VERSION ""

NS_ :

BS_:

BU_: BCM BSM2 CADM2 CVADAS EPS ORC PAM SGW TRSKM

BO_ 1051 BCM_FD_4: 32 BCM
 SG_ ExternalTemperatureAD_Voltage : 159|8@0+ (0.019607843,0) [0|4.98] "Volt" Vector__XXX
 SG_ FUEL_VOLT : 143|8@0+ (0.019607843,0) [0|4.98] "Volt" Vector__XXX

BO_ 1375 BCM_FD_6: 32 BCM
 SG_ ChkFuelLevelSts : 99|3@0+ (1,0) [0|7] "-" Vector__XXX
 SG_ FrontWiperReq : 75|4@0+ (1,0) [0|5] "" Vector__XXX

BO_ 1827 BCM_FD_7: 32 BCM
 SG_ CRC_BCM7 : 191|8@0+ (1,0) [0|255] "-"  BSM2
 SG_ IgnitionOnCounter : 95|16@0+ (1,0) [0|65535] "-"  BSM2,CADM2,CVADAS,EPS,ORC,PAM,TRSKM
 SG_ MessageCounter_BCM7 : 179|4@0+ (1,0) [0|15] "-"  BSM2

BO_ 1066 BCM_FD_9: 32 BCM
 SG_ BonnetSts : 182|1@0+ (1,0) [0|1] "-"  ORC
 SG_ BrakeFluidLevelSts : 181|1@0+ (1,0) [0|1] "-"  BSM2
 SG_ CRC_BCM9 : 191|8@0+ (1,0) [0|255] "-"  CADM2,CVADAS
 SG_ DoorLockLastElSts : 51|2@0+ (1,0) [0|3] ""  ORC
 SG_ DriverDoorSts : 35|1@0+ (1,0) [0|1] "-"  CVADAS,ORC
 SG_ ExternalTemperature : 0|9@0+ (0.5,-85) [-85|170] "°C"  CVADAS,ORC,PAM
 SG_ FrontWiperMoveSts : 60|1@0+ (1,0) [0|1] "" Vector__XXX
 SG_ FuelLevel : 135|8@0+ (1,0) [0|255] "%"  ORC
 SG_ HDCFnRqstSts : 4|2@0+ (1,0) [0|2] ""  ORC
 SG_ HighBeamSts : 97|1@0+ (1,0) [0|1] "-"  ORC
 SG_ LHRDoorSts : 32|1@0+ (1,0) [0|1] "-"  CVADAS,ORC
 SG_ LowBeamSts : 72|1@0+ (1,0) [0|1] ""  ORC
 SG_ LowFuelWarningSts : 47|1@0+ (1,0) [0|1] "-" Vector__XXX
 SG_ MessageCounter_BCM9 : 179|4@0+ (1,0) [0|15] "-"  CADM2,CVADAS
 SG_ ParkBrakeSts : 180|1@0+ (1,0) [0|1] "-"  ORC
 SG_ PowerModeSts : 161|2@0+ (1,0) [0|3] ""  CADM2
 SG_ PsngrDoorSts : 46|1@0+ (1,0) [0|1] "-"  CVADAS,ORC
 SG_ RHatchSts : 43|1@0+ (1,0) [0|1] "-"  CVADAS,ORC,SGW
 SG_ RHRDoorSts : 42|1@0+ (1,0) [0|1] "-"  CVADAS,ORC
 SG_ StopLightFault : 108|1@0+ (1,0) [0|1] "-"  ORC
 SG_ StopLightSts : 88|1@0+ (1,0) [0|1] "-" Vector__XXX

BO_ 513 BRAKE_FD_1: 32 BCM
 SG_ ACCFSafe : 7|8@0+ (1,0) [0|255] "-"  CADM2
 SG_ BrkTrq : 94|15@0+ (3,0) [0|98301] "Nm"  ORC
 SG_ BrkTrq_Driver : 150|15@0+ (3,0) [0|98301] "Nm"  CADM2,ORC
 SG_ CRC_BRAKE1 : 191|8@0+ (1,0) [0|255] "-"  CVADAS,BSM2,CADM2,ORC
 SG_ MessageCounter_BRAKE1 : 179|4@0+ (1,0) [0|15] "-"  CVADAS,BSM2,CADM2,ORC
 SG_ REF_VEH_SPEED : 57|10@0+ (0.5,0) [0|511] "kph"  CVADAS,ORC
 SG_ SelSpdLmp : 59|2@0+ (1,0) [0|0] "-"  ORC
 SG_ VehicleStandStillSts : 111|2@0+ (1,0) [0|2] "-"  BSM2,CADM2,CVADAS

BO_ 258 BRAKE_FD_2: 64 BCM
 SG_ ABSActive : 83|1@0+ (1,0) [0|1] "-"  ORC
 SG_ BrakeBoostPressure : 370|11@0+ (0.1,0) [0|200] "bar"  ORC
 SG_ BrakeInterventionSts : 103|1@0+ (1,0) [0|1] "-"  ORC
 SG_ BrakePedalPressure : 386|11@0+ (0.1,0) [0|200] "bar"  ORC
 SG_ Brk_Stat : 343|2@0+ (1,0) [0|2] "-"  CVADAS,ORC,PAM
 SG_ BSM_ESASystemSts : 239|3@0+ (1,0) [0|6] ""  EPS
 SG_ CRC_BRAKE2 : 447|8@0+ (1,0) [0|255] "-"  BSM2,CADM2,CVADAS,EPS,ORC,PAM
 SG_ ESCActive : 84|1@0+ (1,0) [0|1] "-"  ORC
 SG_ HBAActive : 101|1@0+ (1,0) [0|1] "-"  ORC
 SG_ HillHolderActive : 174|1@0+ (1,0) [0|1] "-"  ORC
 SG_ InternalError_BSM : 191|1@0+ (1,0) [0|1] "-"  CADM2
 SG_ LatAcceleration_BSM : 19|12@0+ (0.02,-40.96) [-40.96|40.92] "m/s^2"  CADM2,CVADAS,EPS,PAM
 SG_ LatAccelerationFailSts_BSM : 68|1@0+ (1,0) [0|1] "-"  PAM
 SG_ LongAcceleration_BSM : 35|12@0+ (0.02,-40.96) [-40.96|40.92] "m/s^2"  CADM2,CVADAS,EPS,PAM
 SG_ LongAccelerationFailSts_BSM : 69|1@0+ (1,0) [0|1] "-"  PAM
 SG_ MessageCounter_BRAKE2 : 435|4@0+ (1,0) [0|15] "-"  BSM2,CADM2,CVADAS,EPS,ORC,PAM
 SG_ VehicleSpeedVSOSig : 4|13@0+ (0.0625,0) [0|511.875] "Km/h"  BSM2,CADM2,CVADAS,EPS,ORC,PAM,TRSKM
 SG_ WheelRPM_FL : 279|16@0+ (0.001953125,0) [0|127.9961] "Rev/s"  EPS
 SG_ WheelRPM_FR : 295|16@0+ (0.001953125,0) [0|127.9961] "Rev/s"  EPS
 SG_ YawRate_BSM : 67|12@0+ (0.08,-163.84) [-163.84|163.68] "deg/s"  CVADAS,EPS,ORC,PAM
 SG_ YawRateFailSts_BSM : 87|1@0+ (1,0) [0|1] "-"  EPS,PAM

BO_ 259 BRAKE_FD_3: 32 BCM
 SG_ CRC__BRAKE3 : 191|8@0+ (1,0) [0|255] "-"  BSM2,CADM2,CVADAS,EPS,ORC,PAM
 SG_ LatAccelerationOffset_BSM : 127|8@0+ (0.02,-2.56) [-2.56|2.52] "m/s^2"  CVADAS
 SG_ LHF_FastPulseCounter : 167|8@0+ (1,0) [0|255] "pulse"  CADM2,CVADAS,EPS,PAM
 SG_ LHF_Spin : 23|2@0+ (1,0) [0|3] "-"  BSM2,CADM2,CVADAS,EPS,PAM
 SG_ LHF_WheelSensorFailSts : 181|1@0+ (1,0) [0|1] "-"  BSM2,CADM2,EPS,ORC,PAM
 SG_ LHFWheelSpeed : 20|13@0+ (0.0625,0) [0|511.875] "Km/h"  BSM2,CADM2,CVADAS,EPS,ORC,PAM
 SG_ LHR_FastPulseCounter : 151|8@0+ (1,0) [0|255] "pulse"  CADM2,CVADAS,EPS,PAM
 SG_ LHR_Spin : 86|2@0+ (1,0) [0|3] "-"  BSM2,CADM2,CVADAS
 SG_ LHR_WheelSensorFailSts : 87|1@0+ (1,0) [0|1] "-"  BSM2,CADM2,EPS,ORC,PAM
 SG_ LHRWheelSpeed : 4|13@0+ (0.0625,0) [0|511.875] "Km/h"  BSM2,CADM2,CVADAS,EPS,ORC,PAM
 SG_ LongAccelerationOffset_BSM : 119|8@0+ (0.02,-2.56) [-2.56|2.52] "m/s^2"  CVADAS
 SG_ MessageCounter_BRAKE3 : 179|4@0+ (1,0) [0|15] "-"  BSM2,CADM2,CVADAS,EPS,ORC,PAM
 SG_ RHF_FastPulseCounter : 175|8@0+ (1,0) [0|255] "pulse"  CADM2,CVADAS,EPS,PAM
 SG_ RHF_Spin : 7|2@0+ (1,0) [0|3] "-"  BSM2,CADM2,CVADAS,EPS,PAM
 SG_ RHF_WheelSensorFailSts : 182|1@0+ (1,0) [0|1] "-"  BSM2,CADM2,EPS,ORC,PAM
 SG_ RHFWheelSpeed : 52|13@0+ (0.0625,0) [0|511.875] "Km/h"  BSM2,CADM2,CVADAS,EPS,ORC,PAM
 SG_ RHR_FastPulseCounter : 159|8@0+ (1,0) [0|255] "pulse"  CADM2,CVADAS,EPS,PAM
 SG_ RHR_Spin : 102|2@0+ (1,0) [0|3] "-"  BSM2,CADM2,CVADAS
 SG_ RHR_WheelSensorFailSts : 103|1@0+ (1,0) [0|1] "-"  BSM2,CADM2,EPS,ORC,PAM
 SG_ RHRWheelSpeed : 68|13@0+ (0.0625,0) [0|511.875] "Km/h"  BSM2,CADM2,CVADAS,EPS,ORC,PAM

BO_ 609 BRAKE_FD_4: 32 BCM
 SG_ ClampForce : 88|9@0+ (0.1,-0.1) [0|51] "KN"  ORC
 SG_ CRC_BRAKE4 : 191|8@0+ (1,0) [0|255] "-"  CVADAS,BSM2,CADM2
 SG_ EPBSts : 115|4@0+ (1,0) [0|14] "-"  BSM2,CADM2,CVADAS,EPS,ORC,PAM
 SG_ EPBSwitchPosition : 119|2@0+ (1,0) [0|3] "-"  ORC
 SG_ EPBWarningLampReq : 174|2@0+ (1,0) [0|0] "-"  ORC
 SG_ ESC_OFF_Hrd_Sft_Button_sts : 151|3@0+ (1,0) [0|6] "-"  ORC
 SG_ MessageCounter_BRAKE4 : 179|4@0+ (1,0) [0|15] "-"  CVADAS,BSM2,CADM2
 SG_ MSRActive : 92|1@0+ (1,0) [0|1] "-"  ORC

BO_ 1155 BRAKE_FD_5: 32 BCM
 SG_ ABSFailSts : 87|1@0+ (1,0) [0|1] "-"  ORC
 SG_ BSM_THA_Brk_Resp : 15|2@0+ (1,0) [0|3] "-"  CVADAS
 SG_ CRC_BRAKE5 : 191|8@0+ (1,0) [0|255] "-"  CVADAS
 SG_ EBDFailSts : 84|1@0+ (1,0) [0|1] "-"  ORC
 SG_ ERMActive : 111|1@0+ (1,0) [0|1] "-"  ORC
 SG_ ESCFailSts : 83|1@0+ (1,0) [0|1] "-"  ORC
 SG_ ESCIntervention : 82|1@0+ (1,0) [0|1] "-"  ORC
 SG_ Function2Sts : 94|1@0+ (1,0) [0|1] "-"  ORC
 SG_ MessageCounter_BRAKE5 : 179|4@0+ (1,0) [0|15] "-"  CVADAS
 SG_ TSCActive : 110|1@0+ (1,0) [0|1] "-"  ORC

BO_ 514 BRAKE_FD_7: 32 BCM
 SG_ BrakePdlPosn : 63|8@0+ (0.4,0) [0|100] "%"  ORC
 SG_ BrkPdl_Flt : 86|1@0+ (1,0) [0|1] "-"  ORC
 SG_ BrkPdl_Stat : 85|2@0+ (1,0) [0|2] "-"  BSM2,CADM2,ORC
 SG_ BSM_OpStat : 74|3@0+ (1,0) [0|5] ""  BSM2
 SG_ BSM_ReadyForESS : 181|2@0+ (1,0) [0|2] "-"  ORC
 SG_ CRC_BRAKE7 : 191|8@0+ (1,0) [0|255] "-"  BSM2,CADM2
 SG_ MessageCounter_BRAKE7 : 179|4@0+ (1,0) [0|15] "-"  BSM2,CADM2
 SG_ PAM_Brk_Rq_RspSts : 28|2@0+ (1,0) [0|3] "-"  PAM
 SG_ Rear_Diff_BSM_RQ : 77|2@0+ (1,0) [0|2] "-"  ORC

BO_ 257 BRAKE2_FD_1: 64 BSM2
 SG_ ABSActive_B2 : 37|1@0+ (1,0) [0|1] ""  CADM2
 SG_ Brk_Stat_B2 : 71|2@0+ (1,0) [0|2] ""  BCM,CADM2
 SG_ CRC_BRAKE2_1 : 447|8@0+ (1,0) [0|255] "-"  BCM,CADM2,CVADAS,EPS,ORC
 SG_ Ft_RrAxleCoupling_TrqRq_B2 : 143|8@0+ (12,0) [0|3060] "Nm"  BCM
 SG_ Ft_RrTrqCoupling_ModeRq_B2 : 158|2@0+ (1,0) [0|3] "-"  BCM
 SG_ Inlet_Pressure_Pos : 98|2@0+ (1,0) [0|2] ""  CADM2
 SG_ LHF_FastPulseCounter_B2 : 87|8@0+ (1,0) [0|255] "pulse"  CADM2
 SG_ LHF_Spin_B2 : 39|2@0+ (1,0) [0|3] ""  CADM2
 SG_ LHF_WheelSensorFailSts_B2 : 53|1@0+ (1,0) [0|1] ""  CADM2
 SG_ LHFWheelSpeed_B2 : 52|13@0+ (0.0625,0) [0|511.875] "Km/h"  CADM2
 SG_ MessageCounter_BRAKE2_1 : 435|4@0+ (1,0) [0|15] "-"  BCM,CADM2,CVADAS,EPS,ORC
 SG_ R_DIFF_TRQ_RQ_B2 : 151|9@0+ (10,0) [0|5100] "Nm" Vector__XXX
 SG_ Rear_Diff_BSM_RQ_B2 : 156|2@0+ (1,0) [0|2] "-" Vector__XXX
 SG_ RHF_FastPulseCounter_B2 : 95|8@0+ (1,0) [0|255] "pulse"  CADM2
 SG_ RHF_Spin_B2 : 55|2@0+ (1,0) [0|3] ""  CADM2
 SG_ RHF_WheelSensorFailSts_B2 : 69|1@0+ (1,0) [0|1] ""  CADM2
 SG_ RHFWheelSpeed_B2 : 68|13@0+ (0.0625,0) [0|511.875] "Km/h"  CADM2
 SG_ VehicleSpeedVSOSig_B2 : 36|13@0+ (0.0625,0) [0|511.875] "Km/h"  CADM2,EPS

BO_ 524 BRAKE2_FD_2: 32 BSM2
 SG_ AEB_Type_Brk_B2 : 43|4@0+ (1,0) [0|15] ""  CADM2
 SG_ Brake_OpStat_Sec : 53|3@0+ (1,0) [0|5] ""  BCM,CADM2,ORC
 SG_ BrkTrq_B2 : 6|15@0+ (3,0) [0|98301] "Nm"  CADM2
 SG_ BSM2_Long_DTO : 23|1@0+ (1,0) [0|1] ""  CADM2
 SG_ BSM2_OpStat : 50|3@0+ (1,0) [0|5] ""  BCM,CADM2
 SG_ CRC_BRAKE2_2 : 191|8@0+ (1,0) [0|255] "-"  BCM,CADM2,ORC
 SG_ MessageCounter_BRAKE2_2 : 179|4@0+ (1,0) [0|15] "-"  BCM,CADM2,ORC
 SG_ VehicleStandStillSts_B2 : 47|2@0+ (1,0) [0|2] ""  BCM,CADM2

BO_ 1156 BRAKE2_FD_3: 32 BSM2
 SG_ ABSFailSts_B2 : 7|1@0+ (1,0) [0|1] ""  CADM2
 SG_ CRC_BRAKE2_3 : 191|8@0+ (1,0) [0|255] "-"  CADM2,ORC
 SG_ MessageCounter_BRAKE2_3 : 179|4@0+ (1,0) [0|15] "-"  CADM2,ORC
 SG_ RollsModeAct_B2 : 6|1@0+ (1,0) [0|1] ""  CADM2

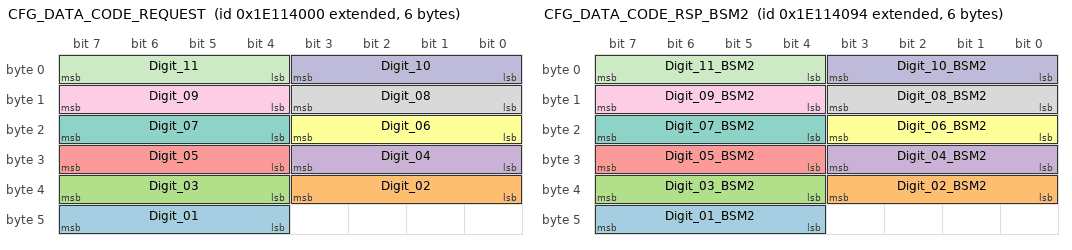
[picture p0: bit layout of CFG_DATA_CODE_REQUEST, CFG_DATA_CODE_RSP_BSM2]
BO_ 2651930624 CFG_DATA_CODE_REQUEST: 6 BCM
 SG_ Digit_01 : 47|4@0+ (1,0) [0|15] ""  BSM2,CADM2,CVADAS,EPS,ORC,PAM,TRSKM
 SG_ Digit_02 : 35|4@0+ (1,0) [0|15] ""  BSM2,CADM2,CVADAS,EPS,ORC,PAM,TRSKM
 SG_ Digit_03 : 39|4@0+ (1,0) [0|15] ""  BSM2,CADM2,CVADAS,EPS,ORC,PAM,TRSKM
 SG_ Digit_04 : 27|4@0+ (1,0) [0|15] ""  BSM2,CADM2,CVADAS,EPS,ORC,PAM,TRSKM
 SG_ Digit_05 : 31|4@0+ (1,0) [0|15] ""  BSM2,CADM2,CVADAS,EPS,ORC,PAM,TRSKM
 SG_ Digit_06 : 19|4@0+ (1,0) [0|15] ""  BSM2,CADM2,CVADAS,EPS,ORC,PAM,TRSKM
 SG_ Digit_07 : 23|4@0+ (1,0) [0|15] ""  BSM2,CADM2,CVADAS,EPS,ORC,PAM,TRSKM
 SG_ Digit_08 : 11|4@0+ (1,0) [0|15] ""  BSM2,CADM2,CVADAS,EPS,ORC,PAM,TRSKM
 SG_ Digit_09 : 15|4@0+ (1,0) [0|15] ""  BSM2,CADM2,CVADAS,EPS,ORC,PAM,TRSKM
 SG_ Digit_10 : 3|4@0+ (1,0) [0|15] ""  BSM2,CADM2,CVADAS,EPS,ORC,PAM,TRSKM
 SG_ Digit_11 : 7|4@0+ (1,0) [0|15] ""  BSM2,CADM2,CVADAS,EPS,ORC,PAM,TRSKM

BO_ 2651930772 CFG_DATA_CODE_RSP_BSM2: 6 BSM2
 SG_ Digit_01_BSM2 : 47|4@0+ (1,0) [0|15] "-"  BCM
 SG_ Digit_02_BSM2 : 35|4@0+ (1,0) [0|15] "-"  BCM
 SG_ Digit_03_BSM2 : 39|4@0+ (1,0) [0|15] "-"  BCM
 SG_ Digit_04_BSM2 : 27|4@0+ (1,0) [0|15] "-"  BCM
 SG_ Digit_05_BSM2 : 31|4@0+ (1,0) [0|15] "-"  BCM
 SG_ Digit_06_BSM2 : 19|4@0+ (1,0) [0|15] "-"  BCM
 SG_ Digit_07_BSM2 : 23|4@0+ (1,0) [0|15] "-"  BCM
 SG_ Digit_08_BSM2 : 11|4@0+ (1,0) [0|15] "-"  BCM
 SG_ Digit_09_BSM2 : 15|4@0+ (1,0) [0|15] "-"  BCM
 SG_ Digit_10_BSM2 : 3|4@0+ (1,0) [0|15] "-"  BCM
 SG_ Digit_11_BSM2 : 7|4@0+ (1,0) [0|15] "-"  BCM

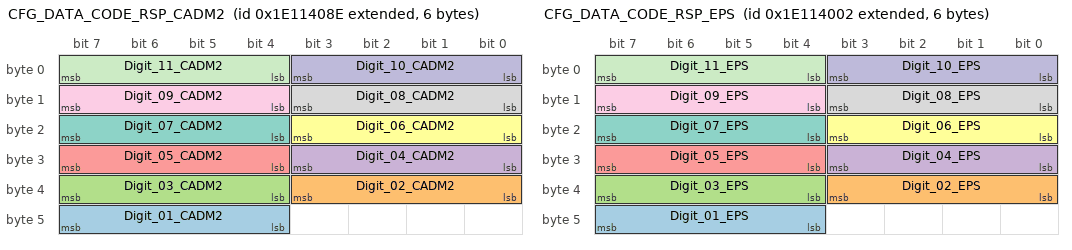
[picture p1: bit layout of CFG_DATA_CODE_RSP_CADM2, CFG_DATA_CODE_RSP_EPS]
BO_ 2651930766 CFG_DATA_CODE_RSP_CADM2: 6 CADM2
 SG_ Digit_01_CADM2 : 47|4@0+ (1,0) [0|15] "-"  BCM
 SG_ Digit_02_CADM2 : 35|4@0+ (1,0) [0|15] "-"  BCM
 SG_ Digit_03_CADM2 : 39|4@0+ (1,0) [0|15] "-"  BCM
 SG_ Digit_04_CADM2 : 27|4@0+ (1,0) [0|15] "-"  BCM
 SG_ Digit_05_CADM2 : 31|4@0+ (1,0) [0|15] "-"  BCM
 SG_ Digit_06_CADM2 : 19|4@0+ (1,0) [0|15] "-"  BCM
 SG_ Digit_07_CADM2 : 23|4@0+ (1,0) [0|15] "-"  BCM
 SG_ Digit_08_CADM2 : 11|4@0+ (1,0) [0|15] "-"  BCM
 SG_ Digit_09_CADM2 : 15|4@0+ (1,0) [0|15] "-"  BCM
 SG_ Digit_10_CADM2 : 3|4@0+ (1,0) [0|15] "-"  BCM
 SG_ Digit_11_CADM2 : 7|4@0+ (1,0) [0|15] "-"  BCM

BO_ 2651930626 CFG_DATA_CODE_RSP_EPS: 6 EPS
 SG_ Digit_01_EPS : 47|4@0+ (1,0) [0|15] "-"  BCM
 SG_ Digit_02_EPS : 35|4@0+ (1,0) [0|15] "-"  BCM
 SG_ Digit_03_EPS : 39|4@0+ (1,0) [0|15] "-"  BCM
 SG_ Digit_04_EPS : 27|4@0+ (1,0) [0|15] "-"  BCM
 SG_ Digit_05_EPS : 31|4@0+ (1,0) [0|15] "-"  BCM
 SG_ Digit_06_EPS : 19|4@0+ (1,0) [0|15] "-"  BCM
 SG_ Digit_07_EPS : 23|4@0+ (1,0) [0|15] "-"  BCM
 SG_ Digit_08_EPS : 11|4@0+ (1,0) [0|15] "-"  BCM
 SG_ Digit_09_EPS : 15|4@0+ (1,0) [0|15] "-"  BCM
 SG_ Digit_10_EPS : 3|4@0+ (1,0) [0|15] "-"  BCM
 SG_ Digit_11_EPS : 7|4@0+ (1,0) [0|15] "-"  BCM

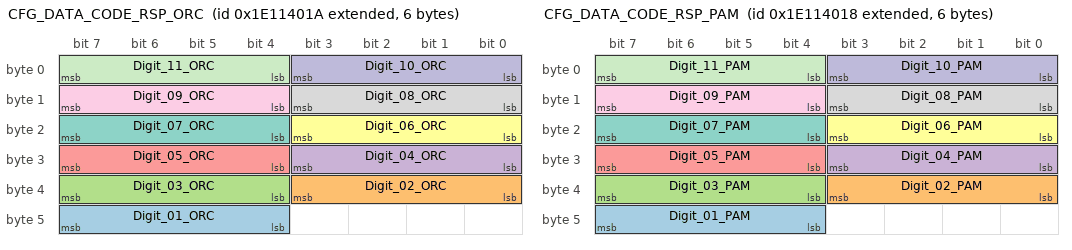
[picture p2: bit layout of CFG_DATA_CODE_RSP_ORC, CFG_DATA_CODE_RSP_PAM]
BO_ 2651930650 CFG_DATA_CODE_RSP_ORC: 6 ORC
 SG_ Digit_01_ORC : 47|4@0+ (1,0) [0|15] "-"  BCM
 SG_ Digit_02_ORC : 35|4@0+ (1,0) [0|15] "-"  BCM
 SG_ Digit_03_ORC : 39|4@0+ (1,0) [0|15] "-"  BCM
 SG_ Digit_04_ORC : 27|4@0+ (1,0) [0|15] "-"  BCM
 SG_ Digit_05_ORC : 31|4@0+ (1,0) [0|15] "-"  BCM
 SG_ Digit_06_ORC : 19|4@0+ (1,0) [0|15] "-"  BCM
 SG_ Digit_07_ORC : 23|4@0+ (1,0) [0|15] "-"  BCM
 SG_ Digit_08_ORC : 11|4@0+ (1,0) [0|15] "-"  BCM
 SG_ Digit_09_ORC : 15|4@0+ (1,0) [0|15] "-"  BCM
 SG_ Digit_10_ORC : 3|4@0+ (1,0) [0|15] "-"  BCM
 SG_ Digit_11_ORC : 7|4@0+ (1,0) [0|15] "-"  BCM

BO_ 2651930648 CFG_DATA_CODE_RSP_PAM: 6 CVADAS
 SG_ Digit_01_PAM : 47|4@0+ (1,0) [0|15] "-"  BCM
 SG_ Digit_02_PAM : 35|4@0+ (1,0) [0|15] "-"  BCM
 SG_ Digit_03_PAM : 39|4@0+ (1,0) [0|15] "-"  BCM
 SG_ Digit_04_PAM : 27|4@0+ (1,0) [0|15] "-"  BCM
 SG_ Digit_05_PAM : 31|4@0+ (1,0) [0|15] "-"  BCM
 SG_ Digit_06_PAM : 19|4@0+ (1,0) [0|15] "-"  BCM
 SG_ Digit_07_PAM : 23|4@0+ (1,0) [0|15] "-"  BCM
 SG_ Digit_08_PAM : 11|4@0+ (1,0) [0|15] "-"  BCM
 SG_ Digit_09_PAM : 15|4@0+ (1,0) [0|15] "-"  BCM
 SG_ Digit_10_PAM : 3|4@0+ (1,0) [0|15] "-"  BCM
 SG_ Digit_11_PAM : 7|4@0+ (1,0) [0|15] "-"  BCM

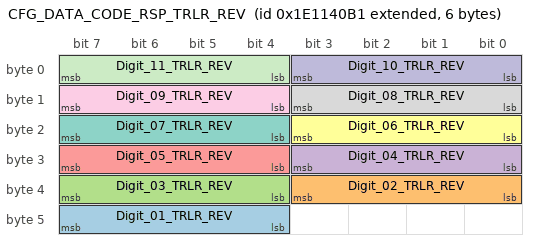
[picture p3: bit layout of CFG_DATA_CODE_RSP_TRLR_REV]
BO_ 2651930801 CFG_DATA_CODE_RSP_TRLR_REV: 6 TRSKM
 SG_ Digit_01_TRLR_REV : 47|4@0+ (1,0) [0|15] "-"  BCM
 SG_ Digit_02_TRLR_REV : 35|4@0+ (1,0) [0|15] "-"  BCM
 SG_ Digit_03_TRLR_REV : 39|4@0+ (1,0) [0|15] "-"  BCM
 SG_ Digit_04_TRLR_REV : 27|4@0+ (1,0) [0|15] "-"  BCM
 SG_ Digit_05_TRLR_REV : 31|4@0+ (1,0) [0|15] "-"  BCM
 SG_ Digit_06_TRLR_REV : 19|4@0+ (1,0) [0|15] "-"  BCM
 SG_ Digit_07_TRLR_REV : 23|4@0+ (1,0) [0|15] "-"  BCM
 SG_ Digit_08_TRLR_REV : 11|4@0+ (1,0) [0|15] "-"  BCM
 SG_ Digit_09_TRLR_REV : 15|4@0+ (1,0) [0|15] "-"  BCM
 SG_ Digit_10_TRLR_REV : 3|4@0+ (1,0) [0|15] "-"  BCM
 SG_ Digit_11_TRLR_REV : 7|4@0+ (1,0) [0|15] "-"  BCM

BO_ 275 CVPAM_FD_Control: 32 CVADAS
 SG_ CRC_CVPAM_FD_Control : 191|8@0+ (1,0) [0|255] "-"  BCM
 SG_ MessageCounter_CVPAM_FD_Control : 179|4@0+ (1,0) [0|15] "-"  BCM
 SG_ PPPA_TurnIndicatorRqst : 166|2@0+ (1,0) [0|2] "-"  BCM
 SG_ RR_PAM_Brk_RqSts : 150|1@0+ (1,0) [0|1] "-"  BCM
 SG_ RR_PAM_Dist : 161|10@0+ (1,0) [0|1022] "cm"  BCM
 SG_ RR_PAM_StopControlSts : 151|1@0+ (1,0) [0|1] "-"  BCM

BO_ 950 CVPAM_FD_Info: 32 CVADAS
 SG_ Alert_CHF : 103|3@0+ (1,0) [0|7] "-"  BCM
 SG_ Alert_CHR : 114|3@0+ (1,0) [0|7] "-"  BCM
 SG_ Alert_LHF : 100|3@0+ (1,0) [0|7] "-"  BCM
 SG_ Alert_LHR : 111|3@0+ (1,0) [0|7] "-"  BCM
 SG_ Alert_RHF : 95|3@0+ (1,0) [0|7] "-"  BCM
 SG_ Alert_RHR : 108|3@0+ (1,0) [0|7] "-"  BCM
 SG_ AUXCamsRQSts : 5|1@0+ (1,0) [0|1] ""  SGW
 SG_ ChimeActivation_LHF : 96|1@0+ (1,0) [0|1] "-"  BCM,SGW
 SG_ ChimeActivation_LHR : 104|1@0+ (1,0) [0|1] "-"  BCM
 SG_ ChimeActivation_RHF : 97|1@0+ (1,0) [0|1] "-"  BCM,SGW
 SG_ ChimeActivation_RHR : 105|1@0+ (1,0) [0|1] "-"  BCM
 SG_ CRC_CVPAM_FD_Info : 191|8@0+ (1,0) [0|255] "-"  BCM,TRSKM
 SG_ DisplayView2 : 159|4@0+ (1,0) [0|15] "-"  SGW
 SG_ FrontSensorSts : 145|2@0+ (1,0) [0|3] "-"  BCM,SGW
 SG_ FT_PAM_LedControlSts : 3|2@0+ (1,0) [0|2] "-"  BCM
 SG_ Graphic_CHF : 133|2@0+ (1,0) [0|3] "-"  BCM
 SG_ Graphic_CHR : 139|2@0+ (1,0) [0|3] "-"  BCM
 SG_ Graphic_LHF : 131|2@0+ (1,0) [0|3] "-"  BCM
 SG_ Graphic_LHR : 137|2@0+ (1,0) [0|3] "-"  BCM
 SG_ Graphic_RHF : 129|2@0+ (1,0) [0|3] "-"  BCM
 SG_ Graphic_RHR : 135|2@0+ (1,0) [0|3] "-"  BCM
 SG_ HMICode : 175|8@0+ (1,0) [0|255] "-"  BCM
 SG_ ImageDefeatRQSts : 89|1@0+ (1,0) [0|1] "-"  SGW
 SG_ MessageCounter_CVPAM_FD_Info : 179|4@0+ (1,0) [0|15] "-"  BCM,TRSKM
 SG_ MoreCamsRQSts : 4|1@0+ (1,0) [0|1] ""  SGW
 SG_ PAM_CHIME_REP_RATESts : 151|4@0+ (1,0) [0|15] "-"  BCM
 SG_ PAM_CHIME_TYPE : 155|4@0+ (1,0) [0|15] "-"  BCM
 SG_ PAM_LedControlSts : 143|2@0+ (1,0) [0|3] "-"  BCM
 SG_ PAM_Off_Status : 92|1@0+ (1,0) [0|1] "-"  SGW
 SG_ PAM_Off_Status_2BT : 1|2@0+ (1,0) [0|3] "-"  BCM,SGW
 SG_ PAM_PopUpRqst : 167|8@0+ (1,0) [0|255] "-"  BCM
 SG_ PAM_Volume : 119|2@0+ (1,0) [0|3] "-"  BCM
 SG_ PAMSystemFault : 181|2@0+ (1,0) [0|3] "-"  BCM
 SG_ ParkingManeuverActive : 66|3@0+ (1,0) [0|6] "-"  BCM
 SG_ RearSensorSts : 147|2@0+ (1,0) [0|3] "-"  BCM,SGW
 SG_ SPM_LedControlSts : 141|2@0+ (1,0) [0|3] "-"  BCM,ORC
 SG_ SPM_Screen_Rqst : 90|1@0+ (1,0) [0|1] "-"  SGW
 SG_ SPMControlSts : 183|2@0+ (1,0) [0|1] "-"  BCM,ORC,SGW
 SG_ SPMFailSts : 117|1@0+ (1,0) [0|1] "-"  ORC
 SG_ SPMSystemFault : 91|1@0+ (1,0) [0|1] "-" Vector__XXX
 SG_ TRSC_LED_Stat : 79|2@0+ (1,0) [0|2] "-"  TRSKM

BO_ 161 DBSM2_A1: 32 BCM
 SG_ BATTERY_voltage : 15|8@0+ (0.05,6) [6|18.7] "" Vector__XXX
 SG_ BATTERY2_voltage : 23|8@0+ (0.05,6) [6|18.7] "" Vector__XXX
 SG_ CRC_DBSM2_1 : 63|8@0+ (1,0) [0|0] ""  CADM2
 SG_ DBSM2_internal_error : 3|1@0+ (1,0) [0|1] ""  CADM2
 SG_ ESS_input_active : 1|1@0+ (1,0) [0|1] "" Vector__XXX
 SG_ L2plus_ack : 6|1@0+ (1,0) [0|1] "" Vector__XXX
 SG_ MC_DBSM2_1 : 55|4@0+ (1,0) [0|15] ""  CADM2
 SG_ overcurrent_detected : 4|1@0+ (1,0) [0|1] ""  CADM2
 SG_ overtemp_detected : 2|1@0+ (1,0) [0|1] ""  CADM2
 SG_ RsErr_DBSM2 : 7|1@0+ (1,0) [0|1] ""  CADM2
 SG_ switch_status_OpenClose : 0|1@0+ (1,0) [0|1] ""  CADM2
 SG_ undervoltage_detected : 5|1@0+ (1,0) [0|1] ""  CADM2

BO_ 2564432881 DIAGNOSTIC_REQUEST_BSM2: 8 SGW
 SG_ N_PDU : 7|64@0+ (1,0) [0|0] ""  BSM2

BO_ 2564435953 DIAGNOSTIC_REQUEST_CADM2: 8 SGW
 SG_ N_PDU : 7|64@0+ (1,0) [0|0] ""  CADM2

BO_ 2564436209 DIAGNOSTIC_REQUEST_EPS: 8 SGW
 SG_ N_PDU : 7|64@0+ (1,0) [0|0] ""  EPS

BO_ 2564432882 DIAGNOSTIC_REQUEST_FD_BSM2: 64 SGW
 SG_ N_PDU : 7|64@0+ (1,0) [0|0] ""  BSM2

BO_ 2564435954 DIAGNOSTIC_REQUEST_FD_CADM2: 64 SGW
 SG_ N_PDU : 7|64@0+ (1,0) [0|0] ""  CADM2

BO_ 2564436210 DIAGNOSTIC_REQUEST_FD_EPS: 64 SGW
 SG_ N_PDU : 7|64@0+ (1,0) [0|0] ""  EPS

BO_ 2564554482 DIAGNOSTIC_REQUEST_FD_FUNCTIONAL: 64 SGW
 SG_ N_PDU : 7|64@0+ (1,0) [0|0] ""  BSM2,CVADAS,EPS,ORC,PAM,TRSKM

BO_ 2564473074 DIAGNOSTIC_REQUEST_FD_ORC: 64 SGW
 SG_ N_PDU : 7|64@0+ (1,0) [0|0] ""  ORC

BO_ 2564464882 DIAGNOSTIC_REQUEST_FD_PAM: 64 SGW
 SG_ N_PDU : 7|64@0+ (1,0) [0|0] ""  CVADAS,PAM

BO_ 2564484338 DIAGNOSTIC_REQUEST_FD_TRLR_REV: 64 SGW
 SG_ N_PDU : 7|64@0+ (1,0) [0|0] ""  TRSKM

BO_ 2564435957 DIAGNOSTIC_REQUEST_FOTA_CADM2: 64 SGW
 SG_ N_PDU : 7|64@0+ (1,0) [0|0] ""  CADM2

BO_ 2564436213 DIAGNOSTIC_REQUEST_FOTA_EPS: 64 SGW
 SG_ N_PDU : 7|64@0+ (1,0) [0|0] ""  EPS

BO_ 2564473077 DIAGNOSTIC_REQUEST_FOTA_ORC: 64 SGW
 SG_ N_PDU : 7|64@0+ (1,0) [0|0] ""  ORC

BO_ 2564554485 DIAGNOSTIC_REQUEST_FUNC_FOTA: 64 SGW
 SG_ N_PDU : 7|64@0+ (1,0) [0|0] ""  BSM2,CADM2,CVADAS,EPS,ORC,PAM,TRSKM

BO_ 2564502513 DIAGNOSTIC_REQUEST_FUNC_OBD: 8 SGW
 SG_ N_PDU : 7|64@0+ (1,0) [0|0] "" Vector__XXX

BO_ 2564554481 DIAGNOSTIC_REQUEST_FUNCTIONAL: 8 SGW
 SG_ N_PDU : 7|64@0+ (1,0) [0|0] ""  BSM2,CVADAS,EPS,ORC,PAM,TRSKM

BO_ 2564473073 DIAGNOSTIC_REQUEST_ORC: 8 SGW
 SG_ N_PDU : 7|64@0+ (1,0) [0|0] ""  ORC

BO_ 2564464881 DIAGNOSTIC_REQUEST_PAM: 8 SGW
 SG_ N_PDU : 7|64@0+ (1,0) [0|0] ""  CVADAS,PAM

BO_ 2564484337 DIAGNOSTIC_REQUEST_TRLR_REV: 8 SGW
 SG_ N_PDU : 7|64@0+ (1,0) [0|0] ""  TRSKM

BO_ 2564485411 DIAGNOSTIC_RESPONSE_BSM2: 8 BSM2
 SG_ N_PDU : 7|64@0+ (1,0) [0|0] ""  SGW

BO_ 2564485423 DIAGNOSTIC_RESPONSE_CADM2: 8 CADM2
 SG_ N_PDU : 7|64@0+ (1,0) [0|0] ""  SGW

BO_ 2564485424 DIAGNOSTIC_RESPONSE_EPS: 8 EPS
 SG_ N_PDU : 7|64@0+ (1,0) [0|0] ""  SGW

BO_ 2564485667 DIAGNOSTIC_RESPONSE_FD_BSM2: 64 BSM2
 SG_ N_PDU : 7|64@0+ (1,0) [0|0] ""  SGW

BO_ 2564485679 DIAGNOSTIC_RESPONSE_FD_CADM2: 64 CADM2
 SG_ N_PDU : 7|64@0+ (1,0) [0|0] ""  SGW

BO_ 2564485680 DIAGNOSTIC_RESPONSE_FD_EPS: 64 EPS
 SG_ N_PDU : 7|64@0+ (1,0) [0|0] ""  SGW

BO_ 2564485824 DIAGNOSTIC_RESPONSE_FD_ORC: 64 ORC
 SG_ N_PDU : 7|64@0+ (1,0) [0|0] ""  SGW

BO_ 2564485792 DIAGNOSTIC_RESPONSE_FD_PAM: 64 CVADAS
 SG_ N_PDU : 7|64@0+ (1,0) [0|0] ""  SGW

BO_ 2564485868 DIAGNOSTIC_RESPONSE_FD_TRLR_REV: 64 TRSKM
 SG_ N_PDU : 7|64@0+ (1,0) [0|0] ""  SGW

BO_ 2564486447 DIAGNOSTIC_RESPONSE_FOTA_CADM2: 64 CADM2
 SG_ N_PDU : 7|64@0+ (1,0) [0|0] ""  SGW

BO_ 2564486448 DIAGNOSTIC_RESPONSE_FOTA_EPS: 64 EPS
 SG_ N_PDU : 7|64@0+ (1,0) [0|0] ""  SGW

BO_ 2564486592 DIAGNOSTIC_RESPONSE_FOTA_ORC: 64 ORC
 SG_ N_PDU : 7|64@0+ (1,0) [0|0] ""  SGW

BO_ 2564485568 DIAGNOSTIC_RESPONSE_ORC: 8 ORC
 SG_ N_PDU : 7|64@0+ (1,0) [0|0] ""  SGW

BO_ 2564485536 DIAGNOSTIC_RESPONSE_PAM: 8 CVADAS
 SG_ N_PDU : 7|64@0+ (1,0) [0|0] ""  SGW

BO_ 2564485612 DIAGNOSTIC_RESPONSE_TRLR_REV: 8 TRSKM
 SG_ N_PDU : 7|64@0+ (1,0) [0|0] ""  SGW

BO_TX_BU_ 2651930648 : CVADAS,PAM;
BO_TX_BU_ 275 : CVADAS,PAM;
BO_TX_BU_ 950 : CVADAS,PAM;
BO_TX_BU_ 2564485792 : CVADAS,PAM;
BO_TX_BU_ 2564485536 : CVADAS,PAM;
CM_ SG_ 1051 ExternalTemperatureAD_Voltage "Indicates the raw voltage of the ambient temp sensor";
CM_ SG_ 1051 FUEL_VOLT "Used to give information about the not filtered fuell level value in volt.";
CM_ SG_ 1375 ChkFuelLevelSts "Used to give information about the diagnostic of CILC.";
CM_ SG_ 1827 CRC_BCM7 "CRC according to SAE J1850 standard at each frame transmission.";
CM_ SG_ 1827 MessageCounter_BCM7 "This signal is a counter used for safety checks strategies. This counter is incremented of 1 (one) unit at each frame transmission.";
CM_ SG_ 1066 BonnetSts "Used to indicate the status of the bonnet";
CM_ SG_ 1066 CRC_BCM9 "CRC according to SAE J1850 standard at each frame transmission.";
CM_ SG_ 1066 DoorLockLastElSts "Reports the last knonw eletrical request for the doors to lock or unlock.";
CM_ SG_ 1066 DriverDoorSts "Used to indicate the status of driver door";
CM_ SG_ 1066 FrontWiperMoveSts "This signal indicates the position of the front wiper (contact cam open or close).";
CM_ SG_ 1066 FuelLevel "Used to give information about the percentage of the fuel level present in the tank.";
CM_ SG_ 1066 HDCFnRqstSts "This signal is used by BCM to inicate the status of HDC switch";
CM_ SG_ 1066 LHRDoorSts "Used to indicate the status of left rear door";
CM_ SG_ 1066 LowFuelWarningSts "Used to give information about the status of the low fuel warning.";
CM_ SG_ 1066 MessageCounter_BCM9 "This signal is a counter used for safety checks strategies. This counter is incremented of 1 (one) unit at each frame transmission.";
CM_ SG_ 1066 ParkBrakeSts "Status of Park Brake";
CM_ SG_ 1066 PsngrDoorSts "Used to indicate the status of passenger door";
CM_ SG_ 1066 RHatchSts "Used to indicate the status of the trunk liftgate";
CM_ SG_ 1066 RHRDoorSts "Used to indicate the status of right rear door";
CM_ SG_ 1066 StopLightSts "Request of Stop Lights activation";
CM_ SG_ 513 ACCFSafe "0";
CM_ SG_ 513 BrkTrq "0";
CM_ SG_ 513 BrkTrq_Driver "0";
CM_ SG_ 513 CRC_BRAKE1 "CRC according to SAE J1850 standard at each frame transmission.";
CM_ SG_ 513 MessageCounter_BRAKE1 "This signal is a counter used for safety checks strategies. This counter is incremented of 1 (one) unit at each frame transmission.";
CM_ SG_ 513 REF_VEH_SPEED "0";
CM_ SG_ 513 SelSpdLmp "Select speed lamp status";
CM_ SG_ 513 VehicleStandStillSts "This signal indicates if the car is in stand still condition";
CM_ SG_ 258 ABSActive "This signal is set to Active when the ABS functionality is active.";
CM_ SG_ 258 BrakeBoostPressure "Pressure Information from Brake Booster Pressure Sensor";
CM_ SG_ 258 BrakeInterventionSts "This signal is ?active? when the brake intervention is due to BSM events and ?not active? when the brake intervention is due to the driver";
CM_ SG_ 258 BrakePedalPressure "Pressure Information from Brake Pedal Simulator Pressure Sensor";
CM_ SG_ 258 Brk_Stat "Brake state";
CM_ SG_ 258 BSM_ESASystemSts "Brake System ESA Status";
CM_ SG_ 258 CRC_BRAKE2 "CRC according to SAE J1850 standard at each frame transmission.";
CM_ SG_ 258 ESCActive "This signal is set to Active when the brake intervention by ESC is active.";
CM_ SG_ 258 HBAActive "0";
CM_ SG_ 258 HillHolderActive "0";
CM_ SG_ 258 InternalError_BSM "This signal indicates if an internal error has been processed";
CM_ SG_ 258 LatAcceleration_BSM "This signal indicates the Lateral Acceleration Value";
CM_ SG_ 258 LatAccelerationFailSts_BSM "This signal indicates the status of Lateral Acceleration Signal";
CM_ SG_ 258 LongAcceleration_BSM "This signal indicates the Longitudinal Acceleration Value";
CM_ SG_ 258 LongAccelerationFailSts_BSM "This signal indicates the status of Longitudinal acceleration signal";
CM_ SG_ 258 MessageCounter_BRAKE2 "This signal is a counter used for safety checks strategies. This counter is incremented of 1 (one) unit at each frame transmission.";
CM_ SG_ 258 VehicleSpeedVSOSig "It is the average vehicle speed calculated.";
CM_ SG_ 258 WheelRPM_FL "Wheel RPM front left";
CM_ SG_ 258 WheelRPM_FR "Wheel RPM front right";
CM_ SG_ 258 YawRate_BSM "This signal indicates the Yaw Rate Value";
CM_ SG_ 258 YawRateFailSts_BSM "This signal indicates the Status of Yaw Rate Signal";
CM_ SG_ 259 CRC__BRAKE3 "CRC according to SAE J1850 standard at each frame transmission.";
CM_ SG_ 259 LatAccelerationOffset_BSM "LatAccelerationOffset_BSM";
CM_ SG_ 259 LHF_FastPulseCounter "This signal is the left front wheel pulse counter.";
CM_ SG_ 259 LHF_Spin "This signal indicates the left hand front wheel status";
CM_ SG_ 259 LHF_WheelSensorFailSts "This signal indicates the fail status of LHF sensor";
CM_ SG_ 259 LHFWheelSpeed "This is the value of the left front wheel speed";
CM_ SG_ 259 LHR_FastPulseCounter "This signal is the left rear wheel pulse counter.";
CM_ SG_ 259 LHR_Spin "This signal indicates the left hand rear wheel status";
CM_ SG_ 259 LHR_WheelSensorFailSts "This signal indicates the fail status of LHR sensor";
CM_ SG_ 259 LHRWheelSpeed "This is the value of the left rear wheel speed";
CM_ SG_ 259 LongAccelerationOffset_BSM "LongAccelerationOffset_BSM";
CM_ SG_ 259 MessageCounter_BRAKE3 "This signal is a counter used for safety checks strategies. This counter is incremented of 1 (one) unit at each frame transmission.";
CM_ SG_ 259 RHF_FastPulseCounter "This signal is the right front wheel pulse counter.";
CM_ SG_ 259 RHF_Spin "This signal indicates the right hand front wheel status";
CM_ SG_ 259 RHF_WheelSensorFailSts "This signal indicates the fail status of RHF sensor";
CM_ SG_ 259 RHFWheelSpeed "This is the value of the right front wheel speed";
CM_ SG_ 259 RHR_FastPulseCounter "This signal is the right rear wheel pulse counter.";
CM_ SG_ 259 RHR_Spin "This signal indicates the right hand rear wheel status";
CM_ SG_ 259 RHR_WheelSensorFailSts "This signal indicates the fail status of RHR sensor";
CM_ SG_ 259 RHRWheelSpeed "This is the value of the right rear wheel speed";
CM_ SG_ 609 ClampForce "This signal is used to give information about the EPB Clamp Force";
CM_ SG_ 609 CRC_BRAKE4 "CRC according to SAE J1850 standard at each frame transmission.";
CM_ SG_ 609 EPBSts "0";
CM_ SG_ 609 EPBSwitchPosition "This signal is used to give information about the postition of the EPB switch";
CM_ SG_ 609 EPBWarningLampReq "EPB warning (fault) lamp active request";
CM_ SG_ 609 ESC_OFF_Hrd_Sft_Button_sts "ESC hard button status";
CM_ SG_ 609 MessageCounter_BRAKE4 "This signal is a counter used for safety checks strategies. This counter is incremented of 1 (one) unit at each frame transmission.";
CM_ SG_ 609 MSRActive "0";
CM_ SG_ 1155 ABSFailSts "0";
CM_ SG_ 1155 BSM_THA_Brk_Resp "BSM braking status for trailer hitch assist";
CM_ SG_ 1155 CRC_BRAKE5 "CRC according to SAE J1850 standard at each frame transmission.";
CM_ SG_ 1155 EBDFailSts "0";
CM_ SG_ 1155 ERMActive "This signal is set to \"active\" when Electronic Roll Mitigation functionality is acting.";
CM_ SG_ 1155 ESCFailSts "0";
CM_ SG_ 1155 ESCIntervention "0";
CM_ SG_ 1155 Function2Sts "Indicates the partial off status of the ESC/TCS system. [0]: Not_Active - Indicates that the ESC/TCS system is enabled, [1]: Active - Indicates that the ESC/TCS engine management is disabled";
CM_ SG_ 1155 MessageCounter_BRAKE5 "This signal is a counter used for safety checks strategies. This counter is incremented of 1 (one) unit at each frame transmission.";
CM_ SG_ 1155 TSCActive "This signal is set to \"active\" when Trailer Sway Control functionality is acting";
CM_ SG_ 514 BrakePdlPosn "Brake pedal travel sensor 0-100% (0 = upstop)";
CM_ SG_ 514 BrkPdl_Flt "Brake Pedal Fault is active, 1=Faulted";
CM_ SG_ 514 BrkPdl_Stat "Brake pedal state";
CM_ SG_ 514 BSM_OpStat "Capability of the primary brake control module to provide deceleration and/or stability control";
CM_ SG_ 514 BSM_ReadyForESS "BSM Stop Start Ready status";
CM_ SG_ 514 CRC_BRAKE7 "CRC according to SAE J1850 standard at each frame transmission.";
CM_ SG_ 514 MessageCounter_BRAKE7 "This signal is a counter used for safety checks strategies. This counter is incremented of 1 (one) unit at each frame transmission.";
CM_ SG_ 514 PAM_Brk_Rq_RspSts "PAM Brake Request Response Status made by the BSM for Park Assist with Stop.";
CM_ SG_ 514 Rear_Diff_BSM_RQ "ESP Requested Rear Differential State";
CM_ SG_ 257 ABSActive_B2 "ABSActive_B2";
CM_ SG_ 257 Brk_Stat_B2 "Signifies a general braking event (both autonomous and driver requested) with the secondary brake control module";
CM_ SG_ 257 CRC_BRAKE2_1 "CRC according to SAE J1850 standard at each frame transmission.";
CM_ SG_ 257 Ft_RrAxleCoupling_TrqRq_B2 "Desired Torque for Center Diff";
CM_ SG_ 257 Ft_RrTrqCoupling_ModeRq_B2 "ESP Requested Center Differential State";
CM_ SG_ 257 Inlet_Pressure_Pos "Inlet Pressure Pos Indicates if the secondary brake control module detects upstream brake pressure";
CM_ SG_ 257 LHF_FastPulseCounter_B2 "LHF_FastPulseCounter_B2";
CM_ SG_ 257 LHF_Spin_B2 "LHF_Spin_B2";
CM_ SG_ 257 LHF_WheelSensorFailSts_B2 "LHF_WheelSensorFailSts_B2";
CM_ SG_ 257 LHFWheelSpeed_B2 "LHFWheelSpeed_B2";
CM_ SG_ 257 MessageCounter_BRAKE2_1 "This signal is a counter used for safety checks strategies. This counter is incremented of 1 (one) unit at each frame transmission.";
CM_ SG_ 257 R_DIFF_TRQ_RQ_B2 "Desired Torque for Rear Diff.";
CM_ SG_ 257 Rear_Diff_BSM_RQ_B2 "ESP Requested Rear Differential State";
CM_ SG_ 257 RHF_FastPulseCounter_B2 "RHF_FastPulseCounter_B2";
CM_ SG_ 257 RHF_Spin_B2 "RHF_Spin_B2";
CM_ SG_ 257 RHF_WheelSensorFailSts_B2 "RHF_WheelSensorFailSts_B2";
CM_ SG_ 257 RHFWheelSpeed_B2 "RHFWheelSpeed_B2";
CM_ SG_ 257 VehicleSpeedVSOSig_B2 "VehicleSpeedVSOSig_B2";
CM_ SG_ 524 AEB_Type_Brk_B2 "AEB_Type_Brk_B2";
CM_ SG_ 524 Brake_OpStat_Sec "Capability of the Braking system to perform deceleration and/or stability control as reported by the secondary actuator.";
CM_ SG_ 524 BrkTrq_B2 "BrkTrq_B2";
CM_ SG_ 524 BSM2_Long_DTO "BSM2_Long_DTO";
CM_ SG_ 524 BSM2_OpStat "Capability of the secondary brake control module to provide deceleration and/or stability control";
CM_ SG_ 524 CRC_BRAKE2_2 "CRC according to SAE J1850 standard at each frame transmission.";
CM_ SG_ 524 MessageCounter_BRAKE2_2 "This signal is a counter used for safety checks strategies. This counter is incremented of 1 (one) unit at each frame transmission.";
CM_ SG_ 524 VehicleStandStillSts_B2 "VehicleStandStillSts_B2";
CM_ SG_ 1156 ABSFailSts_B2 "ABSFailSts_B2";
CM_ SG_ 1156 CRC_BRAKE2_3 "CRC according to SAE J1850 standard at each frame transmission.";
CM_ SG_ 1156 MessageCounter_BRAKE2_3 "This signal is a counter used for safety checks strategies. This counter is incremented of 1 (one) unit at each frame transmission.";
CM_ SG_ 1156 RollsModeAct_B2 "RollsModeAct_B2";
CM_ SG_ 275 CRC_CVPAM_FD_Control "CRC according to SAE J1850 standard at each frame transmission.";
CM_ SG_ 275 MessageCounter_CVPAM_FD_Control "This signal is a counter used for safety checks strategies. This counter is incremented of 1 (one) unit at each frame transmission.";
CM_ SG_ 275 PPPA_TurnIndicatorRqst "Request to turn on blinker";
CM_ SG_ 275 RR_PAM_Brk_RqSts "PAM rear brake request";
CM_ SG_ 275 RR_PAM_Dist "Rear Distance to Nearest Obstacle";
CM_ SG_ 275 RR_PAM_StopControlSts "PAM rear stop control status";
CM_ SG_ 950 Alert_CHF "This signal indicates which arc shall be displayed in the central hand, front position of the car graphics.";
CM_ SG_ 950 Alert_CHR "This signal indicates which arc shall be displayed in the central hand, rear position of the car graphics.";
CM_ SG_ 950 Alert_LHF "This signal indicates which arc shall be displayed in the left hand, front position of the car graphics.";
CM_ SG_ 950 Alert_LHR "This signal indicates which arc shall be displayed in the left hand, rear position of the car graphics.";
CM_ SG_ 950 Alert_RHF "This signal indicates which arc shall be displayed in the right hand, front position of the car graphics.";
CM_ SG_ 950 Alert_RHR "This signal indicates which arc shall be displayed in the right hand, rear position of the car graphics.";
CM_ SG_ 950 AUXCamsRQSts "AUX Cam request; Not Pressed = [0] Pressed = [1]";
CM_ SG_ 950 ChimeActivation_LHF "This signal indicates the chime activation request for the left hand, front audio speaker, or rear hardwired buzzer.";
CM_ SG_ 950 ChimeActivation_LHR "This signal indicates the chime activation request for the left hand, rear audio speaker, or rear hardwired buzzer.";
CM_ SG_ 950 ChimeActivation_RHF "This signal indicates the chime activation request for the right hand, front audio speaker, or rear hardwired buzzer.";
CM_ SG_ 950 ChimeActivation_RHR "This signal indicates the chime activation request for the right hand, rear audio speaker, or rear hardwired buzzer.";
CM_ SG_ 950 CRC_CVPAM_FD_Info "CRC according to SAE J1850 standard at each frame transmission.";
CM_ SG_ 950 DisplayView2 "CVPM Display view2 status";
CM_ SG_ 950 FrontSensorSts "This signal indicates the activation state of the front sensors.";
CM_ SG_ 950 FT_PAM_LedControlSts "Front Park Sense Button LED Status";
CM_ SG_ 950 Graphic_CHF "This signal indicates the flash rate of the arc displayed in the central hand, front position of the car graphics.";
CM_ SG_ 950 Graphic_CHR "This signal indicates the flash rate of the arc displayed in the central hand, rear position of the car graphics.";
CM_ SG_ 950 Graphic_LHF "This signal indicates the flash rate of the arc displayed in the left hand, front position of the car graphics.";
CM_ SG_ 950 Graphic_LHR "This signal indicates the flash rate of the arc displayed in the left hand, rear position of the car graphics.";
CM_ SG_ 950 Graphic_RHF "This signal indicates the flash rate of the arc displayed in the right hand, front position of the car graphics.";
CM_ SG_ 950 Graphic_RHR "This signal indicates the flash rate of the arc displayed in the right hand, rear position of the car graphics.";
CM_ SG_ 950 HMICode "This signal indicates the request to display HMI content on the screen";
CM_ SG_ 950 ImageDefeatRQSts "Image defeat request; Pressed = [1]";
CM_ SG_ 950 MessageCounter_CVPAM_FD_Info "This signal is a counter used for safety checks strategies. This counter is incremented of 1 (one) unit at each frame transmission.";
CM_ SG_ 950 MoreCamsRQSts "More Cams request; 
Not Pressed = [0] Pressed = [1]";
CM_ SG_ 950 PAM_CHIME_REP_RATESts "PAM chime repetition rate";
CM_ SG_ 950 PAM_CHIME_TYPE "Pam chime type";
CM_ SG_ 950 PAM_LedControlSts "This signal indicates the request to illuminate the PAM LED status indicator";
CM_ SG_ 950 PAM_Off_Status "Gives the status of the module";
CM_ SG_ 950 PAM_Off_Status_2BT "Front/Rear Park Sense ON/OFF Status";
CM_ SG_ 950 PAM_PopUpRqst "ParkSense HMI pop-up message request";
CM_ SG_ 950 PAM_Volume "Pam Volume signal";
CM_ SG_ 950 PAMSystemFault "This signal indicates if the PAM is in a faulted condition";
CM_ SG_ 950 ParkingManeuverActive "Parking information active";
CM_ SG_ 950 RearSensorSts "This signal indicates the activation state of the rear sensors";
CM_ SG_ 950 SPM_LedControlSts "This signal indicates the request to illuminate the SPM LED status indicator";
CM_ SG_ 950 SPM_Screen_Rqst "SPM screen request";
CM_ SG_ 950 SPMControlSts "This signal indicates the activation state of the SPM module.";
CM_ SG_ 950 SPMFailSts "This signal indicates if the SPM is in a faulted condition.";
CM_ SG_ 950 SPMSystemFault "This signal indicates the fail status of the SPM";
CM_ SG_ 950 TRSC_LED_Stat "TRSKM LED request";
CM_ SG_ 161 BATTERY_voltage "input voltage 1 measured by DBSM2";
CM_ SG_ 161 BATTERY2_voltage "input voltage 2 measured by DBSM2";
CM_ SG_ 161 CRC_DBSM2_1 "CRC-checksum byte 1 to 7 according to SAE J1850";
CM_ SG_ 161 DBSM2_internal_error "memory/CPU/sensors (fault flag)";
CM_ SG_ 161 ESS_input_active "ESS input was active (low) during the last 10 seconds";
CM_ SG_ 161 L2plus_ack "DBSM2 confirms L2plus mode";
CM_ SG_ 161 MC_DBSM2_1 "Message counter";
CM_ SG_ 161 overcurrent_detected "over current detected (fault flag)";
CM_ SG_ 161 overtemp_detected "over temperature detected (fault flag)";
CM_ SG_ 161 RsErr_DBSM2 "Response error DBSM2; Error=[1]";
CM_ SG_ 161 switch_status_OpenClose "The switch was activated (open) at least one time during the last 10 seconds";
CM_ SG_ 161 undervoltage_detected "under voltage detected (fault flag)";
CM_ SG_ 2564432881 N_PDU "This signal is used for diagnostic purposes";
CM_ SG_ 2564435953 N_PDU "This signal is used for diagnostic purposes";
CM_ SG_ 2564436209 N_PDU "This signal is used for diagnostic purposes";
CM_ SG_ 2564432882 N_PDU "This signal is used for diagnostic purposes";
CM_ SG_ 2564435954 N_PDU "This signal is used for diagnostic purposes";
CM_ SG_ 2564436210 N_PDU "This signal is used for diagnostic purposes";
CM_ SG_ 2564554482 N_PDU "This signal is used for diagnostic purposes";
CM_ SG_ 2564473074 N_PDU "This signal is used for diagnostic purposes";
CM_ SG_ 2564464882 N_PDU "This signal is used for diagnostic purposes";
CM_ SG_ 2564484338 N_PDU "This signal is used for diagnostic purposes";
CM_ SG_ 2564435957 N_PDU "This signal is used for diagnostic purposes";
CM_ SG_ 2564436213 N_PDU "This signal is used for diagnostic purposes";
CM_ SG_ 2564473077 N_PDU "This signal is used for diagnostic purposes";
CM_ SG_ 2564554485 N_PDU "This signal is used for diagnostic purposes";
CM_ SG_ 2564502513 N_PDU "This signal is used for diagnostic purposes";
CM_ SG_ 2564554481 N_PDU "This signal is used for diagnostic purposes";
CM_ SG_ 2564473073 N_PDU "This signal is used for diagnostic purposes";
CM_ SG_ 2564464881 N_PDU "This signal is used for diagnostic purposes";
CM_ SG_ 2564484337 N_PDU "This signal is used for diagnostic purposes";
CM_ SG_ 2564485411 N_PDU "This signal is used for diagnostic purposes";
CM_ SG_ 2564485423 N_PDU "This signal is used for diagnostic purposes";
CM_ SG_ 2564485424 N_PDU "This signal is used for diagnostic purposes";
CM_ SG_ 2564485667 N_PDU "This signal is used for diagnostic purposes";
CM_ SG_ 2564485679 N_PDU "This signal is used for diagnostic purposes";
CM_ SG_ 2564485680 N_PDU "This signal is used for diagnostic purposes";
CM_ SG_ 2564485824 N_PDU "This signal is used for diagnostic purposes";
CM_ SG_ 2564485792 N_PDU "This signal is used for diagnostic purposes";
CM_ SG_ 2564485868 N_PDU "This signal is used for diagnostic purposes";
CM_ SG_ 2564486447 N_PDU "This signal is used for diagnostic purposes";
CM_ SG_ 2564486448 N_PDU "This signal is used for diagnostic purposes";
CM_ SG_ 2564486592 N_PDU "This signal is used for diagnostic purposes";
CM_ SG_ 2564485568 N_PDU "This signal is used for diagnostic purposes";
CM_ SG_ 2564485536 N_PDU "This signal is used for diagnostic purposes";
CM_ SG_ 2564485612 N_PDU "This signal is used for diagnostic purposes";
BA_DEF_ SG_  "GenSigStartValue" INT 0 2147483647;
BA_DEF_ SG_  "GenSigInactiveValue" INT 0 2147483647;
BA_DEF_ SG_  "GenSigSendType" ENUM  "NotUsed","OnWrite","OnWriteWithRepetition","OnChange","OnChangeWithRepetition","IfActive","IfActiveWithRepetition","NoSigSendType";
BA_DEF_ SG_  "GenSigTimeoutTime_BCM" INT 0 65535;
BA_DEF_ SG_  "GenSigTimeoutTime_BSM2" INT 0 65535;
BA_DEF_ SG_  "GenSigTimeoutTime_CADM2" INT 0 65535;
BA_DEF_ SG_  "GenSigTimeoutTime_CVADAS" INT 0 65535;
BA_DEF_ SG_  "GenSigTimeoutTime_EPS" INT 0 65535;
BA_DEF_ SG_  "GenSigTimeoutTime_ORC" INT 0 65535;
BA_DEF_ SG_  "GenSigTimeoutTime_PAM" INT 0 65535;
BA_DEF_ SG_  "GenSigTimeoutTime_SGW" INT 0 65535;
BA_DEF_ SG_  "GenSigTimeoutTime_TRSKM" INT 0 65535;
BA_DEF_ BO_  "DiagRequest" ENUM  "No","Yes";
BA_DEF_ BO_  "Type" ENUM  "P","C","PE","COC","PE_Cntrl","E","E_Cntrl","OC","S","BAF","DC","EM","MM","ISO-TP","-";
BA_DEF_ BO_  "DiagResponse" ENUM  "No","Yes";
BA_DEF_ BO_  "NmMessage" ENUM  "No","Yes";
BA_DEF_ BO_  "GenMsgSendType" ENUM  "Cyclic","NotUsed","NotUsed","NotUsed","NotUsed","NotUsed","NotUsed","NotUsed","NoMsgSendType";
BA_DEF_ BO_  "GenMsgNrOfRepetition" INT 0 255;
BA_DEF_ BO_  "GenMsgILSupport" ENUM  "No","Yes";
BA_DEF_ BO_  "GenMsgStartDelayTime" INT 0 65535;
BA_DEF_ BO_  "GenMsgCycleTimeFast" INT 0 65535;
BA_DEF_ BO_  "GenMsgCycleTime" INT 0 65535;
BA_DEF_ BO_  "GenMsgDelayTime" INT 0 65535;
BA_DEF_ BO_  "NmAsrMessage" ENUM  "No","Yes";
BA_DEF_ BO_  "DiagState" ENUM  "No","Yes";
BA_DEF_ BO_  "DiagConnection" HEX 0 65535;
BA_DEF_ BO_  "VFrameFormat" ENUM  "StandardCAN","ExtendedCAN","reserved","reserved","reserved","reserved","reserved","reserved","reserved","reserved","reserved","reserved","reserved","reserved","StandardCAN_FD","ExtendedCAN_FD";
BA_DEF_ BO_  "CANFD_BRS" INT 0 1;
BA_DEF_DEF_  "GenSigStartValue" 0;
BA_DEF_DEF_  "GenSigInactiveValue" 0;
BA_DEF_DEF_  "GenSigSendType" "NoSigSendType";
BA_DEF_DEF_  "GenSigTimeoutTime_BCM" 2500;
BA_DEF_DEF_  "GenSigTimeoutTime_BSM2" 2500;
BA_DEF_DEF_  "GenSigTimeoutTime_CADM2" 2500;
BA_DEF_DEF_  "GenSigTimeoutTime_CVADAS" 2500;
BA_DEF_DEF_  "GenSigTimeoutTime_EPS" 2500;
BA_DEF_DEF_  "GenSigTimeoutTime_ORC" 2500;
BA_DEF_DEF_  "GenSigTimeoutTime_PAM" 2500;
BA_DEF_DEF_  "GenSigTimeoutTime_SGW" 2500;
BA_DEF_DEF_  "GenSigTimeoutTime_TRSKM" 2500;
BA_DEF_DEF_  "DiagRequest" "No";
BA_DEF_DEF_  "Type" "-";
BA_DEF_DEF_  "DiagResponse" "No";
BA_DEF_DEF_  "NmMessage" "No";
BA_DEF_DEF_  "GenMsgSendType" "NoMsgSendType";
BA_DEF_DEF_  "GenMsgNrOfRepetition" 0;
BA_DEF_DEF_  "GenMsgILSupport" "No";
BA_DEF_DEF_  "GenMsgStartDelayTime" 0;
BA_DEF_DEF_  "GenMsgCycleTimeFast" 0;
BA_DEF_DEF_  "GenMsgCycleTime" 0;
BA_DEF_DEF_  "GenMsgDelayTime" 0;
BA_DEF_DEF_  "NmAsrMessage" "No";
BA_DEF_DEF_  "DiagState" "No";
BA_DEF_DEF_  "DiagConnection" 0;
BA_DEF_DEF_  "VFrameFormat" "StandardCAN_FD";
BA_DEF_DEF_  "CANFD_BRS" 0;
BA_ "Type" BO_ 1051 1;
BA_ "GenMsgSendType" BO_ 1051 0;
BA_ "GenMsgILSupport" BO_ 1051 1;
BA_ "GenMsgStartDelayTime" BO_ 1051 95;
BA_ "GenMsgCycleTime" BO_ 1051 100;
BA_ "CANFD_BRS" BO_ 1051 1;
BA_ "Type" BO_ 1375 1;
BA_ "GenMsgSendType" BO_ 1375 0;
BA_ "GenMsgILSupport" BO_ 1375 1;
BA_ "GenMsgStartDelayTime" BO_ 1375 65;
BA_ "GenMsgCycleTime" BO_ 1375 250;
BA_ "CANFD_BRS" BO_ 1375 1;
BA_ "Type" BO_ 1827 1;
BA_ "GenMsgSendType" BO_ 1827 0;
BA_ "GenMsgILSupport" BO_ 1827 1;
BA_ "GenMsgStartDelayTime" BO_ 1827 195;
BA_ "GenMsgCycleTime" BO_ 1827 1000;
BA_ "CANFD_BRS" BO_ 1827 1;
BA_ "Type" BO_ 1066 3;
BA_ "GenMsgSendType" BO_ 1066 0;
BA_ "GenMsgNrOfRepetition" BO_ 1066 2;
BA_ "GenMsgILSupport" BO_ 1066 1;
BA_ "GenMsgStartDelayTime" BO_ 1066 60;
BA_ "GenMsgCycleTimeFast" BO_ 1066 20;
BA_ "GenMsgCycleTime" BO_ 1066 250;
BA_ "GenMsgDelayTime" BO_ 1066 20;
BA_ "CANFD_BRS" BO_ 1066 1;
BA_ "Type" BO_ 513 1;
BA_ "GenMsgSendType" BO_ 513 0;
BA_ "GenMsgILSupport" BO_ 513 1;
BA_ "GenMsgCycleTime" BO_ 513 20;
BA_ "CANFD_BRS" BO_ 513 1;
BA_ "Type" BO_ 258 1;
BA_ "GenMsgSendType" BO_ 258 0;
BA_ "GenMsgILSupport" BO_ 258 1;
BA_ "GenMsgCycleTime" BO_ 258 10;
BA_ "CANFD_BRS" BO_ 258 1;
BA_ "Type" BO_ 259 1;
BA_ "GenMsgSendType" BO_ 259 0;
BA_ "GenMsgILSupport" BO_ 259 1;
BA_ "GenMsgCycleTime" BO_ 259 10;
BA_ "CANFD_BRS" BO_ 259 1;
BA_ "Type" BO_ 609 3;
BA_ "GenMsgSendType" BO_ 609 0;
BA_ "GenMsgNrOfRepetition" BO_ 609 2;
BA_ "GenMsgILSupport" BO_ 609 1;
BA_ "GenMsgStartDelayTime" BO_ 609 5;
BA_ "GenMsgCycleTimeFast" BO_ 609 20;
BA_ "GenMsgCycleTime" BO_ 609 100;
BA_ "CANFD_BRS" BO_ 609 1;
BA_ "Type" BO_ 1155 3;
BA_ "GenMsgSendType" BO_ 1155 0;
BA_ "GenMsgNrOfRepetition" BO_ 1155 2;
BA_ "GenMsgILSupport" BO_ 1155 1;
BA_ "GenMsgStartDelayTime" BO_ 1155 70;
BA_ "GenMsgCycleTimeFast" BO_ 1155 20;
BA_ "GenMsgCycleTime" BO_ 1155 500;
BA_ "GenMsgDelayTime" BO_ 1155 20;
BA_ "CANFD_BRS" BO_ 1155 1;
BA_ "Type" BO_ 514 1;
BA_ "GenMsgSendType" BO_ 514 0;
BA_ "GenMsgILSupport" BO_ 514 1;
BA_ "GenMsgStartDelayTime" BO_ 514 5;
BA_ "GenMsgCycleTime" BO_ 514 20;
BA_ "CANFD_BRS" BO_ 514 1;
BA_ "Type" BO_ 257 1;
BA_ "GenMsgSendType" BO_ 257 0;
BA_ "GenMsgILSupport" BO_ 257 1;
BA_ "GenMsgCycleTime" BO_ 257 10;
BA_ "CANFD_BRS" BO_ 257 1;
BA_ "Type" BO_ 524 1;
BA_ "GenMsgSendType" BO_ 524 0;
BA_ "GenMsgILSupport" BO_ 524 1;
BA_ "GenMsgCycleTime" BO_ 524 20;
BA_ "CANFD_BRS" BO_ 524 1;
BA_ "Type" BO_ 1156 3;
BA_ "GenMsgSendType" BO_ 1156 0;
BA_ "GenMsgNrOfRepetition" BO_ 1156 2;
BA_ "GenMsgILSupport" BO_ 1156 1;
BA_ "GenMsgCycleTimeFast" BO_ 1156 20;
BA_ "GenMsgCycleTime" BO_ 1156 500;
BA_ "GenMsgDelayTime" BO_ 1156 20;
BA_ "CANFD_BRS" BO_ 1156 1;
BA_ "Type" BO_ 2651930624 8;
BA_ "GenMsgILSupport" BO_ 2651930624 1;
BA_ "GenMsgDelayTime" BO_ 2651930624 10;
BA_ "CANFD_BRS" BO_ 2651930624 1;
BA_ "VFrameFormat" BO_ 2651930624 15;
BA_ "Type" BO_ 2651930772 11;
BA_ "GenMsgILSupport" BO_ 2651930772 1;
BA_ "CANFD_BRS" BO_ 2651930772 1;
BA_ "VFrameFormat" BO_ 2651930772 15;
BA_ "Type" BO_ 2651930766 11;
BA_ "GenMsgILSupport" BO_ 2651930766 1;
BA_ "CANFD_BRS" BO_ 2651930766 1;
BA_ "VFrameFormat" BO_ 2651930766 15;
BA_ "Type" BO_ 2651930626 11;
BA_ "GenMsgILSupport" BO_ 2651930626 1;
BA_ "CANFD_BRS" BO_ 2651930626 1;
BA_ "VFrameFormat" BO_ 2651930626 15;
BA_ "Type" BO_ 2651930650 11;
BA_ "GenMsgILSupport" BO_ 2651930650 1;
BA_ "CANFD_BRS" BO_ 2651930650 1;
BA_ "VFrameFormat" BO_ 2651930650 15;
BA_ "Type" BO_ 2651930648 11;
BA_ "GenMsgILSupport" BO_ 2651930648 1;
BA_ "CANFD_BRS" BO_ 2651930648 1;
BA_ "VFrameFormat" BO_ 2651930648 15;
BA_ "Type" BO_ 2651930801 11;
BA_ "GenMsgILSupport" BO_ 2651930801 1;
BA_ "CANFD_BRS" BO_ 2651930801 1;
BA_ "VFrameFormat" BO_ 2651930801 15;
BA_ "Type" BO_ 275 1;
BA_ "GenMsgSendType" BO_ 275 0;
BA_ "GenMsgILSupport" BO_ 275 1;
BA_ "GenMsgStartDelayTime" BO_ 275 5;
BA_ "GenMsgCycleTime" BO_ 275 10;
BA_ "CANFD_BRS" BO_ 275 1;
BA_ "Type" BO_ 950 3;
BA_ "GenMsgSendType" BO_ 950 0;
BA_ "GenMsgILSupport" BO_ 950 1;
BA_ "GenMsgStartDelayTime" BO_ 950 125;
BA_ "GenMsgCycleTime" BO_ 950 250;
BA_ "CANFD_BRS" BO_ 950 1;
BA_ "Type" BO_ 161 8;
BA_ "GenMsgILSupport" BO_ 161 1;
BA_ "CANFD_BRS" BO_ 161 1;
BA_ "DiagRequest" BO_ 2564432881 1;
BA_ "Type" BO_ 2564432881 8;
BA_ "DiagConnection" BO_ 2564432881 61731;
BA_ "VFrameFormat" BO_ 2564432881 1;
BA_ "DiagRequest" BO_ 2564435953 1;
BA_ "Type" BO_ 2564435953 8;
BA_ "DiagConnection" BO_ 2564435953 61743;
BA_ "VFrameFormat" BO_ 2564435953 1;
BA_ "DiagRequest" BO_ 2564436209 1;
BA_ "Type" BO_ 2564436209 8;
BA_ "DiagConnection" BO_ 2564436209 61744;
BA_ "VFrameFormat" BO_ 2564436209 1;
BA_ "DiagRequest" BO_ 2564432882 1;
BA_ "Type" BO_ 2564432882 8;
BA_ "DiagConnection" BO_ 2564432882 61987;
BA_ "CANFD_BRS" BO_ 2564432882 1;
BA_ "VFrameFormat" BO_ 2564432882 15;
BA_ "DiagRequest" BO_ 2564435954 1;
BA_ "Type" BO_ 2564435954 8;
BA_ "DiagConnection" BO_ 2564435954 61999;
BA_ "CANFD_BRS" BO_ 2564435954 1;
BA_ "VFrameFormat" BO_ 2564435954 15;
BA_ "DiagRequest" BO_ 2564436210 1;
BA_ "Type" BO_ 2564436210 8;
BA_ "DiagConnection" BO_ 2564436210 62000;
BA_ "CANFD_BRS" BO_ 2564436210 1;
BA_ "VFrameFormat" BO_ 2564436210 15;
BA_ "Type" BO_ 2564554482 8;
BA_ "DiagState" BO_ 2564554482 1;
BA_ "DiagConnection" BO_ 2564554482 62206;
BA_ "CANFD_BRS" BO_ 2564554482 1;
BA_ "VFrameFormat" BO_ 2564554482 15;
BA_ "DiagRequest" BO_ 2564473074 1;
BA_ "Type" BO_ 2564473074 8;
BA_ "DiagConnection" BO_ 2564473074 62144;
BA_ "CANFD_BRS" BO_ 2564473074 1;
BA_ "VFrameFormat" BO_ 2564473074 15;
BA_ "DiagRequest" BO_ 2564464882 1;
BA_ "Type" BO_ 2564464882 8;
BA_ "DiagConnection" BO_ 2564464882 62112;
BA_ "CANFD_BRS" BO_ 2564464882 1;
BA_ "VFrameFormat" BO_ 2564464882 15;
BA_ "DiagRequest" BO_ 2564484338 1;
BA_ "Type" BO_ 2564484338 8;
BA_ "DiagConnection" BO_ 2564484338 62188;
BA_ "CANFD_BRS" BO_ 2564484338 1;
BA_ "VFrameFormat" BO_ 2564484338 15;
BA_ "DiagRequest" BO_ 2564435957 1;
BA_ "Type" BO_ 2564435957 8;
BA_ "DiagConnection" BO_ 2564435957 62767;
BA_ "CANFD_BRS" BO_ 2564435957 1;
BA_ "VFrameFormat" BO_ 2564435957 15;
BA_ "DiagRequest" BO_ 2564436213 1;
BA_ "Type" BO_ 2564436213 8;
BA_ "DiagConnection" BO_ 2564436213 62768;
BA_ "CANFD_BRS" BO_ 2564436213 1;
BA_ "VFrameFormat" BO_ 2564436213 15;
BA_ "DiagRequest" BO_ 2564473077 1;
BA_ "Type" BO_ 2564473077 8;
BA_ "DiagConnection" BO_ 2564473077 62912;
BA_ "CANFD_BRS" BO_ 2564473077 1;
BA_ "VFrameFormat" BO_ 2564473077 15;
BA_ "Type" BO_ 2564554485 8;
BA_ "DiagState" BO_ 2564554485 1;
BA_ "DiagConnection" BO_ 2564554485 62974;
BA_ "CANFD_BRS" BO_ 2564554485 1;
BA_ "VFrameFormat" BO_ 2564554485 15;
BA_ "Type" BO_ 2564502513 8;
BA_ "DiagState" BO_ 2564502513 1;
BA_ "DiagConnection" BO_ 2564502513 61747;
BA_ "VFrameFormat" BO_ 2564502513 1;
BA_ "Type" BO_ 2564554481 8;
BA_ "DiagState" BO_ 2564554481 1;
BA_ "DiagConnection" BO_ 2564554481 61950;
BA_ "VFrameFormat" BO_ 2564554481 1;
BA_ "DiagRequest" BO_ 2564473073 1;
BA_ "Type" BO_ 2564473073 8;
BA_ "DiagConnection" BO_ 2564473073 61888;
BA_ "VFrameFormat" BO_ 2564473073 1;
BA_ "DiagRequest" BO_ 2564464881 1;
BA_ "Type" BO_ 2564464881 8;
BA_ "DiagConnection" BO_ 2564464881 61856;
BA_ "VFrameFormat" BO_ 2564464881 1;
BA_ "DiagRequest" BO_ 2564484337 1;
BA_ "Type" BO_ 2564484337 8;
BA_ "DiagConnection" BO_ 2564484337 61932;
BA_ "VFrameFormat" BO_ 2564484337 1;
BA_ "Type" BO_ 2564485411 8;
BA_ "DiagResponse" BO_ 2564485411 1;
BA_ "DiagConnection" BO_ 2564485411 61731;
BA_ "VFrameFormat" BO_ 2564485411 1;
BA_ "Type" BO_ 2564485423 8;
BA_ "DiagResponse" BO_ 2564485423 1;
BA_ "DiagConnection" BO_ 2564485423 61743;
BA_ "VFrameFormat" BO_ 2564485423 1;
BA_ "Type" BO_ 2564485424 8;
BA_ "DiagResponse" BO_ 2564485424 1;
BA_ "DiagConnection" BO_ 2564485424 61744;
BA_ "VFrameFormat" BO_ 2564485424 1;
BA_ "Type" BO_ 2564485667 8;
BA_ "DiagResponse" BO_ 2564485667 1;
BA_ "DiagConnection" BO_ 2564485667 61987;
BA_ "CANFD_BRS" BO_ 2564485667 1;
BA_ "VFrameFormat" BO_ 2564485667 15;
BA_ "Type" BO_ 2564485679 8;
BA_ "DiagResponse" BO_ 2564485679 1;
BA_ "DiagConnection" BO_ 2564485679 61999;
BA_ "CANFD_BRS" BO_ 2564485679 1;
BA_ "VFrameFormat" BO_ 2564485679 15;
BA_ "Type" BO_ 2564485680 8;
BA_ "DiagResponse" BO_ 2564485680 1;
BA_ "DiagConnection" BO_ 2564485680 62000;
BA_ "CANFD_BRS" BO_ 2564485680 1;
BA_ "VFrameFormat" BO_ 2564485680 15;
BA_ "Type" BO_ 2564485824 8;
BA_ "DiagResponse" BO_ 2564485824 1;
BA_ "DiagConnection" BO_ 2564485824 62144;
BA_ "CANFD_BRS" BO_ 2564485824 1;
BA_ "VFrameFormat" BO_ 2564485824 15;
BA_ "Type" BO_ 2564485792 8;
BA_ "DiagResponse" BO_ 2564485792 1;
BA_ "DiagConnection" BO_ 2564485792 62112;
BA_ "CANFD_BRS" BO_ 2564485792 1;
BA_ "VFrameFormat" BO_ 2564485792 15;
BA_ "Type" BO_ 2564485868 8;
BA_ "DiagResponse" BO_ 2564485868 1;
BA_ "DiagConnection" BO_ 2564485868 62188;
BA_ "CANFD_BRS" BO_ 2564485868 1;
BA_ "VFrameFormat" BO_ 2564485868 15;
BA_ "Type" BO_ 2564486447 8;
BA_ "DiagResponse" BO_ 2564486447 1;
BA_ "DiagConnection" BO_ 2564486447 62767;
BA_ "CANFD_BRS" BO_ 2564486447 1;
BA_ "VFrameFormat" BO_ 2564486447 15;
BA_ "Type" BO_ 2564486448 8;
BA_ "DiagResponse" BO_ 2564486448 1;
BA_ "DiagConnection" BO_ 2564486448 62768;
BA_ "CANFD_BRS" BO_ 2564486448 1;
BA_ "VFrameFormat" BO_ 2564486448 15;
BA_ "Type" BO_ 2564486592 8;
BA_ "DiagResponse" BO_ 2564486592 1;
BA_ "DiagConnection" BO_ 2564486592 62912;
BA_ "CANFD_BRS" BO_ 2564486592 1;
BA_ "VFrameFormat" BO_ 2564486592 15;
BA_ "Type" BO_ 2564485568 8;
BA_ "DiagResponse" BO_ 2564485568 1;
BA_ "DiagConnection" BO_ 2564485568 61888;
BA_ "VFrameFormat" BO_ 2564485568 1;
BA_ "Type" BO_ 2564485536 8;
BA_ "DiagResponse" BO_ 2564485536 1;
BA_ "DiagConnection" BO_ 2564485536 61856;
BA_ "VFrameFormat" BO_ 2564485536 1;
BA_ "Type" BO_ 2564485612 8;
BA_ "DiagResponse" BO_ 2564485612 1;
BA_ "DiagConnection" BO_ 2564485612 61932;
BA_ "VFrameFormat" BO_ 2564485612 1;
BA_ "GenSigStartValue" SG_ 1051 ExternalTemperatureAD_Voltage 255;
BA_ "GenSigTimeoutTime_BCM" SG_ 1051 ExternalTemperatureAD_Voltage 0;
BA_ "GenSigTimeoutTime_BSM2" SG_ 1051 ExternalTemperatureAD_Voltage 0;
BA_ "GenSigTimeoutTime_CADM2" SG_ 1051 ExternalTemperatureAD_Voltage 0;
BA_ "GenSigTimeoutTime_CVADAS" SG_ 1051 ExternalTemperatureAD_Voltage 0;
BA_ "GenSigTimeoutTime_EPS" SG_ 1051 ExternalTemperatureAD_Voltage 0;
BA_ "GenSigTimeoutTime_ORC" SG_ 1051 ExternalTemperatureAD_Voltage 0;
BA_ "GenSigTimeoutTime_PAM" SG_ 1051 ExternalTemperatureAD_Voltage 0;
BA_ "GenSigTimeoutTime_SGW" SG_ 1051 ExternalTemperatureAD_Voltage 0;
BA_ "GenSigTimeoutTime_TRSKM" SG_ 1051 ExternalTemperatureAD_Voltage 0;
BA_ "GenSigStartValue" SG_ 1051 FUEL_VOLT 255;
BA_ "GenSigTimeoutTime_BCM" SG_ 1051 FUEL_VOLT 0;
BA_ "GenSigTimeoutTime_BSM2" SG_ 1051 FUEL_VOLT 0;
BA_ "GenSigTimeoutTime_CADM2" SG_ 1051 FUEL_VOLT 0;
BA_ "GenSigTimeoutTime_CVADAS" SG_ 1051 FUEL_VOLT 0;
BA_ "GenSigTimeoutTime_EPS" SG_ 1051 FUEL_VOLT 0;
BA_ "GenSigTimeoutTime_ORC" SG_ 1051 FUEL_VOLT 0;
BA_ "GenSigTimeoutTime_PAM" SG_ 1051 FUEL_VOLT 0;
BA_ "GenSigTimeoutTime_SGW" SG_ 1051 FUEL_VOLT 0;
BA_ "GenSigTimeoutTime_TRSKM" SG_ 1051 FUEL_VOLT 0;
BA_ "GenSigTimeoutTime_BCM" SG_ 1375 ChkFuelLevelSts 0;
BA_ "GenSigTimeoutTime_BSM2" SG_ 1375 ChkFuelLevelSts 0;
BA_ "GenSigTimeoutTime_CADM2" SG_ 1375 ChkFuelLevelSts 0;
BA_ "GenSigTimeoutTime_CVADAS" SG_ 1375 ChkFuelLevelSts 0;
BA_ "GenSigTimeoutTime_EPS" SG_ 1375 ChkFuelLevelSts 0;
BA_ "GenSigTimeoutTime_ORC" SG_ 1375 ChkFuelLevelSts 0;
BA_ "GenSigTimeoutTime_PAM" SG_ 1375 ChkFuelLevelSts 0;
BA_ "GenSigTimeoutTime_SGW" SG_ 1375 ChkFuelLevelSts 0;
BA_ "GenSigTimeoutTime_TRSKM" SG_ 1375 ChkFuelLevelSts 0;
BA_ "GenSigTimeoutTime_BCM" SG_ 1375 FrontWiperReq 0;
BA_ "GenSigTimeoutTime_BSM2" SG_ 1375 FrontWiperReq 0;
BA_ "GenSigTimeoutTime_CADM2" SG_ 1375 FrontWiperReq 0;
BA_ "GenSigTimeoutTime_CVADAS" SG_ 1375 FrontWiperReq 0;
BA_ "GenSigTimeoutTime_EPS" SG_ 1375 FrontWiperReq 0;
BA_ "GenSigTimeoutTime_ORC" SG_ 1375 FrontWiperReq 0;
BA_ "GenSigTimeoutTime_PAM" SG_ 1375 FrontWiperReq 0;
BA_ "GenSigTimeoutTime_SGW" SG_ 1375 FrontWiperReq 0;
BA_ "GenSigTimeoutTime_TRSKM" SG_ 1375 FrontWiperReq 0;
BA_ "GenSigTimeoutTime_BCM" SG_ 1827 CRC_BCM7 0;
BA_ "GenSigTimeoutTime_CADM2" SG_ 1827 CRC_BCM7 0;
BA_ "GenSigTimeoutTime_CVADAS" SG_ 1827 CRC_BCM7 0;
BA_ "GenSigTimeoutTime_EPS" SG_ 1827 CRC_BCM7 0;
BA_ "GenSigTimeoutTime_ORC" SG_ 1827 CRC_BCM7 0;
BA_ "GenSigTimeoutTime_PAM" SG_ 1827 CRC_BCM7 0;
BA_ "GenSigTimeoutTime_SGW" SG_ 1827 CRC_BCM7 0;
BA_ "GenSigTimeoutTime_TRSKM" SG_ 1827 CRC_BCM7 0;
BA_ "GenSigTimeoutTime_BCM" SG_ 1827 IgnitionOnCounter 0;
BA_ "GenSigTimeoutTime_SGW" SG_ 1827 IgnitionOnCounter 0;
BA_ "GenSigTimeoutTime_BCM" SG_ 1827 MessageCounter_BCM7 0;
BA_ "GenSigTimeoutTime_CADM2" SG_ 1827 MessageCounter_BCM7 0;
BA_ "GenSigTimeoutTime_CVADAS" SG_ 1827 MessageCounter_BCM7 0;
BA_ "GenSigTimeoutTime_EPS" SG_ 1827 MessageCounter_BCM7 0;
BA_ "GenSigTimeoutTime_ORC" SG_ 1827 MessageCounter_BCM7 0;
BA_ "GenSigTimeoutTime_PAM" SG_ 1827 MessageCounter_BCM7 0;
BA_ "GenSigTimeoutTime_SGW" SG_ 1827 MessageCounter_BCM7 0;
BA_ "GenSigTimeoutTime_TRSKM" SG_ 1827 MessageCounter_BCM7 0;
BA_ "GenSigSendType" SG_ 1066 BonnetSts 3;
BA_ "GenSigTimeoutTime_BCM" SG_ 1066 BonnetSts 0;
BA_ "GenSigTimeoutTime_BSM2" SG_ 1066 BonnetSts 0;
BA_ "GenSigTimeoutTime_CADM2" SG_ 1066 BonnetSts 0;
BA_ "GenSigTimeoutTime_CVADAS" SG_ 1066 BonnetSts 0;
BA_ "GenSigTimeoutTime_EPS" SG_ 1066 BonnetSts 0;
BA_ "GenSigTimeoutTime_PAM" SG_ 1066 BonnetSts 0;
BA_ "GenSigTimeoutTime_SGW" SG_ 1066 BonnetSts 0;
BA_ "GenSigTimeoutTime_TRSKM" SG_ 1066 BonnetSts 0;
BA_ "GenSigTimeoutTime_BCM" SG_ 1066 BrakeFluidLevelSts 0;
BA_ "GenSigTimeoutTime_CADM2" SG_ 1066 BrakeFluidLevelSts 0;
BA_ "GenSigTimeoutTime_CVADAS" SG_ 1066 BrakeFluidLevelSts 0;
BA_ "GenSigTimeoutTime_EPS" SG_ 1066 BrakeFluidLevelSts 0;
BA_ "GenSigTimeoutTime_ORC" SG_ 1066 BrakeFluidLevelSts 0;
BA_ "GenSigTimeoutTime_PAM" SG_ 1066 BrakeFluidLevelSts 0;
BA_ "GenSigTimeoutTime_SGW" SG_ 1066 BrakeFluidLevelSts 0;
BA_ "GenSigTimeoutTime_TRSKM" SG_ 1066 BrakeFluidLevelSts 0;
BA_ "GenSigTimeoutTime_BCM" SG_ 1066 CRC_BCM9 0;
BA_ "GenSigTimeoutTime_BSM2" SG_ 1066 CRC_BCM9 0;
BA_ "GenSigTimeoutTime_EPS" SG_ 1066 CRC_BCM9 0;
BA_ "GenSigTimeoutTime_ORC" SG_ 1066 CRC_BCM9 0;
BA_ "GenSigTimeoutTime_PAM" SG_ 1066 CRC_BCM9 0;
BA_ "GenSigTimeoutTime_SGW" SG_ 1066 CRC_BCM9 0;
BA_ "GenSigTimeoutTime_TRSKM" SG_ 1066 CRC_BCM9 0;
BA_ "GenSigTimeoutTime_BCM" SG_ 1066 DoorLockLastElSts 0;
BA_ "GenSigTimeoutTime_BSM2" SG_ 1066 DoorLockLastElSts 0;
BA_ "GenSigTimeoutTime_CADM2" SG_ 1066 DoorLockLastElSts 0;
BA_ "GenSigTimeoutTime_CVADAS" SG_ 1066 DoorLockLastElSts 0;
BA_ "GenSigTimeoutTime_EPS" SG_ 1066 DoorLockLastElSts 0;
BA_ "GenSigTimeoutTime_PAM" SG_ 1066 DoorLockLastElSts 0;
BA_ "GenSigTimeoutTime_SGW" SG_ 1066 DoorLockLastElSts 0;
BA_ "GenSigTimeoutTime_TRSKM" SG_ 1066 DoorLockLastElSts 0;
BA_ "GenSigSendType" SG_ 1066 DriverDoorSts 3;
BA_ "GenSigTimeoutTime_BCM" SG_ 1066 DriverDoorSts 0;
BA_ "GenSigTimeoutTime_BSM2" SG_ 1066 DriverDoorSts 0;
BA_ "GenSigTimeoutTime_CADM2" SG_ 1066 DriverDoorSts 0;
BA_ "GenSigTimeoutTime_EPS" SG_ 1066 DriverDoorSts 0;
BA_ "GenSigTimeoutTime_PAM" SG_ 1066 DriverDoorSts 0;
BA_ "GenSigTimeoutTime_SGW" SG_ 1066 DriverDoorSts 0;
BA_ "GenSigTimeoutTime_TRSKM" SG_ 1066 DriverDoorSts 0;
BA_ "GenSigTimeoutTime_BCM" SG_ 1066 ExternalTemperature 0;
BA_ "GenSigTimeoutTime_BSM2" SG_ 1066 ExternalTemperature 0;
BA_ "GenSigTimeoutTime_CADM2" SG_ 1066 ExternalTemperature 0;
BA_ "GenSigTimeoutTime_EPS" SG_ 1066 ExternalTemperature 0;
BA_ "GenSigTimeoutTime_SGW" SG_ 1066 ExternalTemperature 0;
BA_ "GenSigTimeoutTime_TRSKM" SG_ 1066 ExternalTemperature 0;
BA_ "GenSigTimeoutTime_BCM" SG_ 1066 FrontWiperMoveSts 0;
BA_ "GenSigTimeoutTime_BSM2" SG_ 1066 FrontWiperMoveSts 0;
BA_ "GenSigTimeoutTime_CADM2" SG_ 1066 FrontWiperMoveSts 0;
BA_ "GenSigTimeoutTime_CVADAS" SG_ 1066 FrontWiperMoveSts 0;
BA_ "GenSigTimeoutTime_EPS" SG_ 1066 FrontWiperMoveSts 0;
BA_ "GenSigTimeoutTime_ORC" SG_ 1066 FrontWiperMoveSts 0;
BA_ "GenSigTimeoutTime_PAM" SG_ 1066 FrontWiperMoveSts 0;
BA_ "GenSigTimeoutTime_SGW" SG_ 1066 FrontWiperMoveSts 0;
BA_ "GenSigTimeoutTime_TRSKM" SG_ 1066 FrontWiperMoveSts 0;
BA_ "GenSigTimeoutTime_BCM" SG_ 1066 FuelLevel 0;
BA_ "GenSigTimeoutTime_BSM2" SG_ 1066 FuelLevel 0;
BA_ "GenSigTimeoutTime_CADM2" SG_ 1066 FuelLevel 0;
BA_ "GenSigTimeoutTime_CVADAS" SG_ 1066 FuelLevel 0;
BA_ "GenSigTimeoutTime_EPS" SG_ 1066 FuelLevel 0;
BA_ "GenSigTimeoutTime_PAM" SG_ 1066 FuelLevel 0;
BA_ "GenSigTimeoutTime_SGW" SG_ 1066 FuelLevel 0;
BA_ "GenSigTimeoutTime_TRSKM" SG_ 1066 FuelLevel 0;
BA_ "GenSigSendType" SG_ 1066 HDCFnRqstSts 3;
BA_ "GenSigTimeoutTime_BCM" SG_ 1066 HDCFnRqstSts 0;
BA_ "GenSigTimeoutTime_BSM2" SG_ 1066 HDCFnRqstSts 0;
BA_ "GenSigTimeoutTime_CADM2" SG_ 1066 HDCFnRqstSts 0;
BA_ "GenSigTimeoutTime_CVADAS" SG_ 1066 HDCFnRqstSts 0;
BA_ "GenSigTimeoutTime_EPS" SG_ 1066 HDCFnRqstSts 0;
BA_ "GenSigTimeoutTime_PAM" SG_ 1066 HDCFnRqstSts 0;
BA_ "GenSigTimeoutTime_SGW" SG_ 1066 HDCFnRqstSts 0;
BA_ "GenSigTimeoutTime_TRSKM" SG_ 1066 HDCFnRqstSts 0;
BA_ "GenSigSendType" SG_ 1066 HighBeamSts 3;
BA_ "GenSigTimeoutTime_BCM" SG_ 1066 HighBeamSts 0;
BA_ "GenSigTimeoutTime_BSM2" SG_ 1066 HighBeamSts 0;
BA_ "GenSigTimeoutTime_CADM2" SG_ 1066 HighBeamSts 0;
BA_ "GenSigTimeoutTime_CVADAS" SG_ 1066 HighBeamSts 0;
BA_ "GenSigTimeoutTime_EPS" SG_ 1066 HighBeamSts 0;
BA_ "GenSigTimeoutTime_PAM" SG_ 1066 HighBeamSts 0;
BA_ "GenSigTimeoutTime_SGW" SG_ 1066 HighBeamSts 0;
BA_ "GenSigTimeoutTime_TRSKM" SG_ 1066 HighBeamSts 0;
BA_ "GenSigSendType" SG_ 1066 LHRDoorSts 3;
BA_ "GenSigTimeoutTime_BCM" SG_ 1066 LHRDoorSts 0;
BA_ "GenSigTimeoutTime_BSM2" SG_ 1066 LHRDoorSts 0;
BA_ "GenSigTimeoutTime_CADM2" SG_ 1066 LHRDoorSts 0;
BA_ "GenSigTimeoutTime_EPS" SG_ 1066 LHRDoorSts 0;
BA_ "GenSigTimeoutTime_PAM" SG_ 1066 LHRDoorSts 0;
BA_ "GenSigTimeoutTime_SGW" SG_ 1066 LHRDoorSts 0;
BA_ "GenSigTimeoutTime_TRSKM" SG_ 1066 LHRDoorSts 0;
BA_ "GenSigTimeoutTime_BCM" SG_ 1066 LowBeamSts 0;
BA_ "GenSigTimeoutTime_BSM2" SG_ 1066 LowBeamSts 0;
BA_ "GenSigTimeoutTime_CADM2" SG_ 1066 LowBeamSts 0;
BA_ "GenSigTimeoutTime_CVADAS" SG_ 1066 LowBeamSts 0;
BA_ "GenSigTimeoutTime_EPS" SG_ 1066 LowBeamSts 0;
BA_ "GenSigTimeoutTime_PAM" SG_ 1066 LowBeamSts 0;
BA_ "GenSigTimeoutTime_SGW" SG_ 1066 LowBeamSts 0;
BA_ "GenSigTimeoutTime_TRSKM" SG_ 1066 LowBeamSts 0;
BA_ "GenSigSendType" SG_ 1066 LowFuelWarningSts 3;
BA_ "GenSigTimeoutTime_BCM" SG_ 1066 LowFuelWarningSts 0;
BA_ "GenSigTimeoutTime_BSM2" SG_ 1066 LowFuelWarningSts 0;
BA_ "GenSigTimeoutTime_CADM2" SG_ 1066 LowFuelWarningSts 0;
BA_ "GenSigTimeoutTime_CVADAS" SG_ 1066 LowFuelWarningSts 0;
BA_ "GenSigTimeoutTime_EPS" SG_ 1066 LowFuelWarningSts 0;
BA_ "GenSigTimeoutTime_ORC" SG_ 1066 LowFuelWarningSts 0;
BA_ "GenSigTimeoutTime_PAM" SG_ 1066 LowFuelWarningSts 0;
BA_ "GenSigTimeoutTime_SGW" SG_ 1066 LowFuelWarningSts 0;
BA_ "GenSigTimeoutTime_TRSKM" SG_ 1066 LowFuelWarningSts 0;
BA_ "GenSigTimeoutTime_BCM" SG_ 1066 MessageCounter_BCM9 0;
BA_ "GenSigTimeoutTime_BSM2" SG_ 1066 MessageCounter_BCM9 0;
BA_ "GenSigTimeoutTime_EPS" SG_ 1066 MessageCounter_BCM9 0;
BA_ "GenSigTimeoutTime_ORC" SG_ 1066 MessageCounter_BCM9 0;
BA_ "GenSigTimeoutTime_PAM" SG_ 1066 MessageCounter_BCM9 0;
BA_ "GenSigTimeoutTime_SGW" SG_ 1066 MessageCounter_BCM9 0;
BA_ "GenSigTimeoutTime_TRSKM" SG_ 1066 MessageCounter_BCM9 0;
BA_ "GenSigSendType" SG_ 1066 ParkBrakeSts 3;
BA_ "GenSigTimeoutTime_BCM" SG_ 1066 ParkBrakeSts 0;
BA_ "GenSigTimeoutTime_BSM2" SG_ 1066 ParkBrakeSts 0;
BA_ "GenSigTimeoutTime_CADM2" SG_ 1066 ParkBrakeSts 0;
BA_ "GenSigTimeoutTime_CVADAS" SG_ 1066 ParkBrakeSts 0;
BA_ "GenSigTimeoutTime_EPS" SG_ 1066 ParkBrakeSts 0;
BA_ "GenSigTimeoutTime_PAM" SG_ 1066 ParkBrakeSts 0;
BA_ "GenSigTimeoutTime_SGW" SG_ 1066 ParkBrakeSts 0;
BA_ "GenSigTimeoutTime_TRSKM" SG_ 1066 ParkBrakeSts 0;
BA_ "GenSigTimeoutTime_BCM" SG_ 1066 PowerModeSts 0;
BA_ "GenSigTimeoutTime_BSM2" SG_ 1066 PowerModeSts 0;
BA_ "GenSigTimeoutTime_CVADAS" SG_ 1066 PowerModeSts 0;
BA_ "GenSigTimeoutTime_EPS" SG_ 1066 PowerModeSts 0;
BA_ "GenSigTimeoutTime_ORC" SG_ 1066 PowerModeSts 0;
BA_ "GenSigTimeoutTime_PAM" SG_ 1066 PowerModeSts 0;
BA_ "GenSigTimeoutTime_SGW" SG_ 1066 PowerModeSts 0;
BA_ "GenSigTimeoutTime_TRSKM" SG_ 1066 PowerModeSts 0;
BA_ "GenSigSendType" SG_ 1066 PsngrDoorSts 3;
BA_ "GenSigTimeoutTime_BCM" SG_ 1066 PsngrDoorSts 0;
BA_ "GenSigTimeoutTime_BSM2" SG_ 1066 PsngrDoorSts 0;
BA_ "GenSigTimeoutTime_CADM2" SG_ 1066 PsngrDoorSts 0;
BA_ "GenSigTimeoutTime_EPS" SG_ 1066 PsngrDoorSts 0;
BA_ "GenSigTimeoutTime_PAM" SG_ 1066 PsngrDoorSts 0;
BA_ "GenSigTimeoutTime_SGW" SG_ 1066 PsngrDoorSts 0;
BA_ "GenSigTimeoutTime_TRSKM" SG_ 1066 PsngrDoorSts 0;
BA_ "GenSigSendType" SG_ 1066 RHatchSts 3;
BA_ "GenSigTimeoutTime_BCM" SG_ 1066 RHatchSts 0;
BA_ "GenSigTimeoutTime_BSM2" SG_ 1066 RHatchSts 0;
BA_ "GenSigTimeoutTime_CADM2" SG_ 1066 RHatchSts 0;
BA_ "GenSigTimeoutTime_EPS" SG_ 1066 RHatchSts 0;
BA_ "GenSigTimeoutTime_PAM" SG_ 1066 RHatchSts 0;
BA_ "GenSigTimeoutTime_TRSKM" SG_ 1066 RHatchSts 0;
BA_ "GenSigSendType" SG_ 1066 RHRDoorSts 3;
BA_ "GenSigTimeoutTime_BCM" SG_ 1066 RHRDoorSts 0;
BA_ "GenSigTimeoutTime_BSM2" SG_ 1066 RHRDoorSts 0;
BA_ "GenSigTimeoutTime_CADM2" SG_ 1066 RHRDoorSts 0;
BA_ "GenSigTimeoutTime_EPS" SG_ 1066 RHRDoorSts 0;
BA_ "GenSigTimeoutTime_PAM" SG_ 1066 RHRDoorSts 0;
BA_ "GenSigTimeoutTime_SGW" SG_ 1066 RHRDoorSts 0;
BA_ "GenSigTimeoutTime_TRSKM" SG_ 1066 RHRDoorSts 0;
BA_ "GenSigTimeoutTime_BCM" SG_ 1066 StopLightFault 0;
BA_ "GenSigTimeoutTime_BSM2" SG_ 1066 StopLightFault 0;
BA_ "GenSigTimeoutTime_CADM2" SG_ 1066 StopLightFault 0;
BA_ "GenSigTimeoutTime_CVADAS" SG_ 1066 StopLightFault 0;
BA_ "GenSigTimeoutTime_EPS" SG_ 1066 StopLightFault 0;
BA_ "GenSigTimeoutTime_PAM" SG_ 1066 StopLightFault 0;
BA_ "GenSigTimeoutTime_SGW" SG_ 1066 StopLightFault 0;
BA_ "GenSigTimeoutTime_TRSKM" SG_ 1066 StopLightFault 0;
BA_ "GenSigSendType" SG_ 1066 StopLightSts 3;
BA_ "GenSigTimeoutTime_BCM" SG_ 1066 StopLightSts 0;
BA_ "GenSigTimeoutTime_BSM2" SG_ 1066 StopLightSts 0;
BA_ "GenSigTimeoutTime_CADM2" SG_ 1066 StopLightSts 0;
BA_ "GenSigTimeoutTime_CVADAS" SG_ 1066 StopLightSts 0;
BA_ "GenSigTimeoutTime_EPS" SG_ 1066 StopLightSts 0;
BA_ "GenSigTimeoutTime_ORC" SG_ 1066 StopLightSts 0;
BA_ "GenSigTimeoutTime_PAM" SG_ 1066 StopLightSts 0;
BA_ "GenSigTimeoutTime_SGW" SG_ 1066 StopLightSts 0;
BA_ "GenSigTimeoutTime_TRSKM" SG_ 1066 StopLightSts 0;
BA_ "GenSigTimeoutTime_BCM" SG_ 513 ACCFSafe 0;
BA_ "GenSigTimeoutTime_BSM2" SG_ 513 ACCFSafe 0;
BA_ "GenSigTimeoutTime_CVADAS" SG_ 513 ACCFSafe 0;
BA_ "GenSigTimeoutTime_EPS" SG_ 513 ACCFSafe 0;
BA_ "GenSigTimeoutTime_ORC" SG_ 513 ACCFSafe 0;
BA_ "GenSigTimeoutTime_PAM" SG_ 513 ACCFSafe 0;
BA_ "GenSigTimeoutTime_SGW" SG_ 513 ACCFSafe 0;
BA_ "GenSigTimeoutTime_TRSKM" SG_ 513 ACCFSafe 0;
BA_ "GenSigStartValue" SG_ 513 BrkTrq 32767;
BA_ "GenSigTimeoutTime_BCM" SG_ 513 BrkTrq 0;
BA_ "GenSigTimeoutTime_BSM2" SG_ 513 BrkTrq 0;
BA_ "GenSigTimeoutTime_CADM2" SG_ 513 BrkTrq 0;
BA_ "GenSigTimeoutTime_CVADAS" SG_ 513 BrkTrq 0;
BA_ "GenSigTimeoutTime_EPS" SG_ 513 BrkTrq 0;
BA_ "GenSigTimeoutTime_PAM" SG_ 513 BrkTrq 0;
BA_ "GenSigTimeoutTime_SGW" SG_ 513 BrkTrq 0;
BA_ "GenSigTimeoutTime_TRSKM" SG_ 513 BrkTrq 0;
BA_ "GenSigStartValue" SG_ 513 BrkTrq_Driver 32767;
BA_ "GenSigTimeoutTime_BCM" SG_ 513 BrkTrq_Driver 0;
BA_ "GenSigTimeoutTime_BSM2" SG_ 513 BrkTrq_Driver 0;
BA_ "GenSigTimeoutTime_CVADAS" SG_ 513 BrkTrq_Driver 0;
BA_ "GenSigTimeoutTime_EPS" SG_ 513 BrkTrq_Driver 0;
BA_ "GenSigTimeoutTime_PAM" SG_ 513 BrkTrq_Driver 0;
BA_ "GenSigTimeoutTime_SGW" SG_ 513 BrkTrq_Driver 0;
BA_ "GenSigTimeoutTime_TRSKM" SG_ 513 BrkTrq_Driver 0;
BA_ "GenSigTimeoutTime_BCM" SG_ 513 CRC_BRAKE1 0;
BA_ "GenSigTimeoutTime_CVADAS" SG_ 513 CRC_BRAKE1 0;
BA_ "GenSigTimeoutTime_EPS" SG_ 513 CRC_BRAKE1 0;
BA_ "GenSigTimeoutTime_PAM" SG_ 513 CRC_BRAKE1 0;
BA_ "GenSigTimeoutTime_SGW" SG_ 513 CRC_BRAKE1 0;
BA_ "GenSigTimeoutTime_TRSKM" SG_ 513 CRC_BRAKE1 0;
BA_ "GenSigTimeoutTime_BCM" SG_ 513 MessageCounter_BRAKE1 0;
BA_ "GenSigTimeoutTime_CVADAS" SG_ 513 MessageCounter_BRAKE1 0;
BA_ "GenSigTimeoutTime_EPS" SG_ 513 MessageCounter_BRAKE1 0;
BA_ "GenSigTimeoutTime_PAM" SG_ 513 MessageCounter_BRAKE1 0;
BA_ "GenSigTimeoutTime_SGW" SG_ 513 MessageCounter_BRAKE1 0;
BA_ "GenSigTimeoutTime_TRSKM" SG_ 513 MessageCounter_BRAKE1 0;
BA_ "GenSigStartValue" SG_ 513 REF_VEH_SPEED 1023;
BA_ "GenSigTimeoutTime_BCM" SG_ 513 REF_VEH_SPEED 0;
BA_ "GenSigTimeoutTime_BSM2" SG_ 513 REF_VEH_SPEED 0;
BA_ "GenSigTimeoutTime_CADM2" SG_ 513 REF_VEH_SPEED 0;
BA_ "GenSigTimeoutTime_EPS" SG_ 513 REF_VEH_SPEED 0;
BA_ "GenSigTimeoutTime_PAM" SG_ 513 REF_VEH_SPEED 0;
BA_ "GenSigTimeoutTime_SGW" SG_ 513 REF_VEH_SPEED 0;
BA_ "GenSigTimeoutTime_TRSKM" SG_ 513 REF_VEH_SPEED 0;
BA_ "GenSigTimeoutTime_BCM" SG_ 513 SelSpdLmp 0;
BA_ "GenSigTimeoutTime_BSM2" SG_ 513 SelSpdLmp 0;
BA_ "GenSigTimeoutTime_CADM2" SG_ 513 SelSpdLmp 0;
BA_ "GenSigTimeoutTime_CVADAS" SG_ 513 SelSpdLmp 0;
BA_ "GenSigTimeoutTime_EPS" SG_ 513 SelSpdLmp 0;
BA_ "GenSigTimeoutTime_PAM" SG_ 513 SelSpdLmp 0;
BA_ "GenSigTimeoutTime_SGW" SG_ 513 SelSpdLmp 0;
BA_ "GenSigTimeoutTime_TRSKM" SG_ 513 SelSpdLmp 0;
BA_ "GenSigStartValue" SG_ 513 VehicleStandStillSts 1;
BA_ "GenSigTimeoutTime_BCM" SG_ 513 VehicleStandStillSts 0;
BA_ "GenSigTimeoutTime_EPS" SG_ 513 VehicleStandStillSts 0;
BA_ "GenSigTimeoutTime_ORC" SG_ 513 VehicleStandStillSts 0;
BA_ "GenSigTimeoutTime_PAM" SG_ 513 VehicleStandStillSts 0;
BA_ "GenSigTimeoutTime_SGW" SG_ 513 VehicleStandStillSts 0;
BA_ "GenSigTimeoutTime_TRSKM" SG_ 513 VehicleStandStillSts 0;
BA_ "GenSigTimeoutTime_BCM" SG_ 258 ABSActive 0;
BA_ "GenSigTimeoutTime_BSM2" SG_ 258 ABSActive 0;
BA_ "GenSigTimeoutTime_CADM2" SG_ 258 ABSActive 0;
BA_ "GenSigTimeoutTime_CVADAS" SG_ 258 ABSActive 0;
BA_ "GenSigTimeoutTime_EPS" SG_ 258 ABSActive 0;
BA_ "GenSigTimeoutTime_PAM" SG_ 258 ABSActive 0;
BA_ "GenSigTimeoutTime_SGW" SG_ 258 ABSActive 0;
BA_ "GenSigTimeoutTime_TRSKM" SG_ 258 ABSActive 0;
BA_ "GenSigStartValue" SG_ 258 BrakeBoostPressure 2047;
BA_ "GenSigTimeoutTime_BCM" SG_ 258 BrakeBoostPressure 0;
BA_ "GenSigTimeoutTime_BSM2" SG_ 258 BrakeBoostPressure 0;
BA_ "GenSigTimeoutTime_CADM2" SG_ 258 BrakeBoostPressure 0;
BA_ "GenSigTimeoutTime_CVADAS" SG_ 258 BrakeBoostPressure 0;
BA_ "GenSigTimeoutTime_EPS" SG_ 258 BrakeBoostPressure 0;
BA_ "GenSigTimeoutTime_PAM" SG_ 258 BrakeBoostPressure 0;
BA_ "GenSigTimeoutTime_SGW" SG_ 258 BrakeBoostPressure 0;
BA_ "GenSigTimeoutTime_TRSKM" SG_ 258 BrakeBoostPressure 0;
BA_ "GenSigTimeoutTime_BCM" SG_ 258 BrakeInterventionSts 0;
BA_ "GenSigTimeoutTime_BSM2" SG_ 258 BrakeInterventionSts 0;
BA_ "GenSigTimeoutTime_CADM2" SG_ 258 BrakeInterventionSts 0;
BA_ "GenSigTimeoutTime_CVADAS" SG_ 258 BrakeInterventionSts 0;
BA_ "GenSigTimeoutTime_EPS" SG_ 258 BrakeInterventionSts 0;
BA_ "GenSigTimeoutTime_PAM" SG_ 258 BrakeInterventionSts 0;
BA_ "GenSigTimeoutTime_SGW" SG_ 258 BrakeInterventionSts 0;
BA_ "GenSigTimeoutTime_TRSKM" SG_ 258 BrakeInterventionSts 0;
BA_ "GenSigStartValue" SG_ 258 BrakePedalPressure 2047;
BA_ "GenSigTimeoutTime_BCM" SG_ 258 BrakePedalPressure 0;
BA_ "GenSigTimeoutTime_BSM2" SG_ 258 BrakePedalPressure 0;
BA_ "GenSigTimeoutTime_CADM2" SG_ 258 BrakePedalPressure 0;
BA_ "GenSigTimeoutTime_CVADAS" SG_ 258 BrakePedalPressure 0;
BA_ "GenSigTimeoutTime_EPS" SG_ 258 BrakePedalPressure 0;
BA_ "GenSigTimeoutTime_PAM" SG_ 258 BrakePedalPressure 0;
BA_ "GenSigTimeoutTime_SGW" SG_ 258 BrakePedalPressure 0;
BA_ "GenSigTimeoutTime_TRSKM" SG_ 258 BrakePedalPressure 0;
BA_ "GenSigTimeoutTime_BCM" SG_ 258 Brk_Stat 0;
BA_ "GenSigTimeoutTime_BSM2" SG_ 258 Brk_Stat 0;
BA_ "GenSigTimeoutTime_CADM2" SG_ 258 Brk_Stat 0;
BA_ "GenSigTimeoutTime_EPS" SG_ 258 Brk_Stat 0;
BA_ "GenSigTimeoutTime_SGW" SG_ 258 Brk_Stat 0;
BA_ "GenSigTimeoutTime_TRSKM" SG_ 258 Brk_Stat 0;
BA_ "GenSigTimeoutTime_BCM" SG_ 258 BSM_ESASystemSts 0;
BA_ "GenSigTimeoutTime_BSM2" SG_ 258 BSM_ESASystemSts 0;
BA_ "GenSigTimeoutTime_CADM2" SG_ 258 BSM_ESASystemSts 0;
BA_ "GenSigTimeoutTime_CVADAS" SG_ 258 BSM_ESASystemSts 0;
BA_ "GenSigTimeoutTime_ORC" SG_ 258 BSM_ESASystemSts 0;
BA_ "GenSigTimeoutTime_PAM" SG_ 258 BSM_ESASystemSts 0;
BA_ "GenSigTimeoutTime_SGW" SG_ 258 BSM_ESASystemSts 0;
BA_ "GenSigTimeoutTime_TRSKM" SG_ 258 BSM_ESASystemSts 0;
BA_ "GenSigTimeoutTime_BCM" SG_ 258 CRC_BRAKE2 0;
BA_ "GenSigTimeoutTime_SGW" SG_ 258 CRC_BRAKE2 0;
BA_ "GenSigTimeoutTime_TRSKM" SG_ 258 CRC_BRAKE2 0;
BA_ "GenSigTimeoutTime_BCM" SG_ 258 ESCActive 0;
BA_ "GenSigTimeoutTime_BSM2" SG_ 258 ESCActive 0;
BA_ "GenSigTimeoutTime_CADM2" SG_ 258 ESCActive 0;
BA_ "GenSigTimeoutTime_CVADAS" SG_ 258 ESCActive 0;
BA_ "GenSigTimeoutTime_EPS" SG_ 258 ESCActive 0;
BA_ "GenSigTimeoutTime_PAM" SG_ 258 ESCActive 0;
BA_ "GenSigTimeoutTime_SGW" SG_ 258 ESCActive 0;
BA_ "GenSigTimeoutTime_TRSKM" SG_ 258 ESCActive 0;
BA_ "GenSigTimeoutTime_BCM" SG_ 258 HBAActive 0;
BA_ "GenSigTimeoutTime_BSM2" SG_ 258 HBAActive 0;
BA_ "GenSigTimeoutTime_CADM2" SG_ 258 HBAActive 0;
BA_ "GenSigTimeoutTime_CVADAS" SG_ 258 HBAActive 0;
BA_ "GenSigTimeoutTime_EPS" SG_ 258 HBAActive 0;
BA_ "GenSigTimeoutTime_PAM" SG_ 258 HBAActive 0;
BA_ "GenSigTimeoutTime_SGW" SG_ 258 HBAActive 0;
BA_ "GenSigTimeoutTime_TRSKM" SG_ 258 HBAActive 0;
BA_ "GenSigTimeoutTime_BCM" SG_ 258 HillHolderActive 0;
BA_ "GenSigTimeoutTime_BSM2" SG_ 258 HillHolderActive 0;
BA_ "GenSigTimeoutTime_CADM2" SG_ 258 HillHolderActive 0;
BA_ "GenSigTimeoutTime_CVADAS" SG_ 258 HillHolderActive 0;
BA_ "GenSigTimeoutTime_EPS" SG_ 258 HillHolderActive 0;
BA_ "GenSigTimeoutTime_PAM" SG_ 258 HillHolderActive 0;
BA_ "GenSigTimeoutTime_SGW" SG_ 258 HillHolderActive 0;
BA_ "GenSigTimeoutTime_TRSKM" SG_ 258 HillHolderActive 0;
BA_ "GenSigTimeoutTime_BCM" SG_ 258 InternalError_BSM 0;
BA_ "GenSigTimeoutTime_BSM2" SG_ 258 InternalError_BSM 0;
BA_ "GenSigTimeoutTime_CVADAS" SG_ 258 InternalError_BSM 0;
BA_ "GenSigTimeoutTime_EPS" SG_ 258 InternalError_BSM 0;
BA_ "GenSigTimeoutTime_ORC" SG_ 258 InternalError_BSM 0;
BA_ "GenSigTimeoutTime_PAM" SG_ 258 InternalError_BSM 0;
BA_ "GenSigTimeoutTime_SGW" SG_ 258 InternalError_BSM 0;
BA_ "GenSigTimeoutTime_TRSKM" SG_ 258 InternalError_BSM 0;
BA_ "GenSigStartValue" SG_ 258 LatAcceleration_BSM 4095;
BA_ "GenSigTimeoutTime_BCM" SG_ 258 LatAcceleration_BSM 0;
BA_ "GenSigTimeoutTime_BSM2" SG_ 258 LatAcceleration_BSM 0;
BA_ "GenSigTimeoutTime_ORC" SG_ 258 LatAcceleration_BSM 0;
BA_ "GenSigTimeoutTime_SGW" SG_ 258 LatAcceleration_BSM 0;
BA_ "GenSigTimeoutTime_TRSKM" SG_ 258 LatAcceleration_BSM 0;
BA_ "GenSigTimeoutTime_BCM" SG_ 258 LatAccelerationFailSts_BSM 0;
BA_ "GenSigTimeoutTime_BSM2" SG_ 258 LatAccelerationFailSts_BSM 0;
BA_ "GenSigTimeoutTime_CADM2" SG_ 258 LatAccelerationFailSts_BSM 0;
BA_ "GenSigTimeoutTime_CVADAS" SG_ 258 LatAccelerationFailSts_BSM 0;
BA_ "GenSigTimeoutTime_EPS" SG_ 258 LatAccelerationFailSts_BSM 0;
BA_ "GenSigTimeoutTime_ORC" SG_ 258 LatAccelerationFailSts_BSM 0;
BA_ "GenSigTimeoutTime_SGW" SG_ 258 LatAccelerationFailSts_BSM 0;
BA_ "GenSigTimeoutTime_TRSKM" SG_ 258 LatAccelerationFailSts_BSM 0;
BA_ "GenSigStartValue" SG_ 258 LongAcceleration_BSM 4095;
BA_ "GenSigTimeoutTime_BCM" SG_ 258 LongAcceleration_BSM 0;
BA_ "GenSigTimeoutTime_BSM2" SG_ 258 LongAcceleration_BSM 0;
BA_ "GenSigTimeoutTime_ORC" SG_ 258 LongAcceleration_BSM 0;
BA_ "GenSigTimeoutTime_SGW" SG_ 258 LongAcceleration_BSM 0;
BA_ "GenSigTimeoutTime_TRSKM" SG_ 258 LongAcceleration_BSM 0;
BA_ "GenSigTimeoutTime_BCM" SG_ 258 LongAccelerationFailSts_BSM 0;
BA_ "GenSigTimeoutTime_BSM2" SG_ 258 LongAccelerationFailSts_BSM 0;
BA_ "GenSigTimeoutTime_CADM2" SG_ 258 LongAccelerationFailSts_BSM 0;
BA_ "GenSigTimeoutTime_CVADAS" SG_ 258 LongAccelerationFailSts_BSM 0;
BA_ "GenSigTimeoutTime_EPS" SG_ 258 LongAccelerationFailSts_BSM 0;
BA_ "GenSigTimeoutTime_ORC" SG_ 258 LongAccelerationFailSts_BSM 0;
BA_ "GenSigTimeoutTime_SGW" SG_ 258 LongAccelerationFailSts_BSM 0;
BA_ "GenSigTimeoutTime_TRSKM" SG_ 258 LongAccelerationFailSts_BSM 0;
BA_ "GenSigTimeoutTime_BCM" SG_ 258 MessageCounter_BRAKE2 0;
BA_ "GenSigTimeoutTime_SGW" SG_ 258 MessageCounter_BRAKE2 0;
BA_ "GenSigTimeoutTime_TRSKM" SG_ 258 MessageCounter_BRAKE2 0;
BA_ "GenSigTimeoutTime_BCM" SG_ 258 VehicleSpeedVSOSig 0;
BA_ "GenSigTimeoutTime_SGW" SG_ 258 VehicleSpeedVSOSig 0;
BA_ "GenSigStartValue" SG_ 258 WheelRPM_FL 65535;
BA_ "GenSigTimeoutTime_BCM" SG_ 258 WheelRPM_FL 0;
BA_ "GenSigTimeoutTime_BSM2" SG_ 258 WheelRPM_FL 0;
BA_ "GenSigTimeoutTime_CADM2" SG_ 258 WheelRPM_FL 0;
BA_ "GenSigTimeoutTime_CVADAS" SG_ 258 WheelRPM_FL 0;
BA_ "GenSigTimeoutTime_ORC" SG_ 258 WheelRPM_FL 0;
BA_ "GenSigTimeoutTime_PAM" SG_ 258 WheelRPM_FL 0;
BA_ "GenSigTimeoutTime_SGW" SG_ 258 WheelRPM_FL 0;
BA_ "GenSigTimeoutTime_TRSKM" SG_ 258 WheelRPM_FL 0;
BA_ "GenSigStartValue" SG_ 258 WheelRPM_FR 65535;
BA_ "GenSigTimeoutTime_BCM" SG_ 258 WheelRPM_FR 0;
BA_ "GenSigTimeoutTime_BSM2" SG_ 258 WheelRPM_FR 0;
BA_ "GenSigTimeoutTime_CADM2" SG_ 258 WheelRPM_FR 0;
BA_ "GenSigTimeoutTime_CVADAS" SG_ 258 WheelRPM_FR 0;
BA_ "GenSigTimeoutTime_ORC" SG_ 258 WheelRPM_FR 0;
BA_ "GenSigTimeoutTime_PAM" SG_ 258 WheelRPM_FR 0;
BA_ "GenSigTimeoutTime_SGW" SG_ 258 WheelRPM_FR 0;
BA_ "GenSigTimeoutTime_TRSKM" SG_ 258 WheelRPM_FR 0;
BA_ "GenSigStartValue" SG_ 258 YawRate_BSM 4095;
BA_ "GenSigTimeoutTime_BCM" SG_ 258 YawRate_BSM 0;
BA_ "GenSigTimeoutTime_BSM2" SG_ 258 YawRate_BSM 0;
BA_ "GenSigTimeoutTime_CADM2" SG_ 258 YawRate_BSM 0;
BA_ "GenSigTimeoutTime_SGW" SG_ 258 YawRate_BSM 0;
BA_ "GenSigTimeoutTime_TRSKM" SG_ 258 YawRate_BSM 0;
BA_ "GenSigTimeoutTime_BCM" SG_ 258 YawRateFailSts_BSM 0;
BA_ "GenSigTimeoutTime_BSM2" SG_ 258 YawRateFailSts_BSM 0;
BA_ "GenSigTimeoutTime_CADM2" SG_ 258 YawRateFailSts_BSM 0;
BA_ "GenSigTimeoutTime_CVADAS" SG_ 258 YawRateFailSts_BSM 0;
BA_ "GenSigTimeoutTime_ORC" SG_ 258 YawRateFailSts_BSM 0;
BA_ "GenSigTimeoutTime_SGW" SG_ 258 YawRateFailSts_BSM 0;
BA_ "GenSigTimeoutTime_TRSKM" SG_ 258 YawRateFailSts_BSM 0;
BA_ "GenSigTimeoutTime_BCM" SG_ 259 CRC__BRAKE3 0;
BA_ "GenSigTimeoutTime_SGW" SG_ 259 CRC__BRAKE3 0;
BA_ "GenSigTimeoutTime_TRSKM" SG_ 259 CRC__BRAKE3 0;
BA_ "GenSigStartValue" SG_ 259 LatAccelerationOffset_BSM 255;
BA_ "GenSigTimeoutTime_BCM" SG_ 259 LatAccelerationOffset_BSM 0;
BA_ "GenSigTimeoutTime_BSM2" SG_ 259 LatAccelerationOffset_BSM 0;
BA_ "GenSigTimeoutTime_CADM2" SG_ 259 LatAccelerationOffset_BSM 0;
BA_ "GenSigTimeoutTime_EPS" SG_ 259 LatAccelerationOffset_BSM 0;
BA_ "GenSigTimeoutTime_ORC" SG_ 259 LatAccelerationOffset_BSM 0;
BA_ "GenSigTimeoutTime_PAM" SG_ 259 LatAccelerationOffset_BSM 0;
BA_ "GenSigTimeoutTime_SGW" SG_ 259 LatAccelerationOffset_BSM 0;
BA_ "GenSigTimeoutTime_TRSKM" SG_ 259 LatAccelerationOffset_BSM 0;
BA_ "GenSigTimeoutTime_BCM" SG_ 259 LHF_FastPulseCounter 0;
BA_ "GenSigTimeoutTime_BSM2" SG_ 259 LHF_FastPulseCounter 0;
BA_ "GenSigTimeoutTime_ORC" SG_ 259 LHF_FastPulseCounter 0;
BA_ "GenSigTimeoutTime_SGW" SG_ 259 LHF_FastPulseCounter 0;
BA_ "GenSigTimeoutTime_TRSKM" SG_ 259 LHF_FastPulseCounter 0;
BA_ "GenSigTimeoutTime_BCM" SG_ 259 LHF_Spin 0;
BA_ "GenSigTimeoutTime_ORC" SG_ 259 LHF_Spin 0;
BA_ "GenSigTimeoutTime_SGW" SG_ 259 LHF_Spin 0;
BA_ "GenSigTimeoutTime_TRSKM" SG_ 259 LHF_Spin 0;
BA_ "GenSigTimeoutTime_BCM" SG_ 259 LHF_WheelSensorFailSts 0;
BA_ "GenSigTimeoutTime_CVADAS" SG_ 259 LHF_WheelSensorFailSts 0;
BA_ "GenSigTimeoutTime_SGW" SG_ 259 LHF_WheelSensorFailSts 0;
BA_ "GenSigTimeoutTime_TRSKM" SG_ 259 LHF_WheelSensorFailSts 0;
BA_ "GenSigTimeoutTime_BCM" SG_ 259 LHFWheelSpeed 0;
BA_ "GenSigTimeoutTime_SGW" SG_ 259 LHFWheelSpeed 0;
BA_ "GenSigTimeoutTime_TRSKM" SG_ 259 LHFWheelSpeed 0;
BA_ "GenSigTimeoutTime_BCM" SG_ 259 LHR_FastPulseCounter 0;
BA_ "GenSigTimeoutTime_BSM2" SG_ 259 LHR_FastPulseCounter 0;
BA_ "GenSigTimeoutTime_ORC" SG_ 259 LHR_FastPulseCounter 0;
BA_ "GenSigTimeoutTime_SGW" SG_ 259 LHR_FastPulseCounter 0;
BA_ "GenSigTimeoutTime_TRSKM" SG_ 259 LHR_FastPulseCounter 0;
BA_ "GenSigTimeoutTime_BCM" SG_ 259 LHR_Spin 0;
BA_ "GenSigTimeoutTime_EPS" SG_ 259 LHR_Spin 0;
BA_ "GenSigTimeoutTime_ORC" SG_ 259 LHR_Spin 0;
BA_ "GenSigTimeoutTime_PAM" SG_ 259 LHR_Spin 0;
BA_ "GenSigTimeoutTime_SGW" SG_ 259 LHR_Spin 0;
BA_ "GenSigTimeoutTime_TRSKM" SG_ 259 LHR_Spin 0;
BA_ "GenSigTimeoutTime_BCM" SG_ 259 LHR_WheelSensorFailSts 0;
BA_ "GenSigTimeoutTime_CVADAS" SG_ 259 LHR_WheelSensorFailSts 0;
BA_ "GenSigTimeoutTime_SGW" SG_ 259 LHR_WheelSensorFailSts 0;
BA_ "GenSigTimeoutTime_TRSKM" SG_ 259 LHR_WheelSensorFailSts 0;
BA_ "GenSigTimeoutTime_BCM" SG_ 259 LHRWheelSpeed 0;
BA_ "GenSigTimeoutTime_SGW" SG_ 259 LHRWheelSpeed 0;
BA_ "GenSigTimeoutTime_TRSKM" SG_ 259 LHRWheelSpeed 0;
BA_ "GenSigStartValue" SG_ 259 LongAccelerationOffset_BSM 255;
BA_ "GenSigTimeoutTime_BCM" SG_ 259 LongAccelerationOffset_BSM 0;
BA_ "GenSigTimeoutTime_BSM2" SG_ 259 LongAccelerationOffset_BSM 0;
BA_ "GenSigTimeoutTime_CADM2" SG_ 259 LongAccelerationOffset_BSM 0;
BA_ "GenSigTimeoutTime_EPS" SG_ 259 LongAccelerationOffset_BSM 0;
BA_ "GenSigTimeoutTime_ORC" SG_ 259 LongAccelerationOffset_BSM 0;
BA_ "GenSigTimeoutTime_PAM" SG_ 259 LongAccelerationOffset_BSM 0;
BA_ "GenSigTimeoutTime_SGW" SG_ 259 LongAccelerationOffset_BSM 0;
BA_ "GenSigTimeoutTime_TRSKM" SG_ 259 LongAccelerationOffset_BSM 0;
BA_ "GenSigTimeoutTime_BCM" SG_ 259 MessageCounter_BRAKE3 0;
BA_ "GenSigTimeoutTime_SGW" SG_ 259 MessageCounter_BRAKE3 0;
BA_ "GenSigTimeoutTime_TRSKM" SG_ 259 MessageCounter_BRAKE3 0;
BA_ "GenSigTimeoutTime_BCM" SG_ 259 RHF_FastPulseCounter 0;
BA_ "GenSigTimeoutTime_BSM2" SG_ 259 RHF_FastPulseCounter 0;
BA_ "GenSigTimeoutTime_ORC" SG_ 259 RHF_FastPulseCounter 0;
BA_ "GenSigTimeoutTime_SGW" SG_ 259 RHF_FastPulseCounter 0;
BA_ "GenSigTimeoutTime_TRSKM" SG_ 259 RHF_FastPulseCounter 0;
BA_ "GenSigTimeoutTime_BCM" SG_ 259 RHF_Spin 0;
BA_ "GenSigTimeoutTime_ORC" SG_ 259 RHF_Spin 0;
BA_ "GenSigTimeoutTime_SGW" SG_ 259 RHF_Spin 0;
BA_ "GenSigTimeoutTime_TRSKM" SG_ 259 RHF_Spin 0;
BA_ "GenSigTimeoutTime_BCM" SG_ 259 RHF_WheelSensorFailSts 0;
BA_ "GenSigTimeoutTime_CVADAS" SG_ 259 RHF_WheelSensorFailSts 0;
BA_ "GenSigTimeoutTime_SGW" SG_ 259 RHF_WheelSensorFailSts 0;
BA_ "GenSigTimeoutTime_TRSKM" SG_ 259 RHF_WheelSensorFailSts 0;
BA_ "GenSigTimeoutTime_BCM" SG_ 259 RHFWheelSpeed 0;
BA_ "GenSigTimeoutTime_SGW" SG_ 259 RHFWheelSpeed 0;
BA_ "GenSigTimeoutTime_TRSKM" SG_ 259 RHFWheelSpeed 0;
BA_ "GenSigTimeoutTime_BCM" SG_ 259 RHR_FastPulseCounter 0;
BA_ "GenSigTimeoutTime_BSM2" SG_ 259 RHR_FastPulseCounter 0;
BA_ "GenSigTimeoutTime_ORC" SG_ 259 RHR_FastPulseCounter 0;
BA_ "GenSigTimeoutTime_SGW" SG_ 259 RHR_FastPulseCounter 0;
BA_ "GenSigTimeoutTime_TRSKM" SG_ 259 RHR_FastPulseCounter 0;
BA_ "GenSigTimeoutTime_BCM" SG_ 259 RHR_Spin 0;
BA_ "GenSigTimeoutTime_EPS" SG_ 259 RHR_Spin 0;
BA_ "GenSigTimeoutTime_ORC" SG_ 259 RHR_Spin 0;
BA_ "GenSigTimeoutTime_PAM" SG_ 259 RHR_Spin 0;
BA_ "GenSigTimeoutTime_SGW" SG_ 259 RHR_Spin 0;
BA_ "GenSigTimeoutTime_TRSKM" SG_ 259 RHR_Spin 0;
BA_ "GenSigTimeoutTime_BCM" SG_ 259 RHR_WheelSensorFailSts 0;
BA_ "GenSigTimeoutTime_CVADAS" SG_ 259 RHR_WheelSensorFailSts 0;
BA_ "GenSigTimeoutTime_SGW" SG_ 259 RHR_WheelSensorFailSts 0;
BA_ "GenSigTimeoutTime_TRSKM" SG_ 259 RHR_WheelSensorFailSts 0;
BA_ "GenSigTimeoutTime_BCM" SG_ 259 RHRWheelSpeed 0;
BA_ "GenSigTimeoutTime_SGW" SG_ 259 RHRWheelSpeed 0;
BA_ "GenSigTimeoutTime_TRSKM" SG_ 259 RHRWheelSpeed 0;
BA_ "GenSigTimeoutTime_BCM" SG_ 609 ClampForce 0;
BA_ "GenSigTimeoutTime_BSM2" SG_ 609 ClampForce 0;
BA_ "GenSigTimeoutTime_CADM2" SG_ 609 ClampForce 0;
BA_ "GenSigTimeoutTime_CVADAS" SG_ 609 ClampForce 0;
BA_ "GenSigTimeoutTime_EPS" SG_ 609 ClampForce 0;
BA_ "GenSigTimeoutTime_PAM" SG_ 609 ClampForce 0;
BA_ "GenSigTimeoutTime_SGW" SG_ 609 ClampForce 0;
BA_ "GenSigTimeoutTime_TRSKM" SG_ 609 ClampForce 0;
BA_ "GenSigTimeoutTime_BCM" SG_ 609 CRC_BRAKE4 0;
BA_ "GenSigTimeoutTime_CVADAS" SG_ 609 CRC_BRAKE4 0;
BA_ "GenSigTimeoutTime_EPS" SG_ 609 CRC_BRAKE4 0;
BA_ "GenSigTimeoutTime_ORC" SG_ 609 CRC_BRAKE4 0;
BA_ "GenSigTimeoutTime_PAM" SG_ 609 CRC_BRAKE4 0;
BA_ "GenSigTimeoutTime_SGW" SG_ 609 CRC_BRAKE4 0;
BA_ "GenSigTimeoutTime_TRSKM" SG_ 609 CRC_BRAKE4 0;
BA_ "GenSigSendType" SG_ 609 EPBSts 3;
BA_ "GenSigTimeoutTime_BCM" SG_ 609 EPBSts 0;
BA_ "GenSigTimeoutTime_SGW" SG_ 609 EPBSts 0;
BA_ "GenSigTimeoutTime_TRSKM" SG_ 609 EPBSts 0;
BA_ "GenSigTimeoutTime_BCM" SG_ 609 EPBSwitchPosition 0;
BA_ "GenSigTimeoutTime_BSM2" SG_ 609 EPBSwitchPosition 0;
BA_ "GenSigTimeoutTime_CADM2" SG_ 609 EPBSwitchPosition 0;
BA_ "GenSigTimeoutTime_CVADAS" SG_ 609 EPBSwitchPosition 0;
BA_ "GenSigTimeoutTime_EPS" SG_ 609 EPBSwitchPosition 0;
BA_ "GenSigTimeoutTime_PAM" SG_ 609 EPBSwitchPosition 0;
BA_ "GenSigTimeoutTime_SGW" SG_ 609 EPBSwitchPosition 0;
BA_ "GenSigTimeoutTime_TRSKM" SG_ 609 EPBSwitchPosition 0;
BA_ "GenSigTimeoutTime_BCM" SG_ 609 EPBWarningLampReq 0;
BA_ "GenSigTimeoutTime_BSM2" SG_ 609 EPBWarningLampReq 0;
BA_ "GenSigTimeoutTime_CADM2" SG_ 609 EPBWarningLampReq 0;
BA_ "GenSigTimeoutTime_CVADAS" SG_ 609 EPBWarningLampReq 0;
BA_ "GenSigTimeoutTime_EPS" SG_ 609 EPBWarningLampReq 0;
BA_ "GenSigTimeoutTime_PAM" SG_ 609 EPBWarningLampReq 0;
BA_ "GenSigTimeoutTime_SGW" SG_ 609 EPBWarningLampReq 0;
BA_ "GenSigTimeoutTime_TRSKM" SG_ 609 EPBWarningLampReq 0;
BA_ "GenSigTimeoutTime_BCM" SG_ 609 ESC_OFF_Hrd_Sft_Button_sts 0;
BA_ "GenSigTimeoutTime_BSM2" SG_ 609 ESC_OFF_Hrd_Sft_Button_sts 0;
BA_ "GenSigTimeoutTime_CADM2" SG_ 609 ESC_OFF_Hrd_Sft_Button_sts 0;
BA_ "GenSigTimeoutTime_CVADAS" SG_ 609 ESC_OFF_Hrd_Sft_Button_sts 0;
BA_ "GenSigTimeoutTime_EPS" SG_ 609 ESC_OFF_Hrd_Sft_Button_sts 0;
BA_ "GenSigTimeoutTime_PAM" SG_ 609 ESC_OFF_Hrd_Sft_Button_sts 0;
BA_ "GenSigTimeoutTime_SGW" SG_ 609 ESC_OFF_Hrd_Sft_Button_sts 0;
BA_ "GenSigTimeoutTime_TRSKM" SG_ 609 ESC_OFF_Hrd_Sft_Button_sts 0;
BA_ "GenSigTimeoutTime_BCM" SG_ 609 MessageCounter_BRAKE4 0;
BA_ "GenSigTimeoutTime_CVADAS" SG_ 609 MessageCounter_BRAKE4 0;
BA_ "GenSigTimeoutTime_EPS" SG_ 609 MessageCounter_BRAKE4 0;
BA_ "GenSigTimeoutTime_ORC" SG_ 609 MessageCounter_BRAKE4 0;
BA_ "GenSigTimeoutTime_PAM" SG_ 609 MessageCounter_BRAKE4 0;
BA_ "GenSigTimeoutTime_SGW" SG_ 609 MessageCounter_BRAKE4 0;
BA_ "GenSigTimeoutTime_TRSKM" SG_ 609 MessageCounter_BRAKE4 0;
BA_ "GenSigSendType" SG_ 609 MSRActive 3;
BA_ "GenSigTimeoutTime_BCM" SG_ 609 MSRActive 0;
BA_ "GenSigTimeoutTime_BSM2" SG_ 609 MSRActive 0;
BA_ "GenSigTimeoutTime_CADM2" SG_ 609 MSRActive 0;
BA_ "GenSigTimeoutTime_CVADAS" SG_ 609 MSRActive 0;
BA_ "GenSigTimeoutTime_EPS" SG_ 609 MSRActive 0;
BA_ "GenSigTimeoutTime_PAM" SG_ 609 MSRActive 0;
BA_ "GenSigTimeoutTime_SGW" SG_ 609 MSRActive 0;
BA_ "GenSigTimeoutTime_TRSKM" SG_ 609 MSRActive 0;
BA_ "GenSigSendType" SG_ 1155 ABSFailSts 3;
BA_ "GenSigTimeoutTime_BCM" SG_ 1155 ABSFailSts 0;
BA_ "GenSigTimeoutTime_BSM2" SG_ 1155 ABSFailSts 0;
BA_ "GenSigTimeoutTime_CADM2" SG_ 1155 ABSFailSts 0;
BA_ "GenSigTimeoutTime_CVADAS" SG_ 1155 ABSFailSts 0;
BA_ "GenSigTimeoutTime_EPS" SG_ 1155 ABSFailSts 0;
BA_ "GenSigTimeoutTime_PAM" SG_ 1155 ABSFailSts 0;
BA_ "GenSigTimeoutTime_SGW" SG_ 1155 ABSFailSts 0;
BA_ "GenSigTimeoutTime_TRSKM" SG_ 1155 ABSFailSts 0;
BA_ "GenSigSendType" SG_ 1155 BSM_THA_Brk_Resp 4;
BA_ "GenSigTimeoutTime_BCM" SG_ 1155 BSM_THA_Brk_Resp 0;
BA_ "GenSigTimeoutTime_BSM2" SG_ 1155 BSM_THA_Brk_Resp 0;
BA_ "GenSigTimeoutTime_CADM2" SG_ 1155 BSM_THA_Brk_Resp 0;
BA_ "GenSigTimeoutTime_EPS" SG_ 1155 BSM_THA_Brk_Resp 0;
BA_ "GenSigTimeoutTime_ORC" SG_ 1155 BSM_THA_Brk_Resp 0;
BA_ "GenSigTimeoutTime_PAM" SG_ 1155 BSM_THA_Brk_Resp 0;
BA_ "GenSigTimeoutTime_SGW" SG_ 1155 BSM_THA_Brk_Resp 0;
BA_ "GenSigTimeoutTime_TRSKM" SG_ 1155 BSM_THA_Brk_Resp 0;
BA_ "GenSigTimeoutTime_BCM" SG_ 1155 CRC_BRAKE5 0;
BA_ "GenSigTimeoutTime_BSM2" SG_ 1155 CRC_BRAKE5 0;
BA_ "GenSigTimeoutTime_CADM2" SG_ 1155 CRC_BRAKE5 0;
BA_ "GenSigTimeoutTime_EPS" SG_ 1155 CRC_BRAKE5 0;
BA_ "GenSigTimeoutTime_ORC" SG_ 1155 CRC_BRAKE5 0;
BA_ "GenSigTimeoutTime_PAM" SG_ 1155 CRC_BRAKE5 0;
BA_ "GenSigTimeoutTime_SGW" SG_ 1155 CRC_BRAKE5 0;
BA_ "GenSigTimeoutTime_TRSKM" SG_ 1155 CRC_BRAKE5 0;
BA_ "GenSigSendType" SG_ 1155 EBDFailSts 3;
BA_ "GenSigTimeoutTime_BCM" SG_ 1155 EBDFailSts 0;
BA_ "GenSigTimeoutTime_BSM2" SG_ 1155 EBDFailSts 0;
BA_ "GenSigTimeoutTime_CADM2" SG_ 1155 EBDFailSts 0;
BA_ "GenSigTimeoutTime_CVADAS" SG_ 1155 EBDFailSts 0;
BA_ "GenSigTimeoutTime_EPS" SG_ 1155 EBDFailSts 0;
BA_ "GenSigTimeoutTime_PAM" SG_ 1155 EBDFailSts 0;
BA_ "GenSigTimeoutTime_SGW" SG_ 1155 EBDFailSts 0;
BA_ "GenSigTimeoutTime_TRSKM" SG_ 1155 EBDFailSts 0;
BA_ "GenSigSendType" SG_ 1155 ERMActive 3;
BA_ "GenSigTimeoutTime_BCM" SG_ 1155 ERMActive 0;
BA_ "GenSigTimeoutTime_BSM2" SG_ 1155 ERMActive 0;
BA_ "GenSigTimeoutTime_CADM2" SG_ 1155 ERMActive 0;
BA_ "GenSigTimeoutTime_CVADAS" SG_ 1155 ERMActive 0;
BA_ "GenSigTimeoutTime_EPS" SG_ 1155 ERMActive 0;
BA_ "GenSigTimeoutTime_PAM" SG_ 1155 ERMActive 0;
BA_ "GenSigTimeoutTime_SGW" SG_ 1155 ERMActive 0;
BA_ "GenSigTimeoutTime_TRSKM" SG_ 1155 ERMActive 0;
BA_ "GenSigSendType" SG_ 1155 ESCFailSts 3;
BA_ "GenSigTimeoutTime_BCM" SG_ 1155 ESCFailSts 0;
BA_ "GenSigTimeoutTime_BSM2" SG_ 1155 ESCFailSts 0;
BA_ "GenSigTimeoutTime_CADM2" SG_ 1155 ESCFailSts 0;
BA_ "GenSigTimeoutTime_CVADAS" SG_ 1155 ESCFailSts 0;
BA_ "GenSigTimeoutTime_EPS" SG_ 1155 ESCFailSts 0;
BA_ "GenSigTimeoutTime_PAM" SG_ 1155 ESCFailSts 0;
BA_ "GenSigTimeoutTime_SGW" SG_ 1155 ESCFailSts 0;
BA_ "GenSigTimeoutTime_TRSKM" SG_ 1155 ESCFailSts 0;
BA_ "GenSigSendType" SG_ 1155 ESCIntervention 3;
BA_ "GenSigTimeoutTime_BCM" SG_ 1155 ESCIntervention 0;
BA_ "GenSigTimeoutTime_BSM2" SG_ 1155 ESCIntervention 0;
BA_ "GenSigTimeoutTime_CADM2" SG_ 1155 ESCIntervention 0;
BA_ "GenSigTimeoutTime_CVADAS" SG_ 1155 ESCIntervention 0;
BA_ "GenSigTimeoutTime_EPS" SG_ 1155 ESCIntervention 0;
BA_ "GenSigTimeoutTime_PAM" SG_ 1155 ESCIntervention 0;
BA_ "GenSigTimeoutTime_SGW" SG_ 1155 ESCIntervention 0;
BA_ "GenSigTimeoutTime_TRSKM" SG_ 1155 ESCIntervention 0;
BA_ "GenSigSendType" SG_ 1155 Function2Sts 3;
BA_ "GenSigTimeoutTime_BCM" SG_ 1155 Function2Sts 0;
BA_ "GenSigTimeoutTime_BSM2" SG_ 1155 Function2Sts 0;
BA_ "GenSigTimeoutTime_CADM2" SG_ 1155 Function2Sts 0;
BA_ "GenSigTimeoutTime_CVADAS" SG_ 1155 Function2Sts 0;
BA_ "GenSigTimeoutTime_EPS" SG_ 1155 Function2Sts 0;
BA_ "GenSigTimeoutTime_PAM" SG_ 1155 Function2Sts 0;
BA_ "GenSigTimeoutTime_SGW" SG_ 1155 Function2Sts 0;
BA_ "GenSigTimeoutTime_TRSKM" SG_ 1155 Function2Sts 0;
BA_ "GenSigTimeoutTime_BCM" SG_ 1155 MessageCounter_BRAKE5 0;
BA_ "GenSigTimeoutTime_BSM2" SG_ 1155 MessageCounter_BRAKE5 0;
BA_ "GenSigTimeoutTime_CADM2" SG_ 1155 MessageCounter_BRAKE5 0;
BA_ "GenSigTimeoutTime_EPS" SG_ 1155 MessageCounter_BRAKE5 0;
BA_ "GenSigTimeoutTime_ORC" SG_ 1155 MessageCounter_BRAKE5 0;
BA_ "GenSigTimeoutTime_PAM" SG_ 1155 MessageCounter_BRAKE5 0;
BA_ "GenSigTimeoutTime_SGW" SG_ 1155 MessageCounter_BRAKE5 0;
BA_ "GenSigTimeoutTime_TRSKM" SG_ 1155 MessageCounter_BRAKE5 0;
BA_ "GenSigSendType" SG_ 1155 TSCActive 3;
BA_ "GenSigTimeoutTime_BCM" SG_ 1155 TSCActive 0;
BA_ "GenSigTimeoutTime_BSM2" SG_ 1155 TSCActive 0;
BA_ "GenSigTimeoutTime_CADM2" SG_ 1155 TSCActive 0;
BA_ "GenSigTimeoutTime_CVADAS" SG_ 1155 TSCActive 0;
BA_ "GenSigTimeoutTime_EPS" SG_ 1155 TSCActive 0;
BA_ "GenSigTimeoutTime_PAM" SG_ 1155 TSCActive 0;
BA_ "GenSigTimeoutTime_SGW" SG_ 1155 TSCActive 0;
BA_ "GenSigTimeoutTime_TRSKM" SG_ 1155 TSCActive 0;
BA_ "GenSigTimeoutTime_BCM" SG_ 514 BrakePdlPosn 0;
BA_ "GenSigTimeoutTime_BSM2" SG_ 514 BrakePdlPosn 0;
BA_ "GenSigTimeoutTime_CADM2" SG_ 514 BrakePdlPosn 0;
BA_ "GenSigTimeoutTime_CVADAS" SG_ 514 BrakePdlPosn 0;
BA_ "GenSigTimeoutTime_EPS" SG_ 514 BrakePdlPosn 0;
BA_ "GenSigTimeoutTime_PAM" SG_ 514 BrakePdlPosn 0;
BA_ "GenSigTimeoutTime_SGW" SG_ 514 BrakePdlPosn 0;
BA_ "GenSigTimeoutTime_TRSKM" SG_ 514 BrakePdlPosn 0;
BA_ "GenSigTimeoutTime_BCM" SG_ 514 BrkPdl_Flt 0;
BA_ "GenSigTimeoutTime_BSM2" SG_ 514 BrkPdl_Flt 0;
BA_ "GenSigTimeoutTime_CADM2" SG_ 514 BrkPdl_Flt 0;
BA_ "GenSigTimeoutTime_CVADAS" SG_ 514 BrkPdl_Flt 0;
BA_ "GenSigTimeoutTime_EPS" SG_ 514 BrkPdl_Flt 0;
BA_ "GenSigTimeoutTime_PAM" SG_ 514 BrkPdl_Flt 0;
BA_ "GenSigTimeoutTime_SGW" SG_ 514 BrkPdl_Flt 0;
BA_ "GenSigTimeoutTime_TRSKM" SG_ 514 BrkPdl_Flt 0;
BA_ "GenSigStartValue" SG_ 514 BrkPdl_Stat 3;
BA_ "GenSigTimeoutTime_BCM" SG_ 514 BrkPdl_Stat 0;
BA_ "GenSigTimeoutTime_CVADAS" SG_ 514 BrkPdl_Stat 0;
BA_ "GenSigTimeoutTime_EPS" SG_ 514 BrkPdl_Stat 0;
BA_ "GenSigTimeoutTime_PAM" SG_ 514 BrkPdl_Stat 0;
BA_ "GenSigTimeoutTime_SGW" SG_ 514 BrkPdl_Stat 0;
BA_ "GenSigTimeoutTime_TRSKM" SG_ 514 BrkPdl_Stat 0;
BA_ "GenSigTimeoutTime_BCM" SG_ 514 BSM_OpStat 0;
BA_ "GenSigTimeoutTime_CADM2" SG_ 514 BSM_OpStat 0;
BA_ "GenSigTimeoutTime_CVADAS" SG_ 514 BSM_OpStat 0;
BA_ "GenSigTimeoutTime_EPS" SG_ 514 BSM_OpStat 0;
BA_ "GenSigTimeoutTime_ORC" SG_ 514 BSM_OpStat 0;
BA_ "GenSigTimeoutTime_PAM" SG_ 514 BSM_OpStat 0;
BA_ "GenSigTimeoutTime_SGW" SG_ 514 BSM_OpStat 0;
BA_ "GenSigTimeoutTime_TRSKM" SG_ 514 BSM_OpStat 0;
BA_ "GenSigTimeoutTime_BCM" SG_ 514 BSM_ReadyForESS 0;
BA_ "GenSigTimeoutTime_BSM2" SG_ 514 BSM_ReadyForESS 0;
BA_ "GenSigTimeoutTime_CADM2" SG_ 514 BSM_ReadyForESS 0;
BA_ "GenSigTimeoutTime_CVADAS" SG_ 514 BSM_ReadyForESS 0;
BA_ "GenSigTimeoutTime_EPS" SG_ 514 BSM_ReadyForESS 0;
BA_ "GenSigTimeoutTime_PAM" SG_ 514 BSM_ReadyForESS 0;
BA_ "GenSigTimeoutTime_SGW" SG_ 514 BSM_ReadyForESS 0;
BA_ "GenSigTimeoutTime_TRSKM" SG_ 514 BSM_ReadyForESS 0;
BA_ "GenSigTimeoutTime_BCM" SG_ 514 CRC_BRAKE7 0;
BA_ "GenSigTimeoutTime_CVADAS" SG_ 514 CRC_BRAKE7 0;
BA_ "GenSigTimeoutTime_EPS" SG_ 514 CRC_BRAKE7 0;
BA_ "GenSigTimeoutTime_ORC" SG_ 514 CRC_BRAKE7 0;
BA_ "GenSigTimeoutTime_PAM" SG_ 514 CRC_BRAKE7 0;
BA_ "GenSigTimeoutTime_SGW" SG_ 514 CRC_BRAKE7 0;
BA_ "GenSigTimeoutTime_TRSKM" SG_ 514 CRC_BRAKE7 0;
BA_ "GenSigTimeoutTime_BCM" SG_ 514 MessageCounter_BRAKE7 0;
BA_ "GenSigTimeoutTime_CVADAS" SG_ 514 MessageCounter_BRAKE7 0;
BA_ "GenSigTimeoutTime_EPS" SG_ 514 MessageCounter_BRAKE7 0;
BA_ "GenSigTimeoutTime_ORC" SG_ 514 MessageCounter_BRAKE7 0;
BA_ "GenSigTimeoutTime_PAM" SG_ 514 MessageCounter_BRAKE7 0;
BA_ "GenSigTimeoutTime_SGW" SG_ 514 MessageCounter_BRAKE7 0;
BA_ "GenSigTimeoutTime_TRSKM" SG_ 514 MessageCounter_BRAKE7 0;
BA_ "GenSigTimeoutTime_BCM" SG_ 514 PAM_Brk_Rq_RspSts 0;
BA_ "GenSigTimeoutTime_BSM2" SG_ 514 PAM_Brk_Rq_RspSts 0;
BA_ "GenSigTimeoutTime_CADM2" SG_ 514 PAM_Brk_Rq_RspSts 0;
BA_ "GenSigTimeoutTime_CVADAS" SG_ 514 PAM_Brk_Rq_RspSts 0;
BA_ "GenSigTimeoutTime_EPS" SG_ 514 PAM_Brk_Rq_RspSts 0;
BA_ "GenSigTimeoutTime_ORC" SG_ 514 PAM_Brk_Rq_RspSts 0;
BA_ "GenSigTimeoutTime_SGW" SG_ 514 PAM_Brk_Rq_RspSts 0;
BA_ "GenSigTimeoutTime_TRSKM" SG_ 514 PAM_Brk_Rq_RspSts 0;
BA_ "GenSigTimeoutTime_BCM" SG_ 514 Rear_Diff_BSM_RQ 0;
BA_ "GenSigTimeoutTime_BSM2" SG_ 514 Rear_Diff_BSM_RQ 0;
BA_ "GenSigTimeoutTime_CADM2" SG_ 514 Rear_Diff_BSM_RQ 0;
BA_ "GenSigTimeoutTime_CVADAS" SG_ 514 Rear_Diff_BSM_RQ 0;
BA_ "GenSigTimeoutTime_EPS" SG_ 514 Rear_Diff_BSM_RQ 0;
BA_ "GenSigTimeoutTime_PAM" SG_ 514 Rear_Diff_BSM_RQ 0;
BA_ "GenSigTimeoutTime_SGW" SG_ 514 Rear_Diff_BSM_RQ 0;
BA_ "GenSigTimeoutTime_TRSKM" SG_ 514 Rear_Diff_BSM_RQ 0;
BA_ "GenSigTimeoutTime_BCM" SG_ 257 ABSActive_B2 0;
BA_ "GenSigTimeoutTime_BSM2" SG_ 257 ABSActive_B2 0;
BA_ "GenSigTimeoutTime_CVADAS" SG_ 257 ABSActive_B2 0;
BA_ "GenSigTimeoutTime_EPS" SG_ 257 ABSActive_B2 0;
BA_ "GenSigTimeoutTime_ORC" SG_ 257 ABSActive_B2 0;
BA_ "GenSigTimeoutTime_PAM" SG_ 257 ABSActive_B2 0;
BA_ "GenSigTimeoutTime_SGW" SG_ 257 ABSActive_B2 0;
BA_ "GenSigTimeoutTime_TRSKM" SG_ 257 ABSActive_B2 0;
BA_ "GenSigTimeoutTime_BSM2" SG_ 257 Brk_Stat_B2 0;
BA_ "GenSigTimeoutTime_CVADAS" SG_ 257 Brk_Stat_B2 0;
BA_ "GenSigTimeoutTime_EPS" SG_ 257 Brk_Stat_B2 0;
BA_ "GenSigTimeoutTime_ORC" SG_ 257 Brk_Stat_B2 0;
BA_ "GenSigTimeoutTime_PAM" SG_ 257 Brk_Stat_B2 0;
BA_ "GenSigTimeoutTime_SGW" SG_ 257 Brk_Stat_B2 0;
BA_ "GenSigTimeoutTime_TRSKM" SG_ 257 Brk_Stat_B2 0;
BA_ "GenSigTimeoutTime_BSM2" SG_ 257 CRC_BRAKE2_1 0;
BA_ "GenSigTimeoutTime_PAM" SG_ 257 CRC_BRAKE2_1 0;
BA_ "GenSigTimeoutTime_SGW" SG_ 257 CRC_BRAKE2_1 0;
BA_ "GenSigTimeoutTime_TRSKM" SG_ 257 CRC_BRAKE2_1 0;
BA_ "GenSigStartValue" SG_ 257 Ft_RrAxleCoupling_TrqRq_B2 254;
BA_ "GenSigTimeoutTime_BSM2" SG_ 257 Ft_RrAxleCoupling_TrqRq_B2 0;
BA_ "GenSigTimeoutTime_CADM2" SG_ 257 Ft_RrAxleCoupling_TrqRq_B2 0;
BA_ "GenSigTimeoutTime_CVADAS" SG_ 257 Ft_RrAxleCoupling_TrqRq_B2 0;
BA_ "GenSigTimeoutTime_EPS" SG_ 257 Ft_RrAxleCoupling_TrqRq_B2 0;
BA_ "GenSigTimeoutTime_ORC" SG_ 257 Ft_RrAxleCoupling_TrqRq_B2 0;
BA_ "GenSigTimeoutTime_PAM" SG_ 257 Ft_RrAxleCoupling_TrqRq_B2 0;
BA_ "GenSigTimeoutTime_SGW" SG_ 257 Ft_RrAxleCoupling_TrqRq_B2 0;
BA_ "GenSigTimeoutTime_TRSKM" SG_ 257 Ft_RrAxleCoupling_TrqRq_B2 0;
BA_ "GenSigTimeoutTime_BSM2" SG_ 257 Ft_RrTrqCoupling_ModeRq_B2 0;
BA_ "GenSigTimeoutTime_CADM2" SG_ 257 Ft_RrTrqCoupling_ModeRq_B2 0;
BA_ "GenSigTimeoutTime_CVADAS" SG_ 257 Ft_RrTrqCoupling_ModeRq_B2 0;
BA_ "GenSigTimeoutTime_EPS" SG_ 257 Ft_RrTrqCoupling_ModeRq_B2 0;
BA_ "GenSigTimeoutTime_ORC" SG_ 257 Ft_RrTrqCoupling_ModeRq_B2 0;
BA_ "GenSigTimeoutTime_PAM" SG_ 257 Ft_RrTrqCoupling_ModeRq_B2 0;
BA_ "GenSigTimeoutTime_SGW" SG_ 257 Ft_RrTrqCoupling_ModeRq_B2 0;
BA_ "GenSigTimeoutTime_TRSKM" SG_ 257 Ft_RrTrqCoupling_ModeRq_B2 0;
BA_ "GenSigTimeoutTime_BCM" SG_ 257 Inlet_Pressure_Pos 0;
BA_ "GenSigTimeoutTime_BSM2" SG_ 257 Inlet_Pressure_Pos 0;
BA_ "GenSigTimeoutTime_CVADAS" SG_ 257 Inlet_Pressure_Pos 0;
BA_ "GenSigTimeoutTime_EPS" SG_ 257 Inlet_Pressure_Pos 0;
BA_ "GenSigTimeoutTime_ORC" SG_ 257 Inlet_Pressure_Pos 0;
BA_ "GenSigTimeoutTime_PAM" SG_ 257 Inlet_Pressure_Pos 0;
BA_ "GenSigTimeoutTime_SGW" SG_ 257 Inlet_Pressure_Pos 0;
BA_ "GenSigTimeoutTime_TRSKM" SG_ 257 Inlet_Pressure_Pos 0;
BA_ "GenSigTimeoutTime_BCM" SG_ 257 LHF_FastPulseCounter_B2 0;
BA_ "GenSigTimeoutTime_BSM2" SG_ 257 LHF_FastPulseCounter_B2 0;
BA_ "GenSigTimeoutTime_CVADAS" SG_ 257 LHF_FastPulseCounter_B2 0;
BA_ "GenSigTimeoutTime_EPS" SG_ 257 LHF_FastPulseCounter_B2 0;
BA_ "GenSigTimeoutTime_ORC" SG_ 257 LHF_FastPulseCounter_B2 0;
BA_ "GenSigTimeoutTime_PAM" SG_ 257 LHF_FastPulseCounter_B2 0;
BA_ "GenSigTimeoutTime_SGW" SG_ 257 LHF_FastPulseCounter_B2 0;
BA_ "GenSigTimeoutTime_TRSKM" SG_ 257 LHF_FastPulseCounter_B2 0;
BA_ "GenSigTimeoutTime_BCM" SG_ 257 LHF_Spin_B2 0;
BA_ "GenSigTimeoutTime_BSM2" SG_ 257 LHF_Spin_B2 0;
BA_ "GenSigTimeoutTime_CVADAS" SG_ 257 LHF_Spin_B2 0;
BA_ "GenSigTimeoutTime_EPS" SG_ 257 LHF_Spin_B2 0;
BA_ "GenSigTimeoutTime_ORC" SG_ 257 LHF_Spin_B2 0;
BA_ "GenSigTimeoutTime_PAM" SG_ 257 LHF_Spin_B2 0;
BA_ "GenSigTimeoutTime_SGW" SG_ 257 LHF_Spin_B2 0;
BA_ "GenSigTimeoutTime_TRSKM" SG_ 257 LHF_Spin_B2 0;
BA_ "GenSigTimeoutTime_BCM" SG_ 257 LHF_WheelSensorFailSts_B2 0;
BA_ "GenSigTimeoutTime_BSM2" SG_ 257 LHF_WheelSensorFailSts_B2 0;
BA_ "GenSigTimeoutTime_CVADAS" SG_ 257 LHF_WheelSensorFailSts_B2 0;
BA_ "GenSigTimeoutTime_EPS" SG_ 257 LHF_WheelSensorFailSts_B2 0;
BA_ "GenSigTimeoutTime_ORC" SG_ 257 LHF_WheelSensorFailSts_B2 0;
BA_ "GenSigTimeoutTime_PAM" SG_ 257 LHF_WheelSensorFailSts_B2 0;
BA_ "GenSigTimeoutTime_SGW" SG_ 257 LHF_WheelSensorFailSts_B2 0;
BA_ "GenSigTimeoutTime_TRSKM" SG_ 257 LHF_WheelSensorFailSts_B2 0;
BA_ "GenSigTimeoutTime_BCM" SG_ 257 LHFWheelSpeed_B2 0;
BA_ "GenSigTimeoutTime_BSM2" SG_ 257 LHFWheelSpeed_B2 0;
BA_ "GenSigTimeoutTime_CVADAS" SG_ 257 LHFWheelSpeed_B2 0;
BA_ "GenSigTimeoutTime_EPS" SG_ 257 LHFWheelSpeed_B2 0;
BA_ "GenSigTimeoutTime_ORC" SG_ 257 LHFWheelSpeed_B2 0;
BA_ "GenSigTimeoutTime_PAM" SG_ 257 LHFWheelSpeed_B2 0;
BA_ "GenSigTimeoutTime_SGW" SG_ 257 LHFWheelSpeed_B2 0;
BA_ "GenSigTimeoutTime_TRSKM" SG_ 257 LHFWheelSpeed_B2 0;
BA_ "GenSigTimeoutTime_BSM2" SG_ 257 MessageCounter_BRAKE2_1 0;
BA_ "GenSigTimeoutTime_PAM" SG_ 257 MessageCounter_BRAKE2_1 0;
BA_ "GenSigTimeoutTime_SGW" SG_ 257 MessageCounter_BRAKE2_1 0;
BA_ "GenSigTimeoutTime_TRSKM" SG_ 257 MessageCounter_BRAKE2_1 0;
BA_ "GenSigStartValue" SG_ 257 R_DIFF_TRQ_RQ_B2 511;
BA_ "GenSigTimeoutTime_BCM" SG_ 257 R_DIFF_TRQ_RQ_B2 0;
BA_ "GenSigTimeoutTime_BSM2" SG_ 257 R_DIFF_TRQ_RQ_B2 0;
BA_ "GenSigTimeoutTime_CADM2" SG_ 257 R_DIFF_TRQ_RQ_B2 0;
BA_ "GenSigTimeoutTime_CVADAS" SG_ 257 R_DIFF_TRQ_RQ_B2 0;
BA_ "GenSigTimeoutTime_EPS" SG_ 257 R_DIFF_TRQ_RQ_B2 0;
BA_ "GenSigTimeoutTime_ORC" SG_ 257 R_DIFF_TRQ_RQ_B2 0;
BA_ "GenSigTimeoutTime_PAM" SG_ 257 R_DIFF_TRQ_RQ_B2 0;
BA_ "GenSigTimeoutTime_SGW" SG_ 257 R_DIFF_TRQ_RQ_B2 0;
BA_ "GenSigTimeoutTime_TRSKM" SG_ 257 R_DIFF_TRQ_RQ_B2 0;
BA_ "GenSigTimeoutTime_BCM" SG_ 257 Rear_Diff_BSM_RQ_B2 0;
BA_ "GenSigTimeoutTime_BSM2" SG_ 257 Rear_Diff_BSM_RQ_B2 0;
BA_ "GenSigTimeoutTime_CADM2" SG_ 257 Rear_Diff_BSM_RQ_B2 0;
BA_ "GenSigTimeoutTime_CVADAS" SG_ 257 Rear_Diff_BSM_RQ_B2 0;
BA_ "GenSigTimeoutTime_EPS" SG_ 257 Rear_Diff_BSM_RQ_B2 0;
BA_ "GenSigTimeoutTime_ORC" SG_ 257 Rear_Diff_BSM_RQ_B2 0;
BA_ "GenSigTimeoutTime_PAM" SG_ 257 Rear_Diff_BSM_RQ_B2 0;
BA_ "GenSigTimeoutTime_SGW" SG_ 257 Rear_Diff_BSM_RQ_B2 0;
BA_ "GenSigTimeoutTime_TRSKM" SG_ 257 Rear_Diff_BSM_RQ_B2 0;
BA_ "GenSigTimeoutTime_BCM" SG_ 257 RHF_FastPulseCounter_B2 0;
BA_ "GenSigTimeoutTime_BSM2" SG_ 257 RHF_FastPulseCounter_B2 0;
BA_ "GenSigTimeoutTime_CVADAS" SG_ 257 RHF_FastPulseCounter_B2 0;
BA_ "GenSigTimeoutTime_EPS" SG_ 257 RHF_FastPulseCounter_B2 0;
BA_ "GenSigTimeoutTime_ORC" SG_ 257 RHF_FastPulseCounter_B2 0;
BA_ "GenSigTimeoutTime_PAM" SG_ 257 RHF_FastPulseCounter_B2 0;
BA_ "GenSigTimeoutTime_SGW" SG_ 257 RHF_FastPulseCounter_B2 0;
BA_ "GenSigTimeoutTime_TRSKM" SG_ 257 RHF_FastPulseCounter_B2 0;
BA_ "GenSigTimeoutTime_BCM" SG_ 257 RHF_Spin_B2 0;
BA_ "GenSigTimeoutTime_BSM2" SG_ 257 RHF_Spin_B2 0;
BA_ "GenSigTimeoutTime_CVADAS" SG_ 257 RHF_Spin_B2 0;
BA_ "GenSigTimeoutTime_EPS" SG_ 257 RHF_Spin_B2 0;
BA_ "GenSigTimeoutTime_ORC" SG_ 257 RHF_Spin_B2 0;
BA_ "GenSigTimeoutTime_PAM" SG_ 257 RHF_Spin_B2 0;
BA_ "GenSigTimeoutTime_SGW" SG_ 257 RHF_Spin_B2 0;
BA_ "GenSigTimeoutTime_TRSKM" SG_ 257 RHF_Spin_B2 0;
BA_ "GenSigTimeoutTime_BCM" SG_ 257 RHF_WheelSensorFailSts_B2 0;
BA_ "GenSigTimeoutTime_BSM2" SG_ 257 RHF_WheelSensorFailSts_B2 0;
BA_ "GenSigTimeoutTime_CVADAS" SG_ 257 RHF_WheelSensorFailSts_B2 0;
BA_ "GenSigTimeoutTime_EPS" SG_ 257 RHF_WheelSensorFailSts_B2 0;
BA_ "GenSigTimeoutTime_ORC" SG_ 257 RHF_WheelSensorFailSts_B2 0;
BA_ "GenSigTimeoutTime_PAM" SG_ 257 RHF_WheelSensorFailSts_B2 0;
BA_ "GenSigTimeoutTime_SGW" SG_ 257 RHF_WheelSensorFailSts_B2 0;
BA_ "GenSigTimeoutTime_TRSKM" SG_ 257 RHF_WheelSensorFailSts_B2 0;
BA_ "GenSigTimeoutTime_BCM" SG_ 257 RHFWheelSpeed_B2 0;
BA_ "GenSigTimeoutTime_BSM2" SG_ 257 RHFWheelSpeed_B2 0;
BA_ "GenSigTimeoutTime_CVADAS" SG_ 257 RHFWheelSpeed_B2 0;
BA_ "GenSigTimeoutTime_EPS" SG_ 257 RHFWheelSpeed_B2 0;
BA_ "GenSigTimeoutTime_ORC" SG_ 257 RHFWheelSpeed_B2 0;
BA_ "GenSigTimeoutTime_PAM" SG_ 257 RHFWheelSpeed_B2 0;
BA_ "GenSigTimeoutTime_SGW" SG_ 257 RHFWheelSpeed_B2 0;
BA_ "GenSigTimeoutTime_TRSKM" SG_ 257 RHFWheelSpeed_B2 0;
BA_ "GenSigTimeoutTime_BCM" SG_ 257 VehicleSpeedVSOSig_B2 0;
BA_ "GenSigTimeoutTime_BSM2" SG_ 257 VehicleSpeedVSOSig_B2 0;
BA_ "GenSigTimeoutTime_CVADAS" SG_ 257 VehicleSpeedVSOSig_B2 0;
BA_ "GenSigTimeoutTime_ORC" SG_ 257 VehicleSpeedVSOSig_B2 0;
BA_ "GenSigTimeoutTime_PAM" SG_ 257 VehicleSpeedVSOSig_B2 0;
BA_ "GenSigTimeoutTime_SGW" SG_ 257 VehicleSpeedVSOSig_B2 0;
BA_ "GenSigTimeoutTime_TRSKM" SG_ 257 VehicleSpeedVSOSig_B2 0;
BA_ "GenSigTimeoutTime_BCM" SG_ 524 AEB_Type_Brk_B2 0;
BA_ "GenSigTimeoutTime_BSM2" SG_ 524 AEB_Type_Brk_B2 0;
BA_ "GenSigTimeoutTime_CVADAS" SG_ 524 AEB_Type_Brk_B2 0;
BA_ "GenSigTimeoutTime_EPS" SG_ 524 AEB_Type_Brk_B2 0;
BA_ "GenSigTimeoutTime_ORC" SG_ 524 AEB_Type_Brk_B2 0;
BA_ "GenSigTimeoutTime_PAM" SG_ 524 AEB_Type_Brk_B2 0;
BA_ "GenSigTimeoutTime_SGW" SG_ 524 AEB_Type_Brk_B2 0;
BA_ "GenSigTimeoutTime_TRSKM" SG_ 524 AEB_Type_Brk_B2 0;
BA_ "GenSigTimeoutTime_BSM2" SG_ 524 Brake_OpStat_Sec 0;
BA_ "GenSigTimeoutTime_CVADAS" SG_ 524 Brake_OpStat_Sec 0;
BA_ "GenSigTimeoutTime_EPS" SG_ 524 Brake_OpStat_Sec 0;
BA_ "GenSigTimeoutTime_PAM" SG_ 524 Brake_OpStat_Sec 0;
BA_ "GenSigTimeoutTime_SGW" SG_ 524 Brake_OpStat_Sec 0;
BA_ "GenSigTimeoutTime_TRSKM" SG_ 524 Brake_OpStat_Sec 0;
BA_ "GenSigStartValue" SG_ 524 BrkTrq_B2 32767;
BA_ "GenSigTimeoutTime_BCM" SG_ 524 BrkTrq_B2 0;
BA_ "GenSigTimeoutTime_BSM2" SG_ 524 BrkTrq_B2 0;
BA_ "GenSigTimeoutTime_CVADAS" SG_ 524 BrkTrq_B2 0;
BA_ "GenSigTimeoutTime_EPS" SG_ 524 BrkTrq_B2 0;
BA_ "GenSigTimeoutTime_ORC" SG_ 524 BrkTrq_B2 0;
BA_ "GenSigTimeoutTime_PAM" SG_ 524 BrkTrq_B2 0;
BA_ "GenSigTimeoutTime_SGW" SG_ 524 BrkTrq_B2 0;
BA_ "GenSigTimeoutTime_TRSKM" SG_ 524 BrkTrq_B2 0;
BA_ "GenSigTimeoutTime_BCM" SG_ 524 BSM2_Long_DTO 0;
BA_ "GenSigTimeoutTime_BSM2" SG_ 524 BSM2_Long_DTO 0;
BA_ "GenSigTimeoutTime_CVADAS" SG_ 524 BSM2_Long_DTO 0;
BA_ "GenSigTimeoutTime_EPS" SG_ 524 BSM2_Long_DTO 0;
BA_ "GenSigTimeoutTime_ORC" SG_ 524 BSM2_Long_DTO 0;
BA_ "GenSigTimeoutTime_PAM" SG_ 524 BSM2_Long_DTO 0;
BA_ "GenSigTimeoutTime_SGW" SG_ 524 BSM2_Long_DTO 0;
BA_ "GenSigTimeoutTime_TRSKM" SG_ 524 BSM2_Long_DTO 0;
BA_ "GenSigTimeoutTime_BSM2" SG_ 524 BSM2_OpStat 0;
BA_ "GenSigTimeoutTime_CVADAS" SG_ 524 BSM2_OpStat 0;
BA_ "GenSigTimeoutTime_EPS" SG_ 524 BSM2_OpStat 0;
BA_ "GenSigTimeoutTime_ORC" SG_ 524 BSM2_OpStat 0;
BA_ "GenSigTimeoutTime_PAM" SG_ 524 BSM2_OpStat 0;
BA_ "GenSigTimeoutTime_SGW" SG_ 524 BSM2_OpStat 0;
BA_ "GenSigTimeoutTime_TRSKM" SG_ 524 BSM2_OpStat 0;
BA_ "GenSigTimeoutTime_BSM2" SG_ 524 CRC_BRAKE2_2 0;
BA_ "GenSigTimeoutTime_CVADAS" SG_ 524 CRC_BRAKE2_2 0;
BA_ "GenSigTimeoutTime_EPS" SG_ 524 CRC_BRAKE2_2 0;
BA_ "GenSigTimeoutTime_PAM" SG_ 524 CRC_BRAKE2_2 0;
BA_ "GenSigTimeoutTime_SGW" SG_ 524 CRC_BRAKE2_2 0;
BA_ "GenSigTimeoutTime_TRSKM" SG_ 524 CRC_BRAKE2_2 0;
BA_ "GenSigTimeoutTime_BSM2" SG_ 524 MessageCounter_BRAKE2_2 0;
BA_ "GenSigTimeoutTime_CVADAS" SG_ 524 MessageCounter_BRAKE2_2 0;
BA_ "GenSigTimeoutTime_EPS" SG_ 524 MessageCounter_BRAKE2_2 0;
BA_ "GenSigTimeoutTime_PAM" SG_ 524 MessageCounter_BRAKE2_2 0;
BA_ "GenSigTimeoutTime_SGW" SG_ 524 MessageCounter_BRAKE2_2 0;
BA_ "GenSigTimeoutTime_TRSKM" SG_ 524 MessageCounter_BRAKE2_2 0;
BA_ "GenSigStartValue" SG_ 524 VehicleStandStillSts_B2 1;
BA_ "GenSigTimeoutTime_BSM2" SG_ 524 VehicleStandStillSts_B2 0;
BA_ "GenSigTimeoutTime_CVADAS" SG_ 524 VehicleStandStillSts_B2 0;
BA_ "GenSigTimeoutTime_EPS" SG_ 524 VehicleStandStillSts_B2 0;
BA_ "GenSigTimeoutTime_ORC" SG_ 524 VehicleStandStillSts_B2 0;
BA_ "GenSigTimeoutTime_PAM" SG_ 524 VehicleStandStillSts_B2 0;
BA_ "GenSigTimeoutTime_SGW" SG_ 524 VehicleStandStillSts_B2 0;
BA_ "GenSigTimeoutTime_TRSKM" SG_ 524 VehicleStandStillSts_B2 0;
BA_ "GenSigSendType" SG_ 1156 ABSFailSts_B2 4;
BA_ "GenSigTimeoutTime_BCM" SG_ 1156 ABSFailSts_B2 0;
BA_ "GenSigTimeoutTime_BSM2" SG_ 1156 ABSFailSts_B2 0;
BA_ "GenSigTimeoutTime_CVADAS" SG_ 1156 ABSFailSts_B2 0;
BA_ "GenSigTimeoutTime_EPS" SG_ 1156 ABSFailSts_B2 0;
BA_ "GenSigTimeoutTime_ORC" SG_ 1156 ABSFailSts_B2 0;
BA_ "GenSigTimeoutTime_PAM" SG_ 1156 ABSFailSts_B2 0;
BA_ "GenSigTimeoutTime_SGW" SG_ 1156 ABSFailSts_B2 0;
BA_ "GenSigTimeoutTime_TRSKM" SG_ 1156 ABSFailSts_B2 0;
BA_ "GenSigTimeoutTime_BCM" SG_ 1156 CRC_BRAKE2_3 0;
BA_ "GenSigTimeoutTime_BSM2" SG_ 1156 CRC_BRAKE2_3 0;
BA_ "GenSigTimeoutTime_CVADAS" SG_ 1156 CRC_BRAKE2_3 0;
BA_ "GenSigTimeoutTime_EPS" SG_ 1156 CRC_BRAKE2_3 0;
BA_ "GenSigTimeoutTime_PAM" SG_ 1156 CRC_BRAKE2_3 0;
BA_ "GenSigTimeoutTime_SGW" SG_ 1156 CRC_BRAKE2_3 0;
BA_ "GenSigTimeoutTime_TRSKM" SG_ 1156 CRC_BRAKE2_3 0;
BA_ "GenSigTimeoutTime_BCM" SG_ 1156 MessageCounter_BRAKE2_3 0;
BA_ "GenSigTimeoutTime_BSM2" SG_ 1156 MessageCounter_BRAKE2_3 0;
BA_ "GenSigTimeoutTime_CVADAS" SG_ 1156 MessageCounter_BRAKE2_3 0;
BA_ "GenSigTimeoutTime_EPS" SG_ 1156 MessageCounter_BRAKE2_3 0;
BA_ "GenSigTimeoutTime_PAM" SG_ 1156 MessageCounter_BRAKE2_3 0;
BA_ "GenSigTimeoutTime_SGW" SG_ 1156 MessageCounter_BRAKE2_3 0;
BA_ "GenSigTimeoutTime_TRSKM" SG_ 1156 MessageCounter_BRAKE2_3 0;
BA_ "GenSigSendType" SG_ 1156 RollsModeAct_B2 4;
BA_ "GenSigTimeoutTime_BCM" SG_ 1156 RollsModeAct_B2 0;
BA_ "GenSigTimeoutTime_BSM2" SG_ 1156 RollsModeAct_B2 0;
BA_ "GenSigTimeoutTime_CVADAS" SG_ 1156 RollsModeAct_B2 0;
BA_ "GenSigTimeoutTime_EPS" SG_ 1156 RollsModeAct_B2 0;
BA_ "GenSigTimeoutTime_ORC" SG_ 1156 RollsModeAct_B2 0;
BA_ "GenSigTimeoutTime_PAM" SG_ 1156 RollsModeAct_B2 0;
BA_ "GenSigTimeoutTime_SGW" SG_ 1156 RollsModeAct_B2 0;
BA_ "GenSigTimeoutTime_TRSKM" SG_ 1156 RollsModeAct_B2 0;
BA_ "GenSigTimeoutTime_BCM" SG_ 2651930624 Digit_01 0;
BA_ "GenSigTimeoutTime_SGW" SG_ 2651930624 Digit_01 0;
BA_ "GenSigTimeoutTime_BCM" SG_ 2651930624 Digit_02 0;
BA_ "GenSigTimeoutTime_SGW" SG_ 2651930624 Digit_02 0;
BA_ "GenSigTimeoutTime_BCM" SG_ 2651930624 Digit_03 0;
BA_ "GenSigTimeoutTime_SGW" SG_ 2651930624 Digit_03 0;
BA_ "GenSigTimeoutTime_BCM" SG_ 2651930624 Digit_04 0;
BA_ "GenSigTimeoutTime_SGW" SG_ 2651930624 Digit_04 0;
BA_ "GenSigTimeoutTime_BCM" SG_ 2651930624 Digit_05 0;
BA_ "GenSigTimeoutTime_SGW" SG_ 2651930624 Digit_05 0;
BA_ "GenSigTimeoutTime_BCM" SG_ 2651930624 Digit_06 0;
BA_ "GenSigTimeoutTime_SGW" SG_ 2651930624 Digit_06 0;
BA_ "GenSigTimeoutTime_BCM" SG_ 2651930624 Digit_07 0;
BA_ "GenSigTimeoutTime_SGW" SG_ 2651930624 Digit_07 0;
BA_ "GenSigTimeoutTime_BCM" SG_ 2651930624 Digit_08 0;
BA_ "GenSigTimeoutTime_SGW" SG_ 2651930624 Digit_08 0;
BA_ "GenSigTimeoutTime_BCM" SG_ 2651930624 Digit_09 0;
BA_ "GenSigTimeoutTime_SGW" SG_ 2651930624 Digit_09 0;
BA_ "GenSigTimeoutTime_BCM" SG_ 2651930624 Digit_10 0;
BA_ "GenSigTimeoutTime_SGW" SG_ 2651930624 Digit_10 0;
BA_ "GenSigTimeoutTime_BCM" SG_ 2651930624 Digit_11 0;
BA_ "GenSigTimeoutTime_SGW" SG_ 2651930624 Digit_11 0;
BA_ "GenSigSendType" SG_ 2651930772 Digit_01_BSM2 1;
BA_ "GenSigTimeoutTime_BSM2" SG_ 2651930772 Digit_01_BSM2 0;
BA_ "GenSigTimeoutTime_CADM2" SG_ 2651930772 Digit_01_BSM2 0;
BA_ "GenSigTimeoutTime_CVADAS" SG_ 2651930772 Digit_01_BSM2 0;
BA_ "GenSigTimeoutTime_EPS" SG_ 2651930772 Digit_01_BSM2 0;
BA_ "GenSigTimeoutTime_ORC" SG_ 2651930772 Digit_01_BSM2 0;
BA_ "GenSigTimeoutTime_PAM" SG_ 2651930772 Digit_01_BSM2 0;
BA_ "GenSigTimeoutTime_SGW" SG_ 2651930772 Digit_01_BSM2 0;
BA_ "GenSigTimeoutTime_TRSKM" SG_ 2651930772 Digit_01_BSM2 0;
BA_ "GenSigTimeoutTime_BSM2" SG_ 2651930772 Digit_02_BSM2 0;
BA_ "GenSigTimeoutTime_CADM2" SG_ 2651930772 Digit_02_BSM2 0;
BA_ "GenSigTimeoutTime_CVADAS" SG_ 2651930772 Digit_02_BSM2 0;
BA_ "GenSigTimeoutTime_EPS" SG_ 2651930772 Digit_02_BSM2 0;
BA_ "GenSigTimeoutTime_ORC" SG_ 2651930772 Digit_02_BSM2 0;
BA_ "GenSigTimeoutTime_PAM" SG_ 2651930772 Digit_02_BSM2 0;
BA_ "GenSigTimeoutTime_SGW" SG_ 2651930772 Digit_02_BSM2 0;
BA_ "GenSigTimeoutTime_TRSKM" SG_ 2651930772 Digit_02_BSM2 0;
BA_ "GenSigTimeoutTime_BSM2" SG_ 2651930772 Digit_03_BSM2 0;
BA_ "GenSigTimeoutTime_CADM2" SG_ 2651930772 Digit_03_BSM2 0;
BA_ "GenSigTimeoutTime_CVADAS" SG_ 2651930772 Digit_03_BSM2 0;
BA_ "GenSigTimeoutTime_EPS" SG_ 2651930772 Digit_03_BSM2 0;
BA_ "GenSigTimeoutTime_ORC" SG_ 2651930772 Digit_03_BSM2 0;
BA_ "GenSigTimeoutTime_PAM" SG_ 2651930772 Digit_03_BSM2 0;
BA_ "GenSigTimeoutTime_SGW" SG_ 2651930772 Digit_03_BSM2 0;
BA_ "GenSigTimeoutTime_TRSKM" SG_ 2651930772 Digit_03_BSM2 0;
BA_ "GenSigTimeoutTime_BSM2" SG_ 2651930772 Digit_04_BSM2 0;
BA_ "GenSigTimeoutTime_CADM2" SG_ 2651930772 Digit_04_BSM2 0;
BA_ "GenSigTimeoutTime_CVADAS" SG_ 2651930772 Digit_04_BSM2 0;
BA_ "GenSigTimeoutTime_EPS" SG_ 2651930772 Digit_04_BSM2 0;
BA_ "GenSigTimeoutTime_ORC" SG_ 2651930772 Digit_04_BSM2 0;
BA_ "GenSigTimeoutTime_PAM" SG_ 2651930772 Digit_04_BSM2 0;
BA_ "GenSigTimeoutTime_SGW" SG_ 2651930772 Digit_04_BSM2 0;
BA_ "GenSigTimeoutTime_TRSKM" SG_ 2651930772 Digit_04_BSM2 0;
BA_ "GenSigTimeoutTime_BSM2" SG_ 2651930772 Digit_05_BSM2 0;
BA_ "GenSigTimeoutTime_CADM2" SG_ 2651930772 Digit_05_BSM2 0;
BA_ "GenSigTimeoutTime_CVADAS" SG_ 2651930772 Digit_05_BSM2 0;
BA_ "GenSigTimeoutTime_EPS" SG_ 2651930772 Digit_05_BSM2 0;
BA_ "GenSigTimeoutTime_ORC" SG_ 2651930772 Digit_05_BSM2 0;
BA_ "GenSigTimeoutTime_PAM" SG_ 2651930772 Digit_05_BSM2 0;
BA_ "GenSigTimeoutTime_SGW" SG_ 2651930772 Digit_05_BSM2 0;
BA_ "GenSigTimeoutTime_TRSKM" SG_ 2651930772 Digit_05_BSM2 0;
BA_ "GenSigTimeoutTime_BSM2" SG_ 2651930772 Digit_06_BSM2 0;
BA_ "GenSigTimeoutTime_CADM2" SG_ 2651930772 Digit_06_BSM2 0;
BA_ "GenSigTimeoutTime_CVADAS" SG_ 2651930772 Digit_06_BSM2 0;
BA_ "GenSigTimeoutTime_EPS" SG_ 2651930772 Digit_06_BSM2 0;
BA_ "GenSigTimeoutTime_ORC" SG_ 2651930772 Digit_06_BSM2 0;
BA_ "GenSigTimeoutTime_PAM" SG_ 2651930772 Digit_06_BSM2 0;
BA_ "GenSigTimeoutTime_SGW" SG_ 2651930772 Digit_06_BSM2 0;
BA_ "GenSigTimeoutTime_TRSKM" SG_ 2651930772 Digit_06_BSM2 0;
BA_ "GenSigTimeoutTime_BSM2" SG_ 2651930772 Digit_07_BSM2 0;
BA_ "GenSigTimeoutTime_CADM2" SG_ 2651930772 Digit_07_BSM2 0;
BA_ "GenSigTimeoutTime_CVADAS" SG_ 2651930772 Digit_07_BSM2 0;
BA_ "GenSigTimeoutTime_EPS" SG_ 2651930772 Digit_07_BSM2 0;
BA_ "GenSigTimeoutTime_ORC" SG_ 2651930772 Digit_07_BSM2 0;
BA_ "GenSigTimeoutTime_PAM" SG_ 2651930772 Digit_07_BSM2 0;
BA_ "GenSigTimeoutTime_SGW" SG_ 2651930772 Digit_07_BSM2 0;
BA_ "GenSigTimeoutTime_TRSKM" SG_ 2651930772 Digit_07_BSM2 0;
BA_ "GenSigTimeoutTime_BSM2" SG_ 2651930772 Digit_08_BSM2 0;
BA_ "GenSigTimeoutTime_CADM2" SG_ 2651930772 Digit_08_BSM2 0;
BA_ "GenSigTimeoutTime_CVADAS" SG_ 2651930772 Digit_08_BSM2 0;
BA_ "GenSigTimeoutTime_EPS" SG_ 2651930772 Digit_08_BSM2 0;
BA_ "GenSigTimeoutTime_ORC" SG_ 2651930772 Digit_08_BSM2 0;
BA_ "GenSigTimeoutTime_PAM" SG_ 2651930772 Digit_08_BSM2 0;
BA_ "GenSigTimeoutTime_SGW" SG_ 2651930772 Digit_08_BSM2 0;
BA_ "GenSigTimeoutTime_TRSKM" SG_ 2651930772 Digit_08_BSM2 0;
BA_ "GenSigTimeoutTime_BSM2" SG_ 2651930772 Digit_09_BSM2 0;
BA_ "GenSigTimeoutTime_CADM2" SG_ 2651930772 Digit_09_BSM2 0;
BA_ "GenSigTimeoutTime_CVADAS" SG_ 2651930772 Digit_09_BSM2 0;
BA_ "GenSigTimeoutTime_EPS" SG_ 2651930772 Digit_09_BSM2 0;
BA_ "GenSigTimeoutTime_ORC" SG_ 2651930772 Digit_09_BSM2 0;
BA_ "GenSigTimeoutTime_PAM" SG_ 2651930772 Digit_09_BSM2 0;
BA_ "GenSigTimeoutTime_SGW" SG_ 2651930772 Digit_09_BSM2 0;
BA_ "GenSigTimeoutTime_TRSKM" SG_ 2651930772 Digit_09_BSM2 0;
BA_ "GenSigTimeoutTime_BSM2" SG_ 2651930772 Digit_10_BSM2 0;
BA_ "GenSigTimeoutTime_CADM2" SG_ 2651930772 Digit_10_BSM2 0;
BA_ "GenSigTimeoutTime_CVADAS" SG_ 2651930772 Digit_10_BSM2 0;
BA_ "GenSigTimeoutTime_EPS" SG_ 2651930772 Digit_10_BSM2 0;
BA_ "GenSigTimeoutTime_ORC" SG_ 2651930772 Digit_10_BSM2 0;
BA_ "GenSigTimeoutTime_PAM" SG_ 2651930772 Digit_10_BSM2 0;
BA_ "GenSigTimeoutTime_SGW" SG_ 2651930772 Digit_10_BSM2 0;
BA_ "GenSigTimeoutTime_TRSKM" SG_ 2651930772 Digit_10_BSM2 0;
BA_ "GenSigTimeoutTime_BSM2" SG_ 2651930772 Digit_11_BSM2 0;
BA_ "GenSigTimeoutTime_CADM2" SG_ 2651930772 Digit_11_BSM2 0;
BA_ "GenSigTimeoutTime_CVADAS" SG_ 2651930772 Digit_11_BSM2 0;
BA_ "GenSigTimeoutTime_EPS" SG_ 2651930772 Digit_11_BSM2 0;
BA_ "GenSigTimeoutTime_ORC" SG_ 2651930772 Digit_11_BSM2 0;
BA_ "GenSigTimeoutTime_PAM" SG_ 2651930772 Digit_11_BSM2 0;
BA_ "GenSigTimeoutTime_SGW" SG_ 2651930772 Digit_11_BSM2 0;
BA_ "GenSigTimeoutTime_TRSKM" SG_ 2651930772 Digit_11_BSM2 0;
BA_ "GenSigSendType" SG_ 2651930766 Digit_01_CADM2 1;
BA_ "GenSigTimeoutTime_BSM2" SG_ 2651930766 Digit_01_CADM2 0;
BA_ "GenSigTimeoutTime_CADM2" SG_ 2651930766 Digit_01_CADM2 0;
BA_ "GenSigTimeoutTime_CVADAS" SG_ 2651930766 Digit_01_CADM2 0;
BA_ "GenSigTimeoutTime_EPS" SG_ 2651930766 Digit_01_CADM2 0;
BA_ "GenSigTimeoutTime_ORC" SG_ 2651930766 Digit_01_CADM2 0;
BA_ "GenSigTimeoutTime_PAM" SG_ 2651930766 Digit_01_CADM2 0;
BA_ "GenSigTimeoutTime_SGW" SG_ 2651930766 Digit_01_CADM2 0;
BA_ "GenSigTimeoutTime_TRSKM" SG_ 2651930766 Digit_01_CADM2 0;
BA_ "GenSigTimeoutTime_BSM2" SG_ 2651930766 Digit_02_CADM2 0;
BA_ "GenSigTimeoutTime_CADM2" SG_ 2651930766 Digit_02_CADM2 0;
BA_ "GenSigTimeoutTime_CVADAS" SG_ 2651930766 Digit_02_CADM2 0;
BA_ "GenSigTimeoutTime_EPS" SG_ 2651930766 Digit_02_CADM2 0;
BA_ "GenSigTimeoutTime_ORC" SG_ 2651930766 Digit_02_CADM2 0;
BA_ "GenSigTimeoutTime_PAM" SG_ 2651930766 Digit_02_CADM2 0;
BA_ "GenSigTimeoutTime_SGW" SG_ 2651930766 Digit_02_CADM2 0;
BA_ "GenSigTimeoutTime_TRSKM" SG_ 2651930766 Digit_02_CADM2 0;
BA_ "GenSigTimeoutTime_BSM2" SG_ 2651930766 Digit_03_CADM2 0;
BA_ "GenSigTimeoutTime_CADM2" SG_ 2651930766 Digit_03_CADM2 0;
BA_ "GenSigTimeoutTime_CVADAS" SG_ 2651930766 Digit_03_CADM2 0;
BA_ "GenSigTimeoutTime_EPS" SG_ 2651930766 Digit_03_CADM2 0;
BA_ "GenSigTimeoutTime_ORC" SG_ 2651930766 Digit_03_CADM2 0;
BA_ "GenSigTimeoutTime_PAM" SG_ 2651930766 Digit_03_CADM2 0;
BA_ "GenSigTimeoutTime_SGW" SG_ 2651930766 Digit_03_CADM2 0;
BA_ "GenSigTimeoutTime_TRSKM" SG_ 2651930766 Digit_03_CADM2 0;
BA_ "GenSigTimeoutTime_BSM2" SG_ 2651930766 Digit_04_CADM2 0;
BA_ "GenSigTimeoutTime_CADM2" SG_ 2651930766 Digit_04_CADM2 0;
BA_ "GenSigTimeoutTime_CVADAS" SG_ 2651930766 Digit_04_CADM2 0;
BA_ "GenSigTimeoutTime_EPS" SG_ 2651930766 Digit_04_CADM2 0;
BA_ "GenSigTimeoutTime_ORC" SG_ 2651930766 Digit_04_CADM2 0;
BA_ "GenSigTimeoutTime_PAM" SG_ 2651930766 Digit_04_CADM2 0;
BA_ "GenSigTimeoutTime_SGW" SG_ 2651930766 Digit_04_CADM2 0;
BA_ "GenSigTimeoutTime_TRSKM" SG_ 2651930766 Digit_04_CADM2 0;
BA_ "GenSigTimeoutTime_BSM2" SG_ 2651930766 Digit_05_CADM2 0;
BA_ "GenSigTimeoutTime_CADM2" SG_ 2651930766 Digit_05_CADM2 0;
BA_ "GenSigTimeoutTime_CVADAS" SG_ 2651930766 Digit_05_CADM2 0;
BA_ "GenSigTimeoutTime_EPS" SG_ 2651930766 Digit_05_CADM2 0;
BA_ "GenSigTimeoutTime_ORC" SG_ 2651930766 Digit_05_CADM2 0;
BA_ "GenSigTimeoutTime_PAM" SG_ 2651930766 Digit_05_CADM2 0;
BA_ "GenSigTimeoutTime_SGW" SG_ 2651930766 Digit_05_CADM2 0;
BA_ "GenSigTimeoutTime_TRSKM" SG_ 2651930766 Digit_05_CADM2 0;
BA_ "GenSigTimeoutTime_BSM2" SG_ 2651930766 Digit_06_CADM2 0;
BA_ "GenSigTimeoutTime_CADM2" SG_ 2651930766 Digit_06_CADM2 0;
BA_ "GenSigTimeoutTime_CVADAS" SG_ 2651930766 Digit_06_CADM2 0;
BA_ "GenSigTimeoutTime_EPS" SG_ 2651930766 Digit_06_CADM2 0;
BA_ "GenSigTimeoutTime_ORC" SG_ 2651930766 Digit_06_CADM2 0;
BA_ "GenSigTimeoutTime_PAM" SG_ 2651930766 Digit_06_CADM2 0;
BA_ "GenSigTimeoutTime_SGW" SG_ 2651930766 Digit_06_CADM2 0;
BA_ "GenSigTimeoutTime_TRSKM" SG_ 2651930766 Digit_06_CADM2 0;
BA_ "GenSigTimeoutTime_BSM2" SG_ 2651930766 Digit_07_CADM2 0;
BA_ "GenSigTimeoutTime_CADM2" SG_ 2651930766 Digit_07_CADM2 0;
BA_ "GenSigTimeoutTime_CVADAS" SG_ 2651930766 Digit_07_CADM2 0;
BA_ "GenSigTimeoutTime_EPS" SG_ 2651930766 Digit_07_CADM2 0;
BA_ "GenSigTimeoutTime_ORC" SG_ 2651930766 Digit_07_CADM2 0;
BA_ "GenSigTimeoutTime_PAM" SG_ 2651930766 Digit_07_CADM2 0;
BA_ "GenSigTimeoutTime_SGW" SG_ 2651930766 Digit_07_CADM2 0;
BA_ "GenSigTimeoutTime_TRSKM" SG_ 2651930766 Digit_07_CADM2 0;
BA_ "GenSigTimeoutTime_BSM2" SG_ 2651930766 Digit_08_CADM2 0;
BA_ "GenSigTimeoutTime_CADM2" SG_ 2651930766 Digit_08_CADM2 0;
BA_ "GenSigTimeoutTime_CVADAS" SG_ 2651930766 Digit_08_CADM2 0;
BA_ "GenSigTimeoutTime_EPS" SG_ 2651930766 Digit_08_CADM2 0;
BA_ "GenSigTimeoutTime_ORC" SG_ 2651930766 Digit_08_CADM2 0;
BA_ "GenSigTimeoutTime_PAM" SG_ 2651930766 Digit_08_CADM2 0;
BA_ "GenSigTimeoutTime_SGW" SG_ 2651930766 Digit_08_CADM2 0;
BA_ "GenSigTimeoutTime_TRSKM" SG_ 2651930766 Digit_08_CADM2 0;
BA_ "GenSigTimeoutTime_BSM2" SG_ 2651930766 Digit_09_CADM2 0;
BA_ "GenSigTimeoutTime_CADM2" SG_ 2651930766 Digit_09_CADM2 0;
BA_ "GenSigTimeoutTime_CVADAS" SG_ 2651930766 Digit_09_CADM2 0;
BA_ "GenSigTimeoutTime_EPS" SG_ 2651930766 Digit_09_CADM2 0;
BA_ "GenSigTimeoutTime_ORC" SG_ 2651930766 Digit_09_CADM2 0;
BA_ "GenSigTimeoutTime_PAM" SG_ 2651930766 Digit_09_CADM2 0;
BA_ "GenSigTimeoutTime_SGW" SG_ 2651930766 Digit_09_CADM2 0;
BA_ "GenSigTimeoutTime_TRSKM" SG_ 2651930766 Digit_09_CADM2 0;
BA_ "GenSigTimeoutTime_BSM2" SG_ 2651930766 Digit_10_CADM2 0;
BA_ "GenSigTimeoutTime_CADM2" SG_ 2651930766 Digit_10_CADM2 0;
BA_ "GenSigTimeoutTime_CVADAS" SG_ 2651930766 Digit_10_CADM2 0;
BA_ "GenSigTimeoutTime_EPS" SG_ 2651930766 Digit_10_CADM2 0;
BA_ "GenSigTimeoutTime_ORC" SG_ 2651930766 Digit_10_CADM2 0;
BA_ "GenSigTimeoutTime_PAM" SG_ 2651930766 Digit_10_CADM2 0;
BA_ "GenSigTimeoutTime_SGW" SG_ 2651930766 Digit_10_CADM2 0;
BA_ "GenSigTimeoutTime_TRSKM" SG_ 2651930766 Digit_10_CADM2 0;
BA_ "GenSigTimeoutTime_BSM2" SG_ 2651930766 Digit_11_CADM2 0;
BA_ "GenSigTimeoutTime_CADM2" SG_ 2651930766 Digit_11_CADM2 0;
BA_ "GenSigTimeoutTime_CVADAS" SG_ 2651930766 Digit_11_CADM2 0;
BA_ "GenSigTimeoutTime_EPS" SG_ 2651930766 Digit_11_CADM2 0;
BA_ "GenSigTimeoutTime_ORC" SG_ 2651930766 Digit_11_CADM2 0;
BA_ "GenSigTimeoutTime_PAM" SG_ 2651930766 Digit_11_CADM2 0;
BA_ "GenSigTimeoutTime_SGW" SG_ 2651930766 Digit_11_CADM2 0;
BA_ "GenSigTimeoutTime_TRSKM" SG_ 2651930766 Digit_11_CADM2 0;
BA_ "GenSigSendType" SG_ 2651930626 Digit_01_EPS 1;
BA_ "GenSigTimeoutTime_BSM2" SG_ 2651930626 Digit_01_EPS 0;
BA_ "GenSigTimeoutTime_CADM2" SG_ 2651930626 Digit_01_EPS 0;
BA_ "GenSigTimeoutTime_CVADAS" SG_ 2651930626 Digit_01_EPS 0;
BA_ "GenSigTimeoutTime_EPS" SG_ 2651930626 Digit_01_EPS 0;
BA_ "GenSigTimeoutTime_ORC" SG_ 2651930626 Digit_01_EPS 0;
BA_ "GenSigTimeoutTime_PAM" SG_ 2651930626 Digit_01_EPS 0;
BA_ "GenSigTimeoutTime_SGW" SG_ 2651930626 Digit_01_EPS 0;
BA_ "GenSigTimeoutTime_TRSKM" SG_ 2651930626 Digit_01_EPS 0;
BA_ "GenSigTimeoutTime_BSM2" SG_ 2651930626 Digit_02_EPS 0;
BA_ "GenSigTimeoutTime_CADM2" SG_ 2651930626 Digit_02_EPS 0;
BA_ "GenSigTimeoutTime_CVADAS" SG_ 2651930626 Digit_02_EPS 0;
BA_ "GenSigTimeoutTime_EPS" SG_ 2651930626 Digit_02_EPS 0;
BA_ "GenSigTimeoutTime_ORC" SG_ 2651930626 Digit_02_EPS 0;
BA_ "GenSigTimeoutTime_PAM" SG_ 2651930626 Digit_02_EPS 0;
BA_ "GenSigTimeoutTime_SGW" SG_ 2651930626 Digit_02_EPS 0;
BA_ "GenSigTimeoutTime_TRSKM" SG_ 2651930626 Digit_02_EPS 0;
BA_ "GenSigTimeoutTime_BSM2" SG_ 2651930626 Digit_03_EPS 0;
BA_ "GenSigTimeoutTime_CADM2" SG_ 2651930626 Digit_03_EPS 0;
BA_ "GenSigTimeoutTime_CVADAS" SG_ 2651930626 Digit_03_EPS 0;
BA_ "GenSigTimeoutTime_EPS" SG_ 2651930626 Digit_03_EPS 0;
BA_ "GenSigTimeoutTime_ORC" SG_ 2651930626 Digit_03_EPS 0;
BA_ "GenSigTimeoutTime_PAM" SG_ 2651930626 Digit_03_EPS 0;
BA_ "GenSigTimeoutTime_SGW" SG_ 2651930626 Digit_03_EPS 0;
BA_ "GenSigTimeoutTime_TRSKM" SG_ 2651930626 Digit_03_EPS 0;
BA_ "GenSigTimeoutTime_BSM2" SG_ 2651930626 Digit_04_EPS 0;
BA_ "GenSigTimeoutTime_CADM2" SG_ 2651930626 Digit_04_EPS 0;
BA_ "GenSigTimeoutTime_CVADAS" SG_ 2651930626 Digit_04_EPS 0;
BA_ "GenSigTimeoutTime_EPS" SG_ 2651930626 Digit_04_EPS 0;
BA_ "GenSigTimeoutTime_ORC" SG_ 2651930626 Digit_04_EPS 0;
BA_ "GenSigTimeoutTime_PAM" SG_ 2651930626 Digit_04_EPS 0;
BA_ "GenSigTimeoutTime_SGW" SG_ 2651930626 Digit_04_EPS 0;
BA_ "GenSigTimeoutTime_TRSKM" SG_ 2651930626 Digit_04_EPS 0;
BA_ "GenSigTimeoutTime_BSM2" SG_ 2651930626 Digit_05_EPS 0;
BA_ "GenSigTimeoutTime_CADM2" SG_ 2651930626 Digit_05_EPS 0;
BA_ "GenSigTimeoutTime_CVADAS" SG_ 2651930626 Digit_05_EPS 0;
BA_ "GenSigTimeoutTime_EPS" SG_ 2651930626 Digit_05_EPS 0;
BA_ "GenSigTimeoutTime_ORC" SG_ 2651930626 Digit_05_EPS 0;
BA_ "GenSigTimeoutTime_PAM" SG_ 2651930626 Digit_05_EPS 0;
BA_ "GenSigTimeoutTime_SGW" SG_ 2651930626 Digit_05_EPS 0;
BA_ "GenSigTimeoutTime_TRSKM" SG_ 2651930626 Digit_05_EPS 0;
BA_ "GenSigTimeoutTime_BSM2" SG_ 2651930626 Digit_06_EPS 0;
BA_ "GenSigTimeoutTime_CADM2" SG_ 2651930626 Digit_06_EPS 0;
BA_ "GenSigTimeoutTime_CVADAS" SG_ 2651930626 Digit_06_EPS 0;
BA_ "GenSigTimeoutTime_EPS" SG_ 2651930626 Digit_06_EPS 0;
BA_ "GenSigTimeoutTime_ORC" SG_ 2651930626 Digit_06_EPS 0;
BA_ "GenSigTimeoutTime_PAM" SG_ 2651930626 Digit_06_EPS 0;
BA_ "GenSigTimeoutTime_SGW" SG_ 2651930626 Digit_06_EPS 0;
BA_ "GenSigTimeoutTime_TRSKM" SG_ 2651930626 Digit_06_EPS 0;
BA_ "GenSigTimeoutTime_BSM2" SG_ 2651930626 Digit_07_EPS 0;
BA_ "GenSigTimeoutTime_CADM2" SG_ 2651930626 Digit_07_EPS 0;
BA_ "GenSigTimeoutTime_CVADAS" SG_ 2651930626 Digit_07_EPS 0;
BA_ "GenSigTimeoutTime_EPS" SG_ 2651930626 Digit_07_EPS 0;
BA_ "GenSigTimeoutTime_ORC" SG_ 2651930626 Digit_07_EPS 0;
BA_ "GenSigTimeoutTime_PAM" SG_ 2651930626 Digit_07_EPS 0;
BA_ "GenSigTimeoutTime_SGW" SG_ 2651930626 Digit_07_EPS 0;
BA_ "GenSigTimeoutTime_TRSKM" SG_ 2651930626 Digit_07_EPS 0;
BA_ "GenSigTimeoutTime_BSM2" SG_ 2651930626 Digit_08_EPS 0;
BA_ "GenSigTimeoutTime_CADM2" SG_ 2651930626 Digit_08_EPS 0;
BA_ "GenSigTimeoutTime_CVADAS" SG_ 2651930626 Digit_08_EPS 0;
BA_ "GenSigTimeoutTime_EPS" SG_ 2651930626 Digit_08_EPS 0;
BA_ "GenSigTimeoutTime_ORC" SG_ 2651930626 Digit_08_EPS 0;
BA_ "GenSigTimeoutTime_PAM" SG_ 2651930626 Digit_08_EPS 0;
BA_ "GenSigTimeoutTime_SGW" SG_ 2651930626 Digit_08_EPS 0;
BA_ "GenSigTimeoutTime_TRSKM" SG_ 2651930626 Digit_08_EPS 0;
BA_ "GenSigTimeoutTime_BSM2" SG_ 2651930626 Digit_09_EPS 0;
BA_ "GenSigTimeoutTime_CADM2" SG_ 2651930626 Digit_09_EPS 0;
BA_ "GenSigTimeoutTime_CVADAS" SG_ 2651930626 Digit_09_EPS 0;
BA_ "GenSigTimeoutTime_EPS" SG_ 2651930626 Digit_09_EPS 0;
BA_ "GenSigTimeoutTime_ORC" SG_ 2651930626 Digit_09_EPS 0;
BA_ "GenSigTimeoutTime_PAM" SG_ 2651930626 Digit_09_EPS 0;
BA_ "GenSigTimeoutTime_SGW" SG_ 2651930626 Digit_09_EPS 0;
BA_ "GenSigTimeoutTime_TRSKM" SG_ 2651930626 Digit_09_EPS 0;
BA_ "GenSigTimeoutTime_BSM2" SG_ 2651930626 Digit_10_EPS 0;
BA_ "GenSigTimeoutTime_CADM2" SG_ 2651930626 Digit_10_EPS 0;
BA_ "GenSigTimeoutTime_CVADAS" SG_ 2651930626 Digit_10_EPS 0;
BA_ "GenSigTimeoutTime_EPS" SG_ 2651930626 Digit_10_EPS 0;
BA_ "GenSigTimeoutTime_ORC" SG_ 2651930626 Digit_10_EPS 0;
BA_ "GenSigTimeoutTime_PAM" SG_ 2651930626 Digit_10_EPS 0;
BA_ "GenSigTimeoutTime_SGW" SG_ 2651930626 Digit_10_EPS 0;
BA_ "GenSigTimeoutTime_TRSKM" SG_ 2651930626 Digit_10_EPS 0;
BA_ "GenSigTimeoutTime_BSM2" SG_ 2651930626 Digit_11_EPS 0;
BA_ "GenSigTimeoutTime_CADM2" SG_ 2651930626 Digit_11_EPS 0;
BA_ "GenSigTimeoutTime_CVADAS" SG_ 2651930626 Digit_11_EPS 0;
BA_ "GenSigTimeoutTime_EPS" SG_ 2651930626 Digit_11_EPS 0;
BA_ "GenSigTimeoutTime_ORC" SG_ 2651930626 Digit_11_EPS 0;
BA_ "GenSigTimeoutTime_PAM" SG_ 2651930626 Digit_11_EPS 0;
BA_ "GenSigTimeoutTime_SGW" SG_ 2651930626 Digit_11_EPS 0;
BA_ "GenSigTimeoutTime_TRSKM" SG_ 2651930626 Digit_11_EPS 0;
BA_ "GenSigSendType" SG_ 2651930650 Digit_01_ORC 1;
BA_ "GenSigTimeoutTime_BSM2" SG_ 2651930650 Digit_01_ORC 0;
BA_ "GenSigTimeoutTime_CADM2" SG_ 2651930650 Digit_01_ORC 0;
BA_ "GenSigTimeoutTime_CVADAS" SG_ 2651930650 Digit_01_ORC 0;
BA_ "GenSigTimeoutTime_EPS" SG_ 2651930650 Digit_01_ORC 0;
BA_ "GenSigTimeoutTime_ORC" SG_ 2651930650 Digit_01_ORC 0;
BA_ "GenSigTimeoutTime_PAM" SG_ 2651930650 Digit_01_ORC 0;
BA_ "GenSigTimeoutTime_SGW" SG_ 2651930650 Digit_01_ORC 0;
BA_ "GenSigTimeoutTime_TRSKM" SG_ 2651930650 Digit_01_ORC 0;
BA_ "GenSigTimeoutTime_BSM2" SG_ 2651930650 Digit_02_ORC 0;
BA_ "GenSigTimeoutTime_CADM2" SG_ 2651930650 Digit_02_ORC 0;
BA_ "GenSigTimeoutTime_CVADAS" SG_ 2651930650 Digit_02_ORC 0;
BA_ "GenSigTimeoutTime_EPS" SG_ 2651930650 Digit_02_ORC 0;
BA_ "GenSigTimeoutTime_ORC" SG_ 2651930650 Digit_02_ORC 0;
BA_ "GenSigTimeoutTime_PAM" SG_ 2651930650 Digit_02_ORC 0;
BA_ "GenSigTimeoutTime_SGW" SG_ 2651930650 Digit_02_ORC 0;
BA_ "GenSigTimeoutTime_TRSKM" SG_ 2651930650 Digit_02_ORC 0;
BA_ "GenSigTimeoutTime_BSM2" SG_ 2651930650 Digit_03_ORC 0;
BA_ "GenSigTimeoutTime_CADM2" SG_ 2651930650 Digit_03_ORC 0;
BA_ "GenSigTimeoutTime_CVADAS" SG_ 2651930650 Digit_03_ORC 0;
BA_ "GenSigTimeoutTime_EPS" SG_ 2651930650 Digit_03_ORC 0;
BA_ "GenSigTimeoutTime_ORC" SG_ 2651930650 Digit_03_ORC 0;
BA_ "GenSigTimeoutTime_PAM" SG_ 2651930650 Digit_03_ORC 0;
BA_ "GenSigTimeoutTime_SGW" SG_ 2651930650 Digit_03_ORC 0;
BA_ "GenSigTimeoutTime_TRSKM" SG_ 2651930650 Digit_03_ORC 0;
BA_ "GenSigTimeoutTime_BSM2" SG_ 2651930650 Digit_04_ORC 0;
BA_ "GenSigTimeoutTime_CADM2" SG_ 2651930650 Digit_04_ORC 0;
BA_ "GenSigTimeoutTime_CVADAS" SG_ 2651930650 Digit_04_ORC 0;
BA_ "GenSigTimeoutTime_EPS" SG_ 2651930650 Digit_04_ORC 0;
BA_ "GenSigTimeoutTime_ORC" SG_ 2651930650 Digit_04_ORC 0;
BA_ "GenSigTimeoutTime_PAM" SG_ 2651930650 Digit_04_ORC 0;
BA_ "GenSigTimeoutTime_SGW" SG_ 2651930650 Digit_04_ORC 0;
BA_ "GenSigTimeoutTime_TRSKM" SG_ 2651930650 Digit_04_ORC 0;
BA_ "GenSigTimeoutTime_BSM2" SG_ 2651930650 Digit_05_ORC 0;
BA_ "GenSigTimeoutTime_CADM2" SG_ 2651930650 Digit_05_ORC 0;
BA_ "GenSigTimeoutTime_CVADAS" SG_ 2651930650 Digit_05_ORC 0;
BA_ "GenSigTimeoutTime_EPS" SG_ 2651930650 Digit_05_ORC 0;
BA_ "GenSigTimeoutTime_ORC" SG_ 2651930650 Digit_05_ORC 0;
BA_ "GenSigTimeoutTime_PAM" SG_ 2651930650 Digit_05_ORC 0;
BA_ "GenSigTimeoutTime_SGW" SG_ 2651930650 Digit_05_ORC 0;
BA_ "GenSigTimeoutTime_TRSKM" SG_ 2651930650 Digit_05_ORC 0;
BA_ "GenSigTimeoutTime_BSM2" SG_ 2651930650 Digit_06_ORC 0;
BA_ "GenSigTimeoutTime_CADM2" SG_ 2651930650 Digit_06_ORC 0;
BA_ "GenSigTimeoutTime_CVADAS" SG_ 2651930650 Digit_06_ORC 0;
BA_ "GenSigTimeoutTime_EPS" SG_ 2651930650 Digit_06_ORC 0;
BA_ "GenSigTimeoutTime_ORC" SG_ 2651930650 Digit_06_ORC 0;
BA_ "GenSigTimeoutTime_PAM" SG_ 2651930650 Digit_06_ORC 0;
BA_ "GenSigTimeoutTime_SGW" SG_ 2651930650 Digit_06_ORC 0;
BA_ "GenSigTimeoutTime_TRSKM" SG_ 2651930650 Digit_06_ORC 0;
BA_ "GenSigTimeoutTime_BSM2" SG_ 2651930650 Digit_07_ORC 0;
BA_ "GenSigTimeoutTime_CADM2" SG_ 2651930650 Digit_07_ORC 0;
BA_ "GenSigTimeoutTime_CVADAS" SG_ 2651930650 Digit_07_ORC 0;
BA_ "GenSigTimeoutTime_EPS" SG_ 2651930650 Digit_07_ORC 0;
BA_ "GenSigTimeoutTime_ORC" SG_ 2651930650 Digit_07_ORC 0;
BA_ "GenSigTimeoutTime_PAM" SG_ 2651930650 Digit_07_ORC 0;
BA_ "GenSigTimeoutTime_SGW" SG_ 2651930650 Digit_07_ORC 0;
BA_ "GenSigTimeoutTime_TRSKM" SG_ 2651930650 Digit_07_ORC 0;
BA_ "GenSigTimeoutTime_BSM2" SG_ 2651930650 Digit_08_ORC 0;
BA_ "GenSigTimeoutTime_CADM2" SG_ 2651930650 Digit_08_ORC 0;
BA_ "GenSigTimeoutTime_CVADAS" SG_ 2651930650 Digit_08_ORC 0;
BA_ "GenSigTimeoutTime_EPS" SG_ 2651930650 Digit_08_ORC 0;
BA_ "GenSigTimeoutTime_ORC" SG_ 2651930650 Digit_08_ORC 0;
BA_ "GenSigTimeoutTime_PAM" SG_ 2651930650 Digit_08_ORC 0;
BA_ "GenSigTimeoutTime_SGW" SG_ 2651930650 Digit_08_ORC 0;
BA_ "GenSigTimeoutTime_TRSKM" SG_ 2651930650 Digit_08_ORC 0;
BA_ "GenSigTimeoutTime_BSM2" SG_ 2651930650 Digit_09_ORC 0;
BA_ "GenSigTimeoutTime_CADM2" SG_ 2651930650 Digit_09_ORC 0;
BA_ "GenSigTimeoutTime_CVADAS" SG_ 2651930650 Digit_09_ORC 0;
BA_ "GenSigTimeoutTime_EPS" SG_ 2651930650 Digit_09_ORC 0;
BA_ "GenSigTimeoutTime_ORC" SG_ 2651930650 Digit_09_ORC 0;
BA_ "GenSigTimeoutTime_PAM" SG_ 2651930650 Digit_09_ORC 0;
BA_ "GenSigTimeoutTime_SGW" SG_ 2651930650 Digit_09_ORC 0;
BA_ "GenSigTimeoutTime_TRSKM" SG_ 2651930650 Digit_09_ORC 0;
BA_ "GenSigTimeoutTime_BSM2" SG_ 2651930650 Digit_10_ORC 0;
BA_ "GenSigTimeoutTime_CADM2" SG_ 2651930650 Digit_10_ORC 0;
BA_ "GenSigTimeoutTime_CVADAS" SG_ 2651930650 Digit_10_ORC 0;
BA_ "GenSigTimeoutTime_EPS" SG_ 2651930650 Digit_10_ORC 0;
BA_ "GenSigTimeoutTime_ORC" SG_ 2651930650 Digit_10_ORC 0;
BA_ "GenSigTimeoutTime_PAM" SG_ 2651930650 Digit_10_ORC 0;
BA_ "GenSigTimeoutTime_SGW" SG_ 2651930650 Digit_10_ORC 0;
BA_ "GenSigTimeoutTime_TRSKM" SG_ 2651930650 Digit_10_ORC 0;
BA_ "GenSigTimeoutTime_BSM2" SG_ 2651930650 Digit_11_ORC 0;
BA_ "GenSigTimeoutTime_CADM2" SG_ 2651930650 Digit_11_ORC 0;
BA_ "GenSigTimeoutTime_CVADAS" SG_ 2651930650 Digit_11_ORC 0;
BA_ "GenSigTimeoutTime_EPS" SG_ 2651930650 Digit_11_ORC 0;
BA_ "GenSigTimeoutTime_ORC" SG_ 2651930650 Digit_11_ORC 0;
BA_ "GenSigTimeoutTime_PAM" SG_ 2651930650 Digit_11_ORC 0;
BA_ "GenSigTimeoutTime_SGW" SG_ 2651930650 Digit_11_ORC 0;
BA_ "GenSigTimeoutTime_TRSKM" SG_ 2651930650 Digit_11_ORC 0;
BA_ "GenSigSendType" SG_ 2651930648 Digit_01_PAM 1;
BA_ "GenSigTimeoutTime_BSM2" SG_ 2651930648 Digit_01_PAM 0;
BA_ "GenSigTimeoutTime_CADM2" SG_ 2651930648 Digit_01_PAM 0;
BA_ "GenSigTimeoutTime_CVADAS" SG_ 2651930648 Digit_01_PAM 0;
BA_ "GenSigTimeoutTime_EPS" SG_ 2651930648 Digit_01_PAM 0;
BA_ "GenSigTimeoutTime_ORC" SG_ 2651930648 Digit_01_PAM 0;
BA_ "GenSigTimeoutTime_PAM" SG_ 2651930648 Digit_01_PAM 0;
BA_ "GenSigTimeoutTime_SGW" SG_ 2651930648 Digit_01_PAM 0;
BA_ "GenSigTimeoutTime_TRSKM" SG_ 2651930648 Digit_01_PAM 0;
BA_ "GenSigTimeoutTime_BSM2" SG_ 2651930648 Digit_02_PAM 0;
BA_ "GenSigTimeoutTime_CADM2" SG_ 2651930648 Digit_02_PAM 0;
BA_ "GenSigTimeoutTime_CVADAS" SG_ 2651930648 Digit_02_PAM 0;
BA_ "GenSigTimeoutTime_EPS" SG_ 2651930648 Digit_02_PAM 0;
BA_ "GenSigTimeoutTime_ORC" SG_ 2651930648 Digit_02_PAM 0;
BA_ "GenSigTimeoutTime_PAM" SG_ 2651930648 Digit_02_PAM 0;
BA_ "GenSigTimeoutTime_SGW" SG_ 2651930648 Digit_02_PAM 0;
BA_ "GenSigTimeoutTime_TRSKM" SG_ 2651930648 Digit_02_PAM 0;
BA_ "GenSigTimeoutTime_BSM2" SG_ 2651930648 Digit_03_PAM 0;
BA_ "GenSigTimeoutTime_CADM2" SG_ 2651930648 Digit_03_PAM 0;
BA_ "GenSigTimeoutTime_CVADAS" SG_ 2651930648 Digit_03_PAM 0;
BA_ "GenSigTimeoutTime_EPS" SG_ 2651930648 Digit_03_PAM 0;
BA_ "GenSigTimeoutTime_ORC" SG_ 2651930648 Digit_03_PAM 0;
BA_ "GenSigTimeoutTime_PAM" SG_ 2651930648 Digit_03_PAM 0;
BA_ "GenSigTimeoutTime_SGW" SG_ 2651930648 Digit_03_PAM 0;
BA_ "GenSigTimeoutTime_TRSKM" SG_ 2651930648 Digit_03_PAM 0;
BA_ "GenSigTimeoutTime_BSM2" SG_ 2651930648 Digit_04_PAM 0;
BA_ "GenSigTimeoutTime_CADM2" SG_ 2651930648 Digit_04_PAM 0;
BA_ "GenSigTimeoutTime_CVADAS" SG_ 2651930648 Digit_04_PAM 0;
BA_ "GenSigTimeoutTime_EPS" SG_ 2651930648 Digit_04_PAM 0;
BA_ "GenSigTimeoutTime_ORC" SG_ 2651930648 Digit_04_PAM 0;
BA_ "GenSigTimeoutTime_PAM" SG_ 2651930648 Digit_04_PAM 0;
BA_ "GenSigTimeoutTime_SGW" SG_ 2651930648 Digit_04_PAM 0;
BA_ "GenSigTimeoutTime_TRSKM" SG_ 2651930648 Digit_04_PAM 0;
BA_ "GenSigTimeoutTime_BSM2" SG_ 2651930648 Digit_05_PAM 0;
BA_ "GenSigTimeoutTime_CADM2" SG_ 2651930648 Digit_05_PAM 0;
BA_ "GenSigTimeoutTime_CVADAS" SG_ 2651930648 Digit_05_PAM 0;
BA_ "GenSigTimeoutTime_EPS" SG_ 2651930648 Digit_05_PAM 0;
BA_ "GenSigTimeoutTime_ORC" SG_ 2651930648 Digit_05_PAM 0;
BA_ "GenSigTimeoutTime_PAM" SG_ 2651930648 Digit_05_PAM 0;
BA_ "GenSigTimeoutTime_SGW" SG_ 2651930648 Digit_05_PAM 0;
BA_ "GenSigTimeoutTime_TRSKM" SG_ 2651930648 Digit_05_PAM 0;
BA_ "GenSigTimeoutTime_BSM2" SG_ 2651930648 Digit_06_PAM 0;
BA_ "GenSigTimeoutTime_CADM2" SG_ 2651930648 Digit_06_PAM 0;
BA_ "GenSigTimeoutTime_CVADAS" SG_ 2651930648 Digit_06_PAM 0;
BA_ "GenSigTimeoutTime_EPS" SG_ 2651930648 Digit_06_PAM 0;
BA_ "GenSigTimeoutTime_ORC" SG_ 2651930648 Digit_06_PAM 0;
BA_ "GenSigTimeoutTime_PAM" SG_ 2651930648 Digit_06_PAM 0;
BA_ "GenSigTimeoutTime_SGW" SG_ 2651930648 Digit_06_PAM 0;
BA_ "GenSigTimeoutTime_TRSKM" SG_ 2651930648 Digit_06_PAM 0;
BA_ "GenSigTimeoutTime_BSM2" SG_ 2651930648 Digit_07_PAM 0;
BA_ "GenSigTimeoutTime_CADM2" SG_ 2651930648 Digit_07_PAM 0;
BA_ "GenSigTimeoutTime_CVADAS" SG_ 2651930648 Digit_07_PAM 0;
BA_ "GenSigTimeoutTime_EPS" SG_ 2651930648 Digit_07_PAM 0;
BA_ "GenSigTimeoutTime_ORC" SG_ 2651930648 Digit_07_PAM 0;
BA_ "GenSigTimeoutTime_PAM" SG_ 2651930648 Digit_07_PAM 0;
BA_ "GenSigTimeoutTime_SGW" SG_ 2651930648 Digit_07_PAM 0;
BA_ "GenSigTimeoutTime_TRSKM" SG_ 2651930648 Digit_07_PAM 0;
BA_ "GenSigTimeoutTime_BSM2" SG_ 2651930648 Digit_08_PAM 0;
BA_ "GenSigTimeoutTime_CADM2" SG_ 2651930648 Digit_08_PAM 0;
BA_ "GenSigTimeoutTime_CVADAS" SG_ 2651930648 Digit_08_PAM 0;
BA_ "GenSigTimeoutTime_EPS" SG_ 2651930648 Digit_08_PAM 0;
BA_ "GenSigTimeoutTime_ORC" SG_ 2651930648 Digit_08_PAM 0;
BA_ "GenSigTimeoutTime_PAM" SG_ 2651930648 Digit_08_PAM 0;
BA_ "GenSigTimeoutTime_SGW" SG_ 2651930648 Digit_08_PAM 0;
BA_ "GenSigTimeoutTime_TRSKM" SG_ 2651930648 Digit_08_PAM 0;
BA_ "GenSigTimeoutTime_BSM2" SG_ 2651930648 Digit_09_PAM 0;
BA_ "GenSigTimeoutTime_CADM2" SG_ 2651930648 Digit_09_PAM 0;
BA_ "GenSigTimeoutTime_CVADAS" SG_ 2651930648 Digit_09_PAM 0;
BA_ "GenSigTimeoutTime_EPS" SG_ 2651930648 Digit_09_PAM 0;
BA_ "GenSigTimeoutTime_ORC" SG_ 2651930648 Digit_09_PAM 0;
BA_ "GenSigTimeoutTime_PAM" SG_ 2651930648 Digit_09_PAM 0;
BA_ "GenSigTimeoutTime_SGW" SG_ 2651930648 Digit_09_PAM 0;
BA_ "GenSigTimeoutTime_TRSKM" SG_ 2651930648 Digit_09_PAM 0;
BA_ "GenSigTimeoutTime_BSM2" SG_ 2651930648 Digit_10_PAM 0;
BA_ "GenSigTimeoutTime_CADM2" SG_ 2651930648 Digit_10_PAM 0;
BA_ "GenSigTimeoutTime_CVADAS" SG_ 2651930648 Digit_10_PAM 0;
BA_ "GenSigTimeoutTime_EPS" SG_ 2651930648 Digit_10_PAM 0;
BA_ "GenSigTimeoutTime_ORC" SG_ 2651930648 Digit_10_PAM 0;
BA_ "GenSigTimeoutTime_PAM" SG_ 2651930648 Digit_10_PAM 0;
BA_ "GenSigTimeoutTime_SGW" SG_ 2651930648 Digit_10_PAM 0;
BA_ "GenSigTimeoutTime_TRSKM" SG_ 2651930648 Digit_10_PAM 0;
BA_ "GenSigTimeoutTime_BSM2" SG_ 2651930648 Digit_11_PAM 0;
BA_ "GenSigTimeoutTime_CADM2" SG_ 2651930648 Digit_11_PAM 0;
BA_ "GenSigTimeoutTime_CVADAS" SG_ 2651930648 Digit_11_PAM 0;
BA_ "GenSigTimeoutTime_EPS" SG_ 2651930648 Digit_11_PAM 0;
BA_ "GenSigTimeoutTime_ORC" SG_ 2651930648 Digit_11_PAM 0;
BA_ "GenSigTimeoutTime_PAM" SG_ 2651930648 Digit_11_PAM 0;
BA_ "GenSigTimeoutTime_SGW" SG_ 2651930648 Digit_11_PAM 0;
BA_ "GenSigTimeoutTime_TRSKM" SG_ 2651930648 Digit_11_PAM 0;
BA_ "GenSigSendType" SG_ 2651930801 Digit_01_TRLR_REV 1;
BA_ "GenSigTimeoutTime_BSM2" SG_ 2651930801 Digit_01_TRLR_REV 0;
BA_ "GenSigTimeoutTime_CADM2" SG_ 2651930801 Digit_01_TRLR_REV 0;
BA_ "GenSigTimeoutTime_CVADAS" SG_ 2651930801 Digit_01_TRLR_REV 0;
BA_ "GenSigTimeoutTime_EPS" SG_ 2651930801 Digit_01_TRLR_REV 0;
BA_ "GenSigTimeoutTime_ORC" SG_ 2651930801 Digit_01_TRLR_REV 0;
BA_ "GenSigTimeoutTime_PAM" SG_ 2651930801 Digit_01_TRLR_REV 0;
BA_ "GenSigTimeoutTime_SGW" SG_ 2651930801 Digit_01_TRLR_REV 0;
BA_ "GenSigTimeoutTime_TRSKM" SG_ 2651930801 Digit_01_TRLR_REV 0;
BA_ "GenSigTimeoutTime_BSM2" SG_ 2651930801 Digit_02_TRLR_REV 0;
BA_ "GenSigTimeoutTime_CADM2" SG_ 2651930801 Digit_02_TRLR_REV 0;
BA_ "GenSigTimeoutTime_CVADAS" SG_ 2651930801 Digit_02_TRLR_REV 0;
BA_ "GenSigTimeoutTime_EPS" SG_ 2651930801 Digit_02_TRLR_REV 0;
BA_ "GenSigTimeoutTime_ORC" SG_ 2651930801 Digit_02_TRLR_REV 0;
BA_ "GenSigTimeoutTime_PAM" SG_ 2651930801 Digit_02_TRLR_REV 0;
BA_ "GenSigTimeoutTime_SGW" SG_ 2651930801 Digit_02_TRLR_REV 0;
BA_ "GenSigTimeoutTime_TRSKM" SG_ 2651930801 Digit_02_TRLR_REV 0;
BA_ "GenSigTimeoutTime_BSM2" SG_ 2651930801 Digit_03_TRLR_REV 0;
BA_ "GenSigTimeoutTime_CADM2" SG_ 2651930801 Digit_03_TRLR_REV 0;
BA_ "GenSigTimeoutTime_CVADAS" SG_ 2651930801 Digit_03_TRLR_REV 0;
BA_ "GenSigTimeoutTime_EPS" SG_ 2651930801 Digit_03_TRLR_REV 0;
BA_ "GenSigTimeoutTime_ORC" SG_ 2651930801 Digit_03_TRLR_REV 0;
BA_ "GenSigTimeoutTime_PAM" SG_ 2651930801 Digit_03_TRLR_REV 0;
BA_ "GenSigTimeoutTime_SGW" SG_ 2651930801 Digit_03_TRLR_REV 0;
BA_ "GenSigTimeoutTime_TRSKM" SG_ 2651930801 Digit_03_TRLR_REV 0;
BA_ "GenSigTimeoutTime_BSM2" SG_ 2651930801 Digit_04_TRLR_REV 0;
BA_ "GenSigTimeoutTime_CADM2" SG_ 2651930801 Digit_04_TRLR_REV 0;
BA_ "GenSigTimeoutTime_CVADAS" SG_ 2651930801 Digit_04_TRLR_REV 0;
BA_ "GenSigTimeoutTime_EPS" SG_ 2651930801 Digit_04_TRLR_REV 0;
BA_ "GenSigTimeoutTime_ORC" SG_ 2651930801 Digit_04_TRLR_REV 0;
BA_ "GenSigTimeoutTime_PAM" SG_ 2651930801 Digit_04_TRLR_REV 0;
BA_ "GenSigTimeoutTime_SGW" SG_ 2651930801 Digit_04_TRLR_REV 0;
BA_ "GenSigTimeoutTime_TRSKM" SG_ 2651930801 Digit_04_TRLR_REV 0;
BA_ "GenSigTimeoutTime_BSM2" SG_ 2651930801 Digit_05_TRLR_REV 0;
BA_ "GenSigTimeoutTime_CADM2" SG_ 2651930801 Digit_05_TRLR_REV 0;
BA_ "GenSigTimeoutTime_CVADAS" SG_ 2651930801 Digit_05_TRLR_REV 0;
BA_ "GenSigTimeoutTime_EPS" SG_ 2651930801 Digit_05_TRLR_REV 0;
BA_ "GenSigTimeoutTime_ORC" SG_ 2651930801 Digit_05_TRLR_REV 0;
BA_ "GenSigTimeoutTime_PAM" SG_ 2651930801 Digit_05_TRLR_REV 0;
BA_ "GenSigTimeoutTime_SGW" SG_ 2651930801 Digit_05_TRLR_REV 0;
BA_ "GenSigTimeoutTime_TRSKM" SG_ 2651930801 Digit_05_TRLR_REV 0;
BA_ "GenSigTimeoutTime_BSM2" SG_ 2651930801 Digit_06_TRLR_REV 0;
BA_ "GenSigTimeoutTime_CADM2" SG_ 2651930801 Digit_06_TRLR_REV 0;
BA_ "GenSigTimeoutTime_CVADAS" SG_ 2651930801 Digit_06_TRLR_REV 0;
BA_ "GenSigTimeoutTime_EPS" SG_ 2651930801 Digit_06_TRLR_REV 0;
BA_ "GenSigTimeoutTime_ORC" SG_ 2651930801 Digit_06_TRLR_REV 0;
BA_ "GenSigTimeoutTime_PAM" SG_ 2651930801 Digit_06_TRLR_REV 0;
BA_ "GenSigTimeoutTime_SGW" SG_ 2651930801 Digit_06_TRLR_REV 0;
BA_ "GenSigTimeoutTime_TRSKM" SG_ 2651930801 Digit_06_TRLR_REV 0;
BA_ "GenSigTimeoutTime_BSM2" SG_ 2651930801 Digit_07_TRLR_REV 0;
BA_ "GenSigTimeoutTime_CADM2" SG_ 2651930801 Digit_07_TRLR_REV 0;
BA_ "GenSigTimeoutTime_CVADAS" SG_ 2651930801 Digit_07_TRLR_REV 0;
BA_ "GenSigTimeoutTime_EPS" SG_ 2651930801 Digit_07_TRLR_REV 0;
BA_ "GenSigTimeoutTime_ORC" SG_ 2651930801 Digit_07_TRLR_REV 0;
BA_ "GenSigTimeoutTime_PAM" SG_ 2651930801 Digit_07_TRLR_REV 0;
BA_ "GenSigTimeoutTime_SGW" SG_ 2651930801 Digit_07_TRLR_REV 0;
BA_ "GenSigTimeoutTime_TRSKM" SG_ 2651930801 Digit_07_TRLR_REV 0;
BA_ "GenSigTimeoutTime_BSM2" SG_ 2651930801 Digit_08_TRLR_REV 0;
BA_ "GenSigTimeoutTime_CADM2" SG_ 2651930801 Digit_08_TRLR_REV 0;
BA_ "GenSigTimeoutTime_CVADAS" SG_ 2651930801 Digit_08_TRLR_REV 0;
BA_ "GenSigTimeoutTime_EPS" SG_ 2651930801 Digit_08_TRLR_REV 0;
BA_ "GenSigTimeoutTime_ORC" SG_ 2651930801 Digit_08_TRLR_REV 0;
BA_ "GenSigTimeoutTime_PAM" SG_ 2651930801 Digit_08_TRLR_REV 0;
BA_ "GenSigTimeoutTime_SGW" SG_ 2651930801 Digit_08_TRLR_REV 0;
BA_ "GenSigTimeoutTime_TRSKM" SG_ 2651930801 Digit_08_TRLR_REV 0;
BA_ "GenSigTimeoutTime_BSM2" SG_ 2651930801 Digit_09_TRLR_REV 0;
BA_ "GenSigTimeoutTime_CADM2" SG_ 2651930801 Digit_09_TRLR_REV 0;
BA_ "GenSigTimeoutTime_CVADAS" SG_ 2651930801 Digit_09_TRLR_REV 0;
BA_ "GenSigTimeoutTime_EPS" SG_ 2651930801 Digit_09_TRLR_REV 0;
BA_ "GenSigTimeoutTime_ORC" SG_ 2651930801 Digit_09_TRLR_REV 0;
BA_ "GenSigTimeoutTime_PAM" SG_ 2651930801 Digit_09_TRLR_REV 0;
BA_ "GenSigTimeoutTime_SGW" SG_ 2651930801 Digit_09_TRLR_REV 0;
BA_ "GenSigTimeoutTime_TRSKM" SG_ 2651930801 Digit_09_TRLR_REV 0;
BA_ "GenSigTimeoutTime_BSM2" SG_ 2651930801 Digit_10_TRLR_REV 0;
BA_ "GenSigTimeoutTime_CADM2" SG_ 2651930801 Digit_10_TRLR_REV 0;
BA_ "GenSigTimeoutTime_CVADAS" SG_ 2651930801 Digit_10_TRLR_REV 0;
BA_ "GenSigTimeoutTime_EPS" SG_ 2651930801 Digit_10_TRLR_REV 0;
BA_ "GenSigTimeoutTime_ORC" SG_ 2651930801 Digit_10_TRLR_REV 0;
BA_ "GenSigTimeoutTime_PAM" SG_ 2651930801 Digit_10_TRLR_REV 0;
BA_ "GenSigTimeoutTime_SGW" SG_ 2651930801 Digit_10_TRLR_REV 0;
BA_ "GenSigTimeoutTime_TRSKM" SG_ 2651930801 Digit_10_TRLR_REV 0;
BA_ "GenSigTimeoutTime_BSM2" SG_ 2651930801 Digit_11_TRLR_REV 0;
BA_ "GenSigTimeoutTime_CADM2" SG_ 2651930801 Digit_11_TRLR_REV 0;
BA_ "GenSigTimeoutTime_CVADAS" SG_ 2651930801 Digit_11_TRLR_REV 0;
BA_ "GenSigTimeoutTime_EPS" SG_ 2651930801 Digit_11_TRLR_REV 0;
BA_ "GenSigTimeoutTime_ORC" SG_ 2651930801 Digit_11_TRLR_REV 0;
BA_ "GenSigTimeoutTime_PAM" SG_ 2651930801 Digit_11_TRLR_REV 0;
BA_ "GenSigTimeoutTime_SGW" SG_ 2651930801 Digit_11_TRLR_REV 0;
BA_ "GenSigTimeoutTime_TRSKM" SG_ 2651930801 Digit_11_TRLR_REV 0;
BA_ "GenSigTimeoutTime_BSM2" SG_ 275 CRC_CVPAM_FD_Control 0;
BA_ "GenSigTimeoutTime_CADM2" SG_ 275 CRC_CVPAM_FD_Control 0;
BA_ "GenSigTimeoutTime_CVADAS" SG_ 275 CRC_CVPAM_FD_Control 0;
BA_ "GenSigTimeoutTime_EPS" SG_ 275 CRC_CVPAM_FD_Control 0;
BA_ "GenSigTimeoutTime_ORC" SG_ 275 CRC_CVPAM_FD_Control 0;
BA_ "GenSigTimeoutTime_PAM" SG_ 275 CRC_CVPAM_FD_Control 0;
BA_ "GenSigTimeoutTime_SGW" SG_ 275 CRC_CVPAM_FD_Control 0;
BA_ "GenSigTimeoutTime_TRSKM" SG_ 275 CRC_CVPAM_FD_Control 0;
BA_ "GenSigTimeoutTime_BSM2" SG_ 275 MessageCounter_CVPAM_FD_Control 0;
BA_ "GenSigTimeoutTime_CADM2" SG_ 275 MessageCounter_CVPAM_FD_Control 0;
BA_ "GenSigTimeoutTime_CVADAS" SG_ 275 MessageCounter_CVPAM_FD_Control 0;
BA_ "GenSigTimeoutTime_EPS" SG_ 275 MessageCounter_CVPAM_FD_Control 0;
BA_ "GenSigTimeoutTime_ORC" SG_ 275 MessageCounter_CVPAM_FD_Control 0;
BA_ "GenSigTimeoutTime_PAM" SG_ 275 MessageCounter_CVPAM_FD_Control 0;
BA_ "GenSigTimeoutTime_SGW" SG_ 275 MessageCounter_CVPAM_FD_Control 0;
BA_ "GenSigTimeoutTime_TRSKM" SG_ 275 MessageCounter_CVPAM_FD_Control 0;
BA_ "GenSigTimeoutTime_BSM2" SG_ 275 PPPA_TurnIndicatorRqst 0;
BA_ "GenSigTimeoutTime_CADM2" SG_ 275 PPPA_TurnIndicatorRqst 0;
BA_ "GenSigTimeoutTime_CVADAS" SG_ 275 PPPA_TurnIndicatorRqst 0;
BA_ "GenSigTimeoutTime_EPS" SG_ 275 PPPA_TurnIndicatorRqst 0;
BA_ "GenSigTimeoutTime_ORC" SG_ 275 PPPA_TurnIndicatorRqst 0;
BA_ "GenSigTimeoutTime_PAM" SG_ 275 PPPA_TurnIndicatorRqst 0;
BA_ "GenSigTimeoutTime_SGW" SG_ 275 PPPA_TurnIndicatorRqst 0;
BA_ "GenSigTimeoutTime_TRSKM" SG_ 275 PPPA_TurnIndicatorRqst 0;
BA_ "GenSigTimeoutTime_BSM2" SG_ 275 RR_PAM_Brk_RqSts 0;
BA_ "GenSigTimeoutTime_CADM2" SG_ 275 RR_PAM_Brk_RqSts 0;
BA_ "GenSigTimeoutTime_CVADAS" SG_ 275 RR_PAM_Brk_RqSts 0;
BA_ "GenSigTimeoutTime_EPS" SG_ 275 RR_PAM_Brk_RqSts 0;
BA_ "GenSigTimeoutTime_ORC" SG_ 275 RR_PAM_Brk_RqSts 0;
BA_ "GenSigTimeoutTime_PAM" SG_ 275 RR_PAM_Brk_RqSts 0;
BA_ "GenSigTimeoutTime_SGW" SG_ 275 RR_PAM_Brk_RqSts 0;
BA_ "GenSigTimeoutTime_TRSKM" SG_ 275 RR_PAM_Brk_RqSts 0;
BA_ "GenSigTimeoutTime_BSM2" SG_ 275 RR_PAM_Dist 0;
BA_ "GenSigTimeoutTime_CADM2" SG_ 275 RR_PAM_Dist 0;
BA_ "GenSigTimeoutTime_CVADAS" SG_ 275 RR_PAM_Dist 0;
BA_ "GenSigTimeoutTime_EPS" SG_ 275 RR_PAM_Dist 0;
BA_ "GenSigTimeoutTime_ORC" SG_ 275 RR_PAM_Dist 0;
BA_ "GenSigTimeoutTime_PAM" SG_ 275 RR_PAM_Dist 0;
BA_ "GenSigTimeoutTime_SGW" SG_ 275 RR_PAM_Dist 0;
BA_ "GenSigTimeoutTime_TRSKM" SG_ 275 RR_PAM_Dist 0;
BA_ "GenSigTimeoutTime_BSM2" SG_ 275 RR_PAM_StopControlSts 0;
BA_ "GenSigTimeoutTime_CADM2" SG_ 275 RR_PAM_StopControlSts 0;
BA_ "GenSigTimeoutTime_CVADAS" SG_ 275 RR_PAM_StopControlSts 0;
BA_ "GenSigTimeoutTime_EPS" SG_ 275 RR_PAM_StopControlSts 0;
BA_ "GenSigTimeoutTime_ORC" SG_ 275 RR_PAM_StopControlSts 0;
BA_ "GenSigTimeoutTime_PAM" SG_ 275 RR_PAM_StopControlSts 0;
BA_ "GenSigTimeoutTime_SGW" SG_ 275 RR_PAM_StopControlSts 0;
BA_ "GenSigTimeoutTime_TRSKM" SG_ 275 RR_PAM_StopControlSts 0;
BA_ "GenSigSendType" SG_ 950 Alert_CHF 3;
BA_ "GenSigTimeoutTime_BSM2" SG_ 950 Alert_CHF 0;
BA_ "GenSigTimeoutTime_CADM2" SG_ 950 Alert_CHF 0;
BA_ "GenSigTimeoutTime_CVADAS" SG_ 950 Alert_CHF 0;
BA_ "GenSigTimeoutTime_EPS" SG_ 950 Alert_CHF 0;
BA_ "GenSigTimeoutTime_ORC" SG_ 950 Alert_CHF 0;
BA_ "GenSigTimeoutTime_PAM" SG_ 950 Alert_CHF 0;
BA_ "GenSigTimeoutTime_SGW" SG_ 950 Alert_CHF 0;
BA_ "GenSigTimeoutTime_TRSKM" SG_ 950 Alert_CHF 0;
BA_ "GenSigSendType" SG_ 950 Alert_CHR 3;
BA_ "GenSigTimeoutTime_BSM2" SG_ 950 Alert_CHR 0;
BA_ "GenSigTimeoutTime_CADM2" SG_ 950 Alert_CHR 0;
BA_ "GenSigTimeoutTime_CVADAS" SG_ 950 Alert_CHR 0;
BA_ "GenSigTimeoutTime_EPS" SG_ 950 Alert_CHR 0;
BA_ "GenSigTimeoutTime_ORC" SG_ 950 Alert_CHR 0;
BA_ "GenSigTimeoutTime_PAM" SG_ 950 Alert_CHR 0;
BA_ "GenSigTimeoutTime_SGW" SG_ 950 Alert_CHR 0;
BA_ "GenSigTimeoutTime_TRSKM" SG_ 950 Alert_CHR 0;
BA_ "GenSigSendType" SG_ 950 Alert_LHF 3;
BA_ "GenSigTimeoutTime_BSM2" SG_ 950 Alert_LHF 0;
BA_ "GenSigTimeoutTime_CADM2" SG_ 950 Alert_LHF 0;
BA_ "GenSigTimeoutTime_CVADAS" SG_ 950 Alert_LHF 0;
BA_ "GenSigTimeoutTime_EPS" SG_ 950 Alert_LHF 0;
BA_ "GenSigTimeoutTime_ORC" SG_ 950 Alert_LHF 0;
BA_ "GenSigTimeoutTime_PAM" SG_ 950 Alert_LHF 0;
BA_ "GenSigTimeoutTime_SGW" SG_ 950 Alert_LHF 0;
BA_ "GenSigTimeoutTime_TRSKM" SG_ 950 Alert_LHF 0;
BA_ "GenSigSendType" SG_ 950 Alert_LHR 3;
BA_ "GenSigTimeoutTime_BSM2" SG_ 950 Alert_LHR 0;
BA_ "GenSigTimeoutTime_CADM2" SG_ 950 Alert_LHR 0;
BA_ "GenSigTimeoutTime_CVADAS" SG_ 950 Alert_LHR 0;
BA_ "GenSigTimeoutTime_EPS" SG_ 950 Alert_LHR 0;
BA_ "GenSigTimeoutTime_ORC" SG_ 950 Alert_LHR 0;
BA_ "GenSigTimeoutTime_PAM" SG_ 950 Alert_LHR 0;
BA_ "GenSigTimeoutTime_SGW" SG_ 950 Alert_LHR 0;
BA_ "GenSigTimeoutTime_TRSKM" SG_ 950 Alert_LHR 0;
BA_ "GenSigSendType" SG_ 950 Alert_RHF 3;
BA_ "GenSigTimeoutTime_BSM2" SG_ 950 Alert_RHF 0;
BA_ "GenSigTimeoutTime_CADM2" SG_ 950 Alert_RHF 0;
BA_ "GenSigTimeoutTime_CVADAS" SG_ 950 Alert_RHF 0;
BA_ "GenSigTimeoutTime_EPS" SG_ 950 Alert_RHF 0;
BA_ "GenSigTimeoutTime_ORC" SG_ 950 Alert_RHF 0;
BA_ "GenSigTimeoutTime_PAM" SG_ 950 Alert_RHF 0;
BA_ "GenSigTimeoutTime_SGW" SG_ 950 Alert_RHF 0;
BA_ "GenSigTimeoutTime_TRSKM" SG_ 950 Alert_RHF 0;
BA_ "GenSigSendType" SG_ 950 Alert_RHR 3;
BA_ "GenSigTimeoutTime_BSM2" SG_ 950 Alert_RHR 0;
BA_ "GenSigTimeoutTime_CADM2" SG_ 950 Alert_RHR 0;
BA_ "GenSigTimeoutTime_CVADAS" SG_ 950 Alert_RHR 0;
BA_ "GenSigTimeoutTime_EPS" SG_ 950 Alert_RHR 0;
BA_ "GenSigTimeoutTime_ORC" SG_ 950 Alert_RHR 0;
BA_ "GenSigTimeoutTime_PAM" SG_ 950 Alert_RHR 0;
BA_ "GenSigTimeoutTime_SGW" SG_ 950 Alert_RHR 0;
BA_ "GenSigTimeoutTime_TRSKM" SG_ 950 Alert_RHR 0;
BA_ "GenSigSendType" SG_ 950 AUXCamsRQSts 3;
BA_ "GenSigTimeoutTime_BCM" SG_ 950 AUXCamsRQSts 0;
BA_ "GenSigTimeoutTime_BSM2" SG_ 950 AUXCamsRQSts 0;
BA_ "GenSigTimeoutTime_CADM2" SG_ 950 AUXCamsRQSts 0;
BA_ "GenSigTimeoutTime_CVADAS" SG_ 950 AUXCamsRQSts 0;
BA_ "GenSigTimeoutTime_EPS" SG_ 950 AUXCamsRQSts 0;
BA_ "GenSigTimeoutTime_ORC" SG_ 950 AUXCamsRQSts 0;
BA_ "GenSigTimeoutTime_PAM" SG_ 950 AUXCamsRQSts 0;
BA_ "GenSigTimeoutTime_TRSKM" SG_ 950 AUXCamsRQSts 0;
BA_ "GenSigSendType" SG_ 950 ChimeActivation_LHF 3;
BA_ "GenSigTimeoutTime_BSM2" SG_ 950 ChimeActivation_LHF 0;
BA_ "GenSigTimeoutTime_CADM2" SG_ 950 ChimeActivation_LHF 0;
BA_ "GenSigTimeoutTime_CVADAS" SG_ 950 ChimeActivation_LHF 0;
BA_ "GenSigTimeoutTime_EPS" SG_ 950 ChimeActivation_LHF 0;
BA_ "GenSigTimeoutTime_ORC" SG_ 950 ChimeActivation_LHF 0;
BA_ "GenSigTimeoutTime_PAM" SG_ 950 ChimeActivation_LHF 0;
BA_ "GenSigTimeoutTime_TRSKM" SG_ 950 ChimeActivation_LHF 0;
BA_ "GenSigSendType" SG_ 950 ChimeActivation_LHR 3;
BA_ "GenSigTimeoutTime_BSM2" SG_ 950 ChimeActivation_LHR 0;
BA_ "GenSigTimeoutTime_CADM2" SG_ 950 ChimeActivation_LHR 0;
BA_ "GenSigTimeoutTime_CVADAS" SG_ 950 ChimeActivation_LHR 0;
BA_ "GenSigTimeoutTime_EPS" SG_ 950 ChimeActivation_LHR 0;
BA_ "GenSigTimeoutTime_ORC" SG_ 950 ChimeActivation_LHR 0;
BA_ "GenSigTimeoutTime_PAM" SG_ 950 ChimeActivation_LHR 0;
BA_ "GenSigTimeoutTime_SGW" SG_ 950 ChimeActivation_LHR 0;
BA_ "GenSigTimeoutTime_TRSKM" SG_ 950 ChimeActivation_LHR 0;
BA_ "GenSigSendType" SG_ 950 ChimeActivation_RHF 3;
BA_ "GenSigTimeoutTime_BSM2" SG_ 950 ChimeActivation_RHF 0;
BA_ "GenSigTimeoutTime_CADM2" SG_ 950 ChimeActivation_RHF 0;
BA_ "GenSigTimeoutTime_CVADAS" SG_ 950 ChimeActivation_RHF 0;
BA_ "GenSigTimeoutTime_EPS" SG_ 950 ChimeActivation_RHF 0;
BA_ "GenSigTimeoutTime_ORC" SG_ 950 ChimeActivation_RHF 0;
BA_ "GenSigTimeoutTime_PAM" SG_ 950 ChimeActivation_RHF 0;
BA_ "GenSigTimeoutTime_TRSKM" SG_ 950 ChimeActivation_RHF 0;
BA_ "GenSigSendType" SG_ 950 ChimeActivation_RHR 3;
BA_ "GenSigTimeoutTime_BSM2" SG_ 950 ChimeActivation_RHR 0;
BA_ "GenSigTimeoutTime_CADM2" SG_ 950 ChimeActivation_RHR 0;
BA_ "GenSigTimeoutTime_CVADAS" SG_ 950 ChimeActivation_RHR 0;
BA_ "GenSigTimeoutTime_EPS" SG_ 950 ChimeActivation_RHR 0;
BA_ "GenSigTimeoutTime_ORC" SG_ 950 ChimeActivation_RHR 0;
BA_ "GenSigTimeoutTime_PAM" SG_ 950 ChimeActivation_RHR 0;
BA_ "GenSigTimeoutTime_SGW" SG_ 950 ChimeActivation_RHR 0;
BA_ "GenSigTimeoutTime_TRSKM" SG_ 950 ChimeActivation_RHR 0;
BA_ "GenSigTimeoutTime_BSM2" SG_ 950 CRC_CVPAM_FD_Info 0;
BA_ "GenSigTimeoutTime_CADM2" SG_ 950 CRC_CVPAM_FD_Info 0;
BA_ "GenSigTimeoutTime_CVADAS" SG_ 950 CRC_CVPAM_FD_Info 0;
BA_ "GenSigTimeoutTime_EPS" SG_ 950 CRC_CVPAM_FD_Info 0;
BA_ "GenSigTimeoutTime_ORC" SG_ 950 CRC_CVPAM_FD_Info 0;
BA_ "GenSigTimeoutTime_PAM" SG_ 950 CRC_CVPAM_FD_Info 0;
BA_ "GenSigTimeoutTime_SGW" SG_ 950 CRC_CVPAM_FD_Info 0;
BA_ "GenSigSendType" SG_ 950 DisplayView2 3;
BA_ "GenSigTimeoutTime_BCM" SG_ 950 DisplayView2 0;
BA_ "GenSigTimeoutTime_BSM2" SG_ 950 DisplayView2 0;
BA_ "GenSigTimeoutTime_CADM2" SG_ 950 DisplayView2 0;
BA_ "GenSigTimeoutTime_CVADAS" SG_ 950 DisplayView2 0;
BA_ "GenSigTimeoutTime_EPS" SG_ 950 DisplayView2 0;
BA_ "GenSigTimeoutTime_ORC" SG_ 950 DisplayView2 0;
BA_ "GenSigTimeoutTime_PAM" SG_ 950 DisplayView2 0;
BA_ "GenSigTimeoutTime_TRSKM" SG_ 950 DisplayView2 0;
BA_ "GenSigSendType" SG_ 950 FrontSensorSts 3;
BA_ "GenSigTimeoutTime_BSM2" SG_ 950 FrontSensorSts 0;
BA_ "GenSigTimeoutTime_CADM2" SG_ 950 FrontSensorSts 0;
BA_ "GenSigTimeoutTime_CVADAS" SG_ 950 FrontSensorSts 0;
BA_ "GenSigTimeoutTime_EPS" SG_ 950 FrontSensorSts 0;
BA_ "GenSigTimeoutTime_ORC" SG_ 950 FrontSensorSts 0;
BA_ "GenSigTimeoutTime_PAM" SG_ 950 FrontSensorSts 0;
BA_ "GenSigTimeoutTime_TRSKM" SG_ 950 FrontSensorSts 0;
BA_ "GenSigSendType" SG_ 950 FT_PAM_LedControlSts 3;
BA_ "GenSigTimeoutTime_BSM2" SG_ 950 FT_PAM_LedControlSts 0;
BA_ "GenSigTimeoutTime_CADM2" SG_ 950 FT_PAM_LedControlSts 0;
BA_ "GenSigTimeoutTime_CVADAS" SG_ 950 FT_PAM_LedControlSts 0;
BA_ "GenSigTimeoutTime_EPS" SG_ 950 FT_PAM_LedControlSts 0;
BA_ "GenSigTimeoutTime_ORC" SG_ 950 FT_PAM_LedControlSts 0;
BA_ "GenSigTimeoutTime_PAM" SG_ 950 FT_PAM_LedControlSts 0;
BA_ "GenSigTimeoutTime_SGW" SG_ 950 FT_PAM_LedControlSts 0;
BA_ "GenSigTimeoutTime_TRSKM" SG_ 950 FT_PAM_LedControlSts 0;
BA_ "GenSigSendType" SG_ 950 Graphic_CHF 3;
BA_ "GenSigTimeoutTime_BSM2" SG_ 950 Graphic_CHF 0;
BA_ "GenSigTimeoutTime_CADM2" SG_ 950 Graphic_CHF 0;
BA_ "GenSigTimeoutTime_CVADAS" SG_ 950 Graphic_CHF 0;
BA_ "GenSigTimeoutTime_EPS" SG_ 950 Graphic_CHF 0;
BA_ "GenSigTimeoutTime_ORC" SG_ 950 Graphic_CHF 0;
BA_ "GenSigTimeoutTime_PAM" SG_ 950 Graphic_CHF 0;
BA_ "GenSigTimeoutTime_SGW" SG_ 950 Graphic_CHF 0;
BA_ "GenSigTimeoutTime_TRSKM" SG_ 950 Graphic_CHF 0;
BA_ "GenSigSendType" SG_ 950 Graphic_CHR 3;
BA_ "GenSigTimeoutTime_BSM2" SG_ 950 Graphic_CHR 0;
BA_ "GenSigTimeoutTime_CADM2" SG_ 950 Graphic_CHR 0;
BA_ "GenSigTimeoutTime_CVADAS" SG_ 950 Graphic_CHR 0;
BA_ "GenSigTimeoutTime_EPS" SG_ 950 Graphic_CHR 0;
BA_ "GenSigTimeoutTime_ORC" SG_ 950 Graphic_CHR 0;
BA_ "GenSigTimeoutTime_PAM" SG_ 950 Graphic_CHR 0;
BA_ "GenSigTimeoutTime_SGW" SG_ 950 Graphic_CHR 0;
BA_ "GenSigTimeoutTime_TRSKM" SG_ 950 Graphic_CHR 0;
BA_ "GenSigSendType" SG_ 950 Graphic_LHF 3;
BA_ "GenSigTimeoutTime_BSM2" SG_ 950 Graphic_LHF 0;
BA_ "GenSigTimeoutTime_CADM2" SG_ 950 Graphic_LHF 0;
BA_ "GenSigTimeoutTime_CVADAS" SG_ 950 Graphic_LHF 0;
BA_ "GenSigTimeoutTime_EPS" SG_ 950 Graphic_LHF 0;
BA_ "GenSigTimeoutTime_ORC" SG_ 950 Graphic_LHF 0;
BA_ "GenSigTimeoutTime_PAM" SG_ 950 Graphic_LHF 0;
BA_ "GenSigTimeoutTime_SGW" SG_ 950 Graphic_LHF 0;
BA_ "GenSigTimeoutTime_TRSKM" SG_ 950 Graphic_LHF 0;
BA_ "GenSigSendType" SG_ 950 Graphic_LHR 3;
BA_ "GenSigTimeoutTime_BSM2" SG_ 950 Graphic_LHR 0;
BA_ "GenSigTimeoutTime_CADM2" SG_ 950 Graphic_LHR 0;
BA_ "GenSigTimeoutTime_CVADAS" SG_ 950 Graphic_LHR 0;
BA_ "GenSigTimeoutTime_EPS" SG_ 950 Graphic_LHR 0;
BA_ "GenSigTimeoutTime_ORC" SG_ 950 Graphic_LHR 0;
BA_ "GenSigTimeoutTime_PAM" SG_ 950 Graphic_LHR 0;
BA_ "GenSigTimeoutTime_SGW" SG_ 950 Graphic_LHR 0;
BA_ "GenSigTimeoutTime_TRSKM" SG_ 950 Graphic_LHR 0;
BA_ "GenSigSendType" SG_ 950 Graphic_RHF 3;
BA_ "GenSigTimeoutTime_BSM2" SG_ 950 Graphic_RHF 0;
BA_ "GenSigTimeoutTime_CADM2" SG_ 950 Graphic_RHF 0;
BA_ "GenSigTimeoutTime_CVADAS" SG_ 950 Graphic_RHF 0;
BA_ "GenSigTimeoutTime_EPS" SG_ 950 Graphic_RHF 0;
BA_ "GenSigTimeoutTime_ORC" SG_ 950 Graphic_RHF 0;
BA_ "GenSigTimeoutTime_PAM" SG_ 950 Graphic_RHF 0;
BA_ "GenSigTimeoutTime_SGW" SG_ 950 Graphic_RHF 0;
BA_ "GenSigTimeoutTime_TRSKM" SG_ 950 Graphic_RHF 0;
BA_ "GenSigSendType" SG_ 950 Graphic_RHR 3;
BA_ "GenSigTimeoutTime_BSM2" SG_ 950 Graphic_RHR 0;
BA_ "GenSigTimeoutTime_CADM2" SG_ 950 Graphic_RHR 0;
BA_ "GenSigTimeoutTime_CVADAS" SG_ 950 Graphic_RHR 0;
BA_ "GenSigTimeoutTime_EPS" SG_ 950 Graphic_RHR 0;
BA_ "GenSigTimeoutTime_ORC" SG_ 950 Graphic_RHR 0;
BA_ "GenSigTimeoutTime_PAM" SG_ 950 Graphic_RHR 0;
BA_ "GenSigTimeoutTime_SGW" SG_ 950 Graphic_RHR 0;
BA_ "GenSigTimeoutTime_TRSKM" SG_ 950 Graphic_RHR 0;
BA_ "GenSigSendType" SG_ 950 HMICode 3;
BA_ "GenSigTimeoutTime_BSM2" SG_ 950 HMICode 0;
BA_ "GenSigTimeoutTime_CADM2" SG_ 950 HMICode 0;
BA_ "GenSigTimeoutTime_CVADAS" SG_ 950 HMICode 0;
BA_ "GenSigTimeoutTime_EPS" SG_ 950 HMICode 0;
BA_ "GenSigTimeoutTime_ORC" SG_ 950 HMICode 0;
BA_ "GenSigTimeoutTime_PAM" SG_ 950 HMICode 0;
BA_ "GenSigTimeoutTime_SGW" SG_ 950 HMICode 0;
BA_ "GenSigTimeoutTime_TRSKM" SG_ 950 HMICode 0;
BA_ "GenSigSendType" SG_ 950 ImageDefeatRQSts 3;
BA_ "GenSigTimeoutTime_BCM" SG_ 950 ImageDefeatRQSts 0;
BA_ "GenSigTimeoutTime_BSM2" SG_ 950 ImageDefeatRQSts 0;
BA_ "GenSigTimeoutTime_CADM2" SG_ 950 ImageDefeatRQSts 0;
BA_ "GenSigTimeoutTime_CVADAS" SG_ 950 ImageDefeatRQSts 0;
BA_ "GenSigTimeoutTime_EPS" SG_ 950 ImageDefeatRQSts 0;
BA_ "GenSigTimeoutTime_ORC" SG_ 950 ImageDefeatRQSts 0;
BA_ "GenSigTimeoutTime_PAM" SG_ 950 ImageDefeatRQSts 0;
BA_ "GenSigTimeoutTime_TRSKM" SG_ 950 ImageDefeatRQSts 0;
BA_ "GenSigTimeoutTime_BSM2" SG_ 950 MessageCounter_CVPAM_FD_Info 0;
BA_ "GenSigTimeoutTime_CADM2" SG_ 950 MessageCounter_CVPAM_FD_Info 0;
BA_ "GenSigTimeoutTime_CVADAS" SG_ 950 MessageCounter_CVPAM_FD_Info 0;
BA_ "GenSigTimeoutTime_EPS" SG_ 950 MessageCounter_CVPAM_FD_Info 0;
BA_ "GenSigTimeoutTime_ORC" SG_ 950 MessageCounter_CVPAM_FD_Info 0;
BA_ "GenSigTimeoutTime_PAM" SG_ 950 MessageCounter_CVPAM_FD_Info 0;
BA_ "GenSigTimeoutTime_SGW" SG_ 950 MessageCounter_CVPAM_FD_Info 0;
BA_ "GenSigSendType" SG_ 950 MoreCamsRQSts 3;
BA_ "GenSigTimeoutTime_BCM" SG_ 950 MoreCamsRQSts 0;
BA_ "GenSigTimeoutTime_BSM2" SG_ 950 MoreCamsRQSts 0;
BA_ "GenSigTimeoutTime_CADM2" SG_ 950 MoreCamsRQSts 0;
BA_ "GenSigTimeoutTime_CVADAS" SG_ 950 MoreCamsRQSts 0;
BA_ "GenSigTimeoutTime_EPS" SG_ 950 MoreCamsRQSts 0;
BA_ "GenSigTimeoutTime_ORC" SG_ 950 MoreCamsRQSts 0;
BA_ "GenSigTimeoutTime_PAM" SG_ 950 MoreCamsRQSts 0;
BA_ "GenSigTimeoutTime_TRSKM" SG_ 950 MoreCamsRQSts 0;
BA_ "GenSigSendType" SG_ 950 PAM_CHIME_REP_RATESts 3;
BA_ "GenSigTimeoutTime_BSM2" SG_ 950 PAM_CHIME_REP_RATESts 0;
BA_ "GenSigTimeoutTime_CADM2" SG_ 950 PAM_CHIME_REP_RATESts 0;
BA_ "GenSigTimeoutTime_CVADAS" SG_ 950 PAM_CHIME_REP_RATESts 0;
BA_ "GenSigTimeoutTime_EPS" SG_ 950 PAM_CHIME_REP_RATESts 0;
BA_ "GenSigTimeoutTime_ORC" SG_ 950 PAM_CHIME_REP_RATESts 0;
BA_ "GenSigTimeoutTime_PAM" SG_ 950 PAM_CHIME_REP_RATESts 0;
BA_ "GenSigTimeoutTime_SGW" SG_ 950 PAM_CHIME_REP_RATESts 0;
BA_ "GenSigTimeoutTime_TRSKM" SG_ 950 PAM_CHIME_REP_RATESts 0;
BA_ "GenSigSendType" SG_ 950 PAM_CHIME_TYPE 3;
BA_ "GenSigTimeoutTime_BSM2" SG_ 950 PAM_CHIME_TYPE 0;
BA_ "GenSigTimeoutTime_CADM2" SG_ 950 PAM_CHIME_TYPE 0;
BA_ "GenSigTimeoutTime_CVADAS" SG_ 950 PAM_CHIME_TYPE 0;
BA_ "GenSigTimeoutTime_EPS" SG_ 950 PAM_CHIME_TYPE 0;
BA_ "GenSigTimeoutTime_ORC" SG_ 950 PAM_CHIME_TYPE 0;
BA_ "GenSigTimeoutTime_PAM" SG_ 950 PAM_CHIME_TYPE 0;
BA_ "GenSigTimeoutTime_SGW" SG_ 950 PAM_CHIME_TYPE 0;
BA_ "GenSigTimeoutTime_TRSKM" SG_ 950 PAM_CHIME_TYPE 0;
BA_ "GenSigSendType" SG_ 950 PAM_LedControlSts 3;
BA_ "GenSigTimeoutTime_BSM2" SG_ 950 PAM_LedControlSts 0;
BA_ "GenSigTimeoutTime_CADM2" SG_ 950 PAM_LedControlSts 0;
BA_ "GenSigTimeoutTime_CVADAS" SG_ 950 PAM_LedControlSts 0;
BA_ "GenSigTimeoutTime_EPS" SG_ 950 PAM_LedControlSts 0;
BA_ "GenSigTimeoutTime_ORC" SG_ 950 PAM_LedControlSts 0;
BA_ "GenSigTimeoutTime_PAM" SG_ 950 PAM_LedControlSts 0;
BA_ "GenSigTimeoutTime_SGW" SG_ 950 PAM_LedControlSts 0;
BA_ "GenSigTimeoutTime_TRSKM" SG_ 950 PAM_LedControlSts 0;
BA_ "GenSigSendType" SG_ 950 PAM_Off_Status 3;
BA_ "GenSigTimeoutTime_BCM" SG_ 950 PAM_Off_Status 0;
BA_ "GenSigTimeoutTime_BSM2" SG_ 950 PAM_Off_Status 0;
BA_ "GenSigTimeoutTime_CADM2" SG_ 950 PAM_Off_Status 0;
BA_ "GenSigTimeoutTime_CVADAS" SG_ 950 PAM_Off_Status 0;
BA_ "GenSigTimeoutTime_EPS" SG_ 950 PAM_Off_Status 0;
BA_ "GenSigTimeoutTime_ORC" SG_ 950 PAM_Off_Status 0;
BA_ "GenSigTimeoutTime_PAM" SG_ 950 PAM_Off_Status 0;
BA_ "GenSigTimeoutTime_TRSKM" SG_ 950 PAM_Off_Status 0;
BA_ "GenSigSendType" SG_ 950 PAM_Off_Status_2BT 3;
BA_ "GenSigTimeoutTime_BSM2" SG_ 950 PAM_Off_Status_2BT 0;
BA_ "GenSigTimeoutTime_CADM2" SG_ 950 PAM_Off_Status_2BT 0;
BA_ "GenSigTimeoutTime_CVADAS" SG_ 950 PAM_Off_Status_2BT 0;
BA_ "GenSigTimeoutTime_EPS" SG_ 950 PAM_Off_Status_2BT 0;
BA_ "GenSigTimeoutTime_ORC" SG_ 950 PAM_Off_Status_2BT 0;
BA_ "GenSigTimeoutTime_PAM" SG_ 950 PAM_Off_Status_2BT 0;
BA_ "GenSigTimeoutTime_TRSKM" SG_ 950 PAM_Off_Status_2BT 0;
BA_ "GenSigSendType" SG_ 950 PAM_PopUpRqst 3;
BA_ "GenSigTimeoutTime_BSM2" SG_ 950 PAM_PopUpRqst 0;
BA_ "GenSigTimeoutTime_CADM2" SG_ 950 PAM_PopUpRqst 0;
BA_ "GenSigTimeoutTime_CVADAS" SG_ 950 PAM_PopUpRqst 0;
BA_ "GenSigTimeoutTime_EPS" SG_ 950 PAM_PopUpRqst 0;
BA_ "GenSigTimeoutTime_ORC" SG_ 950 PAM_PopUpRqst 0;
BA_ "GenSigTimeoutTime_PAM" SG_ 950 PAM_PopUpRqst 0;
BA_ "GenSigTimeoutTime_SGW" SG_ 950 PAM_PopUpRqst 0;
BA_ "GenSigTimeoutTime_TRSKM" SG_ 950 PAM_PopUpRqst 0;
BA_ "GenSigSendType" SG_ 950 PAM_Volume 3;
BA_ "GenSigTimeoutTime_BSM2" SG_ 950 PAM_Volume 0;
BA_ "GenSigTimeoutTime_CADM2" SG_ 950 PAM_Volume 0;
BA_ "GenSigTimeoutTime_CVADAS" SG_ 950 PAM_Volume 0;
BA_ "GenSigTimeoutTime_EPS" SG_ 950 PAM_Volume 0;
BA_ "GenSigTimeoutTime_ORC" SG_ 950 PAM_Volume 0;
BA_ "GenSigTimeoutTime_PAM" SG_ 950 PAM_Volume 0;
BA_ "GenSigTimeoutTime_SGW" SG_ 950 PAM_Volume 0;
BA_ "GenSigTimeoutTime_TRSKM" SG_ 950 PAM_Volume 0;
BA_ "GenSigSendType" SG_ 950 PAMSystemFault 3;
BA_ "GenSigTimeoutTime_BSM2" SG_ 950 PAMSystemFault 0;
BA_ "GenSigTimeoutTime_CADM2" SG_ 950 PAMSystemFault 0;
BA_ "GenSigTimeoutTime_CVADAS" SG_ 950 PAMSystemFault 0;
BA_ "GenSigTimeoutTime_EPS" SG_ 950 PAMSystemFault 0;
BA_ "GenSigTimeoutTime_ORC" SG_ 950 PAMSystemFault 0;
BA_ "GenSigTimeoutTime_PAM" SG_ 950 PAMSystemFault 0;
BA_ "GenSigTimeoutTime_SGW" SG_ 950 PAMSystemFault 0;
BA_ "GenSigTimeoutTime_TRSKM" SG_ 950 PAMSystemFault 0;
BA_ "GenSigSendType" SG_ 950 ParkingManeuverActive 3;
BA_ "GenSigTimeoutTime_BSM2" SG_ 950 ParkingManeuverActive 0;
BA_ "GenSigTimeoutTime_CADM2" SG_ 950 ParkingManeuverActive 0;
BA_ "GenSigTimeoutTime_CVADAS" SG_ 950 ParkingManeuverActive 0;
BA_ "GenSigTimeoutTime_EPS" SG_ 950 ParkingManeuverActive 0;
BA_ "GenSigTimeoutTime_ORC" SG_ 950 ParkingManeuverActive 0;
BA_ "GenSigTimeoutTime_PAM" SG_ 950 ParkingManeuverActive 0;
BA_ "GenSigTimeoutTime_SGW" SG_ 950 ParkingManeuverActive 0;
BA_ "GenSigTimeoutTime_TRSKM" SG_ 950 ParkingManeuverActive 0;
BA_ "GenSigSendType" SG_ 950 RearSensorSts 3;
BA_ "GenSigTimeoutTime_BSM2" SG_ 950 RearSensorSts 0;
BA_ "GenSigTimeoutTime_CADM2" SG_ 950 RearSensorSts 0;
BA_ "GenSigTimeoutTime_CVADAS" SG_ 950 RearSensorSts 0;
BA_ "GenSigTimeoutTime_EPS" SG_ 950 RearSensorSts 0;
BA_ "GenSigTimeoutTime_ORC" SG_ 950 RearSensorSts 0;
BA_ "GenSigTimeoutTime_PAM" SG_ 950 RearSensorSts 0;
BA_ "GenSigTimeoutTime_TRSKM" SG_ 950 RearSensorSts 0;
BA_ "GenSigSendType" SG_ 950 SPM_LedControlSts 3;
BA_ "GenSigTimeoutTime_BSM2" SG_ 950 SPM_LedControlSts 0;
BA_ "GenSigTimeoutTime_CADM2" SG_ 950 SPM_LedControlSts 0;
BA_ "GenSigTimeoutTime_CVADAS" SG_ 950 SPM_LedControlSts 0;
BA_ "GenSigTimeoutTime_EPS" SG_ 950 SPM_LedControlSts 0;
BA_ "GenSigTimeoutTime_PAM" SG_ 950 SPM_LedControlSts 0;
BA_ "GenSigTimeoutTime_SGW" SG_ 950 SPM_LedControlSts 0;
BA_ "GenSigTimeoutTime_TRSKM" SG_ 950 SPM_LedControlSts 0;
BA_ "GenSigSendType" SG_ 950 SPM_Screen_Rqst 3;
BA_ "GenSigTimeoutTime_BCM" SG_ 950 SPM_Screen_Rqst 0;
BA_ "GenSigTimeoutTime_BSM2" SG_ 950 SPM_Screen_Rqst 0;
BA_ "GenSigTimeoutTime_CADM2" SG_ 950 SPM_Screen_Rqst 0;
BA_ "GenSigTimeoutTime_CVADAS" SG_ 950 SPM_Screen_Rqst 0;
BA_ "GenSigTimeoutTime_EPS" SG_ 950 SPM_Screen_Rqst 0;
BA_ "GenSigTimeoutTime_ORC" SG_ 950 SPM_Screen_Rqst 0;
BA_ "GenSigTimeoutTime_PAM" SG_ 950 SPM_Screen_Rqst 0;
BA_ "GenSigTimeoutTime_TRSKM" SG_ 950 SPM_Screen_Rqst 0;
BA_ "GenSigSendType" SG_ 950 SPMControlSts 3;
BA_ "GenSigTimeoutTime_BSM2" SG_ 950 SPMControlSts 0;
BA_ "GenSigTimeoutTime_CADM2" SG_ 950 SPMControlSts 0;
BA_ "GenSigTimeoutTime_CVADAS" SG_ 950 SPMControlSts 0;
BA_ "GenSigTimeoutTime_EPS" SG_ 950 SPMControlSts 0;
BA_ "GenSigTimeoutTime_PAM" SG_ 950 SPMControlSts 0;
BA_ "GenSigTimeoutTime_TRSKM" SG_ 950 SPMControlSts 0;
BA_ "GenSigSendType" SG_ 950 SPMFailSts 3;
BA_ "GenSigTimeoutTime_BCM" SG_ 950 SPMFailSts 0;
BA_ "GenSigTimeoutTime_BSM2" SG_ 950 SPMFailSts 0;
BA_ "GenSigTimeoutTime_CADM2" SG_ 950 SPMFailSts 0;
BA_ "GenSigTimeoutTime_CVADAS" SG_ 950 SPMFailSts 0;
BA_ "GenSigTimeoutTime_EPS" SG_ 950 SPMFailSts 0;
BA_ "GenSigTimeoutTime_PAM" SG_ 950 SPMFailSts 0;
BA_ "GenSigTimeoutTime_SGW" SG_ 950 SPMFailSts 0;
BA_ "GenSigTimeoutTime_TRSKM" SG_ 950 SPMFailSts 0;
BA_ "GenSigSendType" SG_ 950 SPMSystemFault 3;
BA_ "GenSigTimeoutTime_BCM" SG_ 950 SPMSystemFault 0;
BA_ "GenSigTimeoutTime_BSM2" SG_ 950 SPMSystemFault 0;
BA_ "GenSigTimeoutTime_CADM2" SG_ 950 SPMSystemFault 0;
BA_ "GenSigTimeoutTime_CVADAS" SG_ 950 SPMSystemFault 0;
BA_ "GenSigTimeoutTime_EPS" SG_ 950 SPMSystemFault 0;
BA_ "GenSigTimeoutTime_ORC" SG_ 950 SPMSystemFault 0;
BA_ "GenSigTimeoutTime_PAM" SG_ 950 SPMSystemFault 0;
BA_ "GenSigTimeoutTime_SGW" SG_ 950 SPMSystemFault 0;
BA_ "GenSigTimeoutTime_TRSKM" SG_ 950 SPMSystemFault 0;
BA_ "GenSigTimeoutTime_BCM" SG_ 950 TRSC_LED_Stat 0;
BA_ "GenSigTimeoutTime_BSM2" SG_ 950 TRSC_LED_Stat 0;
BA_ "GenSigTimeoutTime_CADM2" SG_ 950 TRSC_LED_Stat 0;
BA_ "GenSigTimeoutTime_CVADAS" SG_ 950 TRSC_LED_Stat 0;
BA_ "GenSigTimeoutTime_EPS" SG_ 950 TRSC_LED_Stat 0;
BA_ "GenSigTimeoutTime_ORC" SG_ 950 TRSC_LED_Stat 0;
BA_ "GenSigTimeoutTime_PAM" SG_ 950 TRSC_LED_Stat 0;
BA_ "GenSigTimeoutTime_SGW" SG_ 950 TRSC_LED_Stat 0;
BA_ "GenSigStartValue" SG_ 161 BATTERY_voltage 255;
BA_ "GenSigTimeoutTime_BCM" SG_ 161 BATTERY_voltage 0;
BA_ "GenSigTimeoutTime_BSM2" SG_ 161 BATTERY_voltage 0;
BA_ "GenSigTimeoutTime_CADM2" SG_ 161 BATTERY_voltage 0;
BA_ "GenSigTimeoutTime_CVADAS" SG_ 161 BATTERY_voltage 0;
BA_ "GenSigTimeoutTime_EPS" SG_ 161 BATTERY_voltage 0;
BA_ "GenSigTimeoutTime_ORC" SG_ 161 BATTERY_voltage 0;
BA_ "GenSigTimeoutTime_PAM" SG_ 161 BATTERY_voltage 0;
BA_ "GenSigTimeoutTime_SGW" SG_ 161 BATTERY_voltage 0;
BA_ "GenSigTimeoutTime_TRSKM" SG_ 161 BATTERY_voltage 0;
BA_ "GenSigStartValue" SG_ 161 BATTERY2_voltage 255;
BA_ "GenSigTimeoutTime_BCM" SG_ 161 BATTERY2_voltage 0;
BA_ "GenSigTimeoutTime_BSM2" SG_ 161 BATTERY2_voltage 0;
BA_ "GenSigTimeoutTime_CADM2" SG_ 161 BATTERY2_voltage 0;
BA_ "GenSigTimeoutTime_CVADAS" SG_ 161 BATTERY2_voltage 0;
BA_ "GenSigTimeoutTime_EPS" SG_ 161 BATTERY2_voltage 0;
BA_ "GenSigTimeoutTime_ORC" SG_ 161 BATTERY2_voltage 0;
BA_ "GenSigTimeoutTime_PAM" SG_ 161 BATTERY2_voltage 0;
BA_ "GenSigTimeoutTime_SGW" SG_ 161 BATTERY2_voltage 0;
BA_ "GenSigTimeoutTime_TRSKM" SG_ 161 BATTERY2_voltage 0;
BA_ "GenSigStartValue" SG_ 161 CRC_DBSM2_1 255;
BA_ "GenSigSendType" SG_ 161 CRC_DBSM2_1 1;
BA_ "GenSigTimeoutTime_BCM" SG_ 161 CRC_DBSM2_1 0;
BA_ "GenSigTimeoutTime_BSM2" SG_ 161 CRC_DBSM2_1 0;
BA_ "GenSigTimeoutTime_CVADAS" SG_ 161 CRC_DBSM2_1 0;
BA_ "GenSigTimeoutTime_EPS" SG_ 161 CRC_DBSM2_1 0;
BA_ "GenSigTimeoutTime_ORC" SG_ 161 CRC_DBSM2_1 0;
BA_ "GenSigTimeoutTime_PAM" SG_ 161 CRC_DBSM2_1 0;
BA_ "GenSigTimeoutTime_SGW" SG_ 161 CRC_DBSM2_1 0;
BA_ "GenSigTimeoutTime_TRSKM" SG_ 161 CRC_DBSM2_1 0;
BA_ "GenSigTimeoutTime_BCM" SG_ 161 DBSM2_internal_error 0;
BA_ "GenSigTimeoutTime_BSM2" SG_ 161 DBSM2_internal_error 0;
BA_ "GenSigTimeoutTime_CVADAS" SG_ 161 DBSM2_internal_error 0;
BA_ "GenSigTimeoutTime_EPS" SG_ 161 DBSM2_internal_error 0;
BA_ "GenSigTimeoutTime_ORC" SG_ 161 DBSM2_internal_error 0;
BA_ "GenSigTimeoutTime_PAM" SG_ 161 DBSM2_internal_error 0;
BA_ "GenSigTimeoutTime_SGW" SG_ 161 DBSM2_internal_error 0;
BA_ "GenSigTimeoutTime_TRSKM" SG_ 161 DBSM2_internal_error 0;
BA_ "GenSigTimeoutTime_BCM" SG_ 161 ESS_input_active 0;
BA_ "GenSigTimeoutTime_BSM2" SG_ 161 ESS_input_active 0;
BA_ "GenSigTimeoutTime_CADM2" SG_ 161 ESS_input_active 0;
BA_ "GenSigTimeoutTime_CVADAS" SG_ 161 ESS_input_active 0;
BA_ "GenSigTimeoutTime_EPS" SG_ 161 ESS_input_active 0;
BA_ "GenSigTimeoutTime_ORC" SG_ 161 ESS_input_active 0;
BA_ "GenSigTimeoutTime_PAM" SG_ 161 ESS_input_active 0;
BA_ "GenSigTimeoutTime_SGW" SG_ 161 ESS_input_active 0;
BA_ "GenSigTimeoutTime_TRSKM" SG_ 161 ESS_input_active 0;
BA_ "GenSigTimeoutTime_BCM" SG_ 161 L2plus_ack 0;
BA_ "GenSigTimeoutTime_BSM2" SG_ 161 L2plus_ack 0;
BA_ "GenSigTimeoutTime_CADM2" SG_ 161 L2plus_ack 0;
BA_ "GenSigTimeoutTime_CVADAS" SG_ 161 L2plus_ack 0;
BA_ "GenSigTimeoutTime_EPS" SG_ 161 L2plus_ack 0;
BA_ "GenSigTimeoutTime_ORC" SG_ 161 L2plus_ack 0;
BA_ "GenSigTimeoutTime_PAM" SG_ 161 L2plus_ack 0;
BA_ "GenSigTimeoutTime_SGW" SG_ 161 L2plus_ack 0;
BA_ "GenSigTimeoutTime_TRSKM" SG_ 161 L2plus_ack 0;
BA_ "GenSigTimeoutTime_BCM" SG_ 161 MC_DBSM2_1 0;
BA_ "GenSigTimeoutTime_BSM2" SG_ 161 MC_DBSM2_1 0;
BA_ "GenSigTimeoutTime_CVADAS" SG_ 161 MC_DBSM2_1 0;
BA_ "GenSigTimeoutTime_EPS" SG_ 161 MC_DBSM2_1 0;
BA_ "GenSigTimeoutTime_ORC" SG_ 161 MC_DBSM2_1 0;
BA_ "GenSigTimeoutTime_PAM" SG_ 161 MC_DBSM2_1 0;
BA_ "GenSigTimeoutTime_SGW" SG_ 161 MC_DBSM2_1 0;
BA_ "GenSigTimeoutTime_TRSKM" SG_ 161 MC_DBSM2_1 0;
BA_ "GenSigTimeoutTime_BCM" SG_ 161 overcurrent_detected 0;
BA_ "GenSigTimeoutTime_BSM2" SG_ 161 overcurrent_detected 0;
BA_ "GenSigTimeoutTime_CVADAS" SG_ 161 overcurrent_detected 0;
BA_ "GenSigTimeoutTime_EPS" SG_ 161 overcurrent_detected 0;
BA_ "GenSigTimeoutTime_ORC" SG_ 161 overcurrent_detected 0;
BA_ "GenSigTimeoutTime_PAM" SG_ 161 overcurrent_detected 0;
BA_ "GenSigTimeoutTime_SGW" SG_ 161 overcurrent_detected 0;
BA_ "GenSigTimeoutTime_TRSKM" SG_ 161 overcurrent_detected 0;
BA_ "GenSigTimeoutTime_BCM" SG_ 161 overtemp_detected 0;
BA_ "GenSigTimeoutTime_BSM2" SG_ 161 overtemp_detected 0;
BA_ "GenSigTimeoutTime_CVADAS" SG_ 161 overtemp_detected 0;
BA_ "GenSigTimeoutTime_EPS" SG_ 161 overtemp_detected 0;
BA_ "GenSigTimeoutTime_ORC" SG_ 161 overtemp_detected 0;
BA_ "GenSigTimeoutTime_PAM" SG_ 161 overtemp_detected 0;
BA_ "GenSigTimeoutTime_SGW" SG_ 161 overtemp_detected 0;
BA_ "GenSigTimeoutTime_TRSKM" SG_ 161 overtemp_detected 0;
BA_ "GenSigTimeoutTime_BCM" SG_ 161 RsErr_DBSM2 0;
BA_ "GenSigTimeoutTime_BSM2" SG_ 161 RsErr_DBSM2 0;
BA_ "GenSigTimeoutTime_CVADAS" SG_ 161 RsErr_DBSM2 0;
BA_ "GenSigTimeoutTime_EPS" SG_ 161 RsErr_DBSM2 0;
BA_ "GenSigTimeoutTime_ORC" SG_ 161 RsErr_DBSM2 0;
BA_ "GenSigTimeoutTime_PAM" SG_ 161 RsErr_DBSM2 0;
BA_ "GenSigTimeoutTime_SGW" SG_ 161 RsErr_DBSM2 0;
BA_ "GenSigTimeoutTime_TRSKM" SG_ 161 RsErr_DBSM2 0;
BA_ "GenSigTimeoutTime_BCM" SG_ 161 switch_status_OpenClose 0;
BA_ "GenSigTimeoutTime_BSM2" SG_ 161 switch_status_OpenClose 0;
BA_ "GenSigTimeoutTime_CVADAS" SG_ 161 switch_status_OpenClose 0;
BA_ "GenSigTimeoutTime_EPS" SG_ 161 switch_status_OpenClose 0;
BA_ "GenSigTimeoutTime_ORC" SG_ 161 switch_status_OpenClose 0;
BA_ "GenSigTimeoutTime_PAM" SG_ 161 switch_status_OpenClose 0;
BA_ "GenSigTimeoutTime_SGW" SG_ 161 switch_status_OpenClose 0;
BA_ "GenSigTimeoutTime_TRSKM" SG_ 161 switch_status_OpenClose 0;
BA_ "GenSigTimeoutTime_BCM" SG_ 161 undervoltage_detected 0;
BA_ "GenSigTimeoutTime_BSM2" SG_ 161 undervoltage_detected 0;
BA_ "GenSigTimeoutTime_CVADAS" SG_ 161 undervoltage_detected 0;
BA_ "GenSigTimeoutTime_EPS" SG_ 161 undervoltage_detected 0;
BA_ "GenSigTimeoutTime_ORC" SG_ 161 undervoltage_detected 0;
BA_ "GenSigTimeoutTime_PAM" SG_ 161 undervoltage_detected 0;
BA_ "GenSigTimeoutTime_SGW" SG_ 161 undervoltage_detected 0;
BA_ "GenSigTimeoutTime_TRSKM" SG_ 161 undervoltage_detected 0;
BA_ "GenSigTimeoutTime_BCM" SG_ 2564432881 N_PDU 0;
BA_ "GenSigTimeoutTime_BSM2" SG_ 2564432881 N_PDU 0;
BA_ "GenSigTimeoutTime_CADM2" SG_ 2564432881 N_PDU 0;
BA_ "GenSigTimeoutTime_CVADAS" SG_ 2564432881 N_PDU 0;
BA_ "GenSigTimeoutTime_EPS" SG_ 2564432881 N_PDU 0;
BA_ "GenSigTimeoutTime_ORC" SG_ 2564432881 N_PDU 0;
BA_ "GenSigTimeoutTime_PAM" SG_ 2564432881 N_PDU 0;
BA_ "GenSigTimeoutTime_SGW" SG_ 2564432881 N_PDU 0;
BA_ "GenSigTimeoutTime_TRSKM" SG_ 2564432881 N_PDU 0;
BA_ "GenSigTimeoutTime_BCM" SG_ 2564435953 N_PDU 0;
BA_ "GenSigTimeoutTime_BSM2" SG_ 2564435953 N_PDU 0;
BA_ "GenSigTimeoutTime_CADM2" SG_ 2564435953 N_PDU 0;
BA_ "GenSigTimeoutTime_CVADAS" SG_ 2564435953 N_PDU 0;
BA_ "GenSigTimeoutTime_EPS" SG_ 2564435953 N_PDU 0;
BA_ "GenSigTimeoutTime_ORC" SG_ 2564435953 N_PDU 0;
BA_ "GenSigTimeoutTime_PAM" SG_ 2564435953 N_PDU 0;
BA_ "GenSigTimeoutTime_SGW" SG_ 2564435953 N_PDU 0;
BA_ "GenSigTimeoutTime_TRSKM" SG_ 2564435953 N_PDU 0;
BA_ "GenSigTimeoutTime_BCM" SG_ 2564436209 N_PDU 0;
BA_ "GenSigTimeoutTime_BSM2" SG_ 2564436209 N_PDU 0;
BA_ "GenSigTimeoutTime_CADM2" SG_ 2564436209 N_PDU 0;
BA_ "GenSigTimeoutTime_CVADAS" SG_ 2564436209 N_PDU 0;
BA_ "GenSigTimeoutTime_EPS" SG_ 2564436209 N_PDU 0;
BA_ "GenSigTimeoutTime_ORC" SG_ 2564436209 N_PDU 0;
BA_ "GenSigTimeoutTime_PAM" SG_ 2564436209 N_PDU 0;
BA_ "GenSigTimeoutTime_SGW" SG_ 2564436209 N_PDU 0;
BA_ "GenSigTimeoutTime_TRSKM" SG_ 2564436209 N_PDU 0;
BA_ "GenSigTimeoutTime_BCM" SG_ 2564432882 N_PDU 0;
BA_ "GenSigTimeoutTime_BSM2" SG_ 2564432882 N_PDU 0;
BA_ "GenSigTimeoutTime_CADM2" SG_ 2564432882 N_PDU 0;
BA_ "GenSigTimeoutTime_CVADAS" SG_ 2564432882 N_PDU 0;
BA_ "GenSigTimeoutTime_EPS" SG_ 2564432882 N_PDU 0;
BA_ "GenSigTimeoutTime_ORC" SG_ 2564432882 N_PDU 0;
BA_ "GenSigTimeoutTime_PAM" SG_ 2564432882 N_PDU 0;
BA_ "GenSigTimeoutTime_SGW" SG_ 2564432882 N_PDU 0;
BA_ "GenSigTimeoutTime_TRSKM" SG_ 2564432882 N_PDU 0;
BA_ "GenSigTimeoutTime_BCM" SG_ 2564435954 N_PDU 0;
BA_ "GenSigTimeoutTime_BSM2" SG_ 2564435954 N_PDU 0;
BA_ "GenSigTimeoutTime_CADM2" SG_ 2564435954 N_PDU 0;
BA_ "GenSigTimeoutTime_CVADAS" SG_ 2564435954 N_PDU 0;
BA_ "GenSigTimeoutTime_EPS" SG_ 2564435954 N_PDU 0;
BA_ "GenSigTimeoutTime_ORC" SG_ 2564435954 N_PDU 0;
BA_ "GenSigTimeoutTime_PAM" SG_ 2564435954 N_PDU 0;
BA_ "GenSigTimeoutTime_SGW" SG_ 2564435954 N_PDU 0;
BA_ "GenSigTimeoutTime_TRSKM" SG_ 2564435954 N_PDU 0;
BA_ "GenSigTimeoutTime_BCM" SG_ 2564436210 N_PDU 0;
BA_ "GenSigTimeoutTime_BSM2" SG_ 2564436210 N_PDU 0;
BA_ "GenSigTimeoutTime_CADM2" SG_ 2564436210 N_PDU 0;
BA_ "GenSigTimeoutTime_CVADAS" SG_ 2564436210 N_PDU 0;
BA_ "GenSigTimeoutTime_EPS" SG_ 2564436210 N_PDU 0;
BA_ "GenSigTimeoutTime_ORC" SG_ 2564436210 N_PDU 0;
BA_ "GenSigTimeoutTime_PAM" SG_ 2564436210 N_PDU 0;
BA_ "GenSigTimeoutTime_SGW" SG_ 2564436210 N_PDU 0;
BA_ "GenSigTimeoutTime_TRSKM" SG_ 2564436210 N_PDU 0;
BA_ "GenSigTimeoutTime_BCM" SG_ 2564554482 N_PDU 0;
BA_ "GenSigTimeoutTime_BSM2" SG_ 2564554482 N_PDU 0;
BA_ "GenSigTimeoutTime_CADM2" SG_ 2564554482 N_PDU 0;
BA_ "GenSigTimeoutTime_CVADAS" SG_ 2564554482 N_PDU 0;
BA_ "GenSigTimeoutTime_EPS" SG_ 2564554482 N_PDU 0;
BA_ "GenSigTimeoutTime_ORC" SG_ 2564554482 N_PDU 0;
BA_ "GenSigTimeoutTime_PAM" SG_ 2564554482 N_PDU 0;
BA_ "GenSigTimeoutTime_SGW" SG_ 2564554482 N_PDU 0;
BA_ "GenSigTimeoutTime_TRSKM" SG_ 2564554482 N_PDU 0;
BA_ "GenSigTimeoutTime_BCM" SG_ 2564473074 N_PDU 0;
BA_ "GenSigTimeoutTime_BSM2" SG_ 2564473074 N_PDU 0;
BA_ "GenSigTimeoutTime_CADM2" SG_ 2564473074 N_PDU 0;
BA_ "GenSigTimeoutTime_CVADAS" SG_ 2564473074 N_PDU 0;
BA_ "GenSigTimeoutTime_EPS" SG_ 2564473074 N_PDU 0;
BA_ "GenSigTimeoutTime_ORC" SG_ 2564473074 N_PDU 0;
BA_ "GenSigTimeoutTime_PAM" SG_ 2564473074 N_PDU 0;
BA_ "GenSigTimeoutTime_SGW" SG_ 2564473074 N_PDU 0;
BA_ "GenSigTimeoutTime_TRSKM" SG_ 2564473074 N_PDU 0;
BA_ "GenSigTimeoutTime_BCM" SG_ 2564464882 N_PDU 0;
BA_ "GenSigTimeoutTime_BSM2" SG_ 2564464882 N_PDU 0;
BA_ "GenSigTimeoutTime_CADM2" SG_ 2564464882 N_PDU 0;
BA_ "GenSigTimeoutTime_CVADAS" SG_ 2564464882 N_PDU 0;
BA_ "GenSigTimeoutTime_EPS" SG_ 2564464882 N_PDU 0;
BA_ "GenSigTimeoutTime_ORC" SG_ 2564464882 N_PDU 0;
BA_ "GenSigTimeoutTime_PAM" SG_ 2564464882 N_PDU 0;
BA_ "GenSigTimeoutTime_SGW" SG_ 2564464882 N_PDU 0;
BA_ "GenSigTimeoutTime_TRSKM" SG_ 2564464882 N_PDU 0;
BA_ "GenSigTimeoutTime_BCM" SG_ 2564484338 N_PDU 0;
BA_ "GenSigTimeoutTime_BSM2" SG_ 2564484338 N_PDU 0;
BA_ "GenSigTimeoutTime_CADM2" SG_ 2564484338 N_PDU 0;
BA_ "GenSigTimeoutTime_CVADAS" SG_ 2564484338 N_PDU 0;
BA_ "GenSigTimeoutTime_EPS" SG_ 2564484338 N_PDU 0;
BA_ "GenSigTimeoutTime_ORC" SG_ 2564484338 N_PDU 0;
BA_ "GenSigTimeoutTime_PAM" SG_ 2564484338 N_PDU 0;
BA_ "GenSigTimeoutTime_SGW" SG_ 2564484338 N_PDU 0;
BA_ "GenSigTimeoutTime_TRSKM" SG_ 2564484338 N_PDU 0;
BA_ "GenSigTimeoutTime_BCM" SG_ 2564435957 N_PDU 0;
BA_ "GenSigTimeoutTime_BSM2" SG_ 2564435957 N_PDU 0;
BA_ "GenSigTimeoutTime_CADM2" SG_ 2564435957 N_PDU 0;
BA_ "GenSigTimeoutTime_CVADAS" SG_ 2564435957 N_PDU 0;
BA_ "GenSigTimeoutTime_EPS" SG_ 2564435957 N_PDU 0;
BA_ "GenSigTimeoutTime_ORC" SG_ 2564435957 N_PDU 0;
BA_ "GenSigTimeoutTime_PAM" SG_ 2564435957 N_PDU 0;
BA_ "GenSigTimeoutTime_SGW" SG_ 2564435957 N_PDU 0;
BA_ "GenSigTimeoutTime_TRSKM" SG_ 2564435957 N_PDU 0;
BA_ "GenSigTimeoutTime_BCM" SG_ 2564436213 N_PDU 0;
BA_ "GenSigTimeoutTime_BSM2" SG_ 2564436213 N_PDU 0;
BA_ "GenSigTimeoutTime_CADM2" SG_ 2564436213 N_PDU 0;
BA_ "GenSigTimeoutTime_CVADAS" SG_ 2564436213 N_PDU 0;
BA_ "GenSigTimeoutTime_EPS" SG_ 2564436213 N_PDU 0;
BA_ "GenSigTimeoutTime_ORC" SG_ 2564436213 N_PDU 0;
BA_ "GenSigTimeoutTime_PAM" SG_ 2564436213 N_PDU 0;
BA_ "GenSigTimeoutTime_SGW" SG_ 2564436213 N_PDU 0;
BA_ "GenSigTimeoutTime_TRSKM" SG_ 2564436213 N_PDU 0;
BA_ "GenSigTimeoutTime_BCM" SG_ 2564473077 N_PDU 0;
BA_ "GenSigTimeoutTime_BSM2" SG_ 2564473077 N_PDU 0;
BA_ "GenSigTimeoutTime_CADM2" SG_ 2564473077 N_PDU 0;
BA_ "GenSigTimeoutTime_CVADAS" SG_ 2564473077 N_PDU 0;
BA_ "GenSigTimeoutTime_EPS" SG_ 2564473077 N_PDU 0;
BA_ "GenSigTimeoutTime_ORC" SG_ 2564473077 N_PDU 0;
BA_ "GenSigTimeoutTime_PAM" SG_ 2564473077 N_PDU 0;
BA_ "GenSigTimeoutTime_SGW" SG_ 2564473077 N_PDU 0;
BA_ "GenSigTimeoutTime_TRSKM" SG_ 2564473077 N_PDU 0;
BA_ "GenSigTimeoutTime_BCM" SG_ 2564554485 N_PDU 0;
BA_ "GenSigTimeoutTime_BSM2" SG_ 2564554485 N_PDU 0;
BA_ "GenSigTimeoutTime_CADM2" SG_ 2564554485 N_PDU 0;
BA_ "GenSigTimeoutTime_CVADAS" SG_ 2564554485 N_PDU 0;
BA_ "GenSigTimeoutTime_EPS" SG_ 2564554485 N_PDU 0;
BA_ "GenSigTimeoutTime_ORC" SG_ 2564554485 N_PDU 0;
BA_ "GenSigTimeoutTime_PAM" SG_ 2564554485 N_PDU 0;
BA_ "GenSigTimeoutTime_SGW" SG_ 2564554485 N_PDU 0;
BA_ "GenSigTimeoutTime_TRSKM" SG_ 2564554485 N_PDU 0;
BA_ "GenSigTimeoutTime_BCM" SG_ 2564502513 N_PDU 0;
BA_ "GenSigTimeoutTime_BSM2" SG_ 2564502513 N_PDU 0;
BA_ "GenSigTimeoutTime_CADM2" SG_ 2564502513 N_PDU 0;
BA_ "GenSigTimeoutTime_CVADAS" SG_ 2564502513 N_PDU 0;
BA_ "GenSigTimeoutTime_EPS" SG_ 2564502513 N_PDU 0;
BA_ "GenSigTimeoutTime_ORC" SG_ 2564502513 N_PDU 0;
BA_ "GenSigTimeoutTime_PAM" SG_ 2564502513 N_PDU 0;
BA_ "GenSigTimeoutTime_SGW" SG_ 2564502513 N_PDU 0;
BA_ "GenSigTimeoutTime_TRSKM" SG_ 2564502513 N_PDU 0;
BA_ "GenSigTimeoutTime_BCM" SG_ 2564554481 N_PDU 0;
BA_ "GenSigTimeoutTime_BSM2" SG_ 2564554481 N_PDU 0;
BA_ "GenSigTimeoutTime_CADM2" SG_ 2564554481 N_PDU 0;
BA_ "GenSigTimeoutTime_CVADAS" SG_ 2564554481 N_PDU 0;
BA_ "GenSigTimeoutTime_EPS" SG_ 2564554481 N_PDU 0;
BA_ "GenSigTimeoutTime_ORC" SG_ 2564554481 N_PDU 0;
BA_ "GenSigTimeoutTime_PAM" SG_ 2564554481 N_PDU 0;
BA_ "GenSigTimeoutTime_SGW" SG_ 2564554481 N_PDU 0;
BA_ "GenSigTimeoutTime_TRSKM" SG_ 2564554481 N_PDU 0;
BA_ "GenSigTimeoutTime_BCM" SG_ 2564473073 N_PDU 0;
BA_ "GenSigTimeoutTime_BSM2" SG_ 2564473073 N_PDU 0;
BA_ "GenSigTimeoutTime_CADM2" SG_ 2564473073 N_PDU 0;
BA_ "GenSigTimeoutTime_CVADAS" SG_ 2564473073 N_PDU 0;
BA_ "GenSigTimeoutTime_EPS" SG_ 2564473073 N_PDU 0;
BA_ "GenSigTimeoutTime_ORC" SG_ 2564473073 N_PDU 0;
BA_ "GenSigTimeoutTime_PAM" SG_ 2564473073 N_PDU 0;
BA_ "GenSigTimeoutTime_SGW" SG_ 2564473073 N_PDU 0;
BA_ "GenSigTimeoutTime_TRSKM" SG_ 2564473073 N_PDU 0;
BA_ "GenSigTimeoutTime_BCM" SG_ 2564464881 N_PDU 0;
BA_ "GenSigTimeoutTime_BSM2" SG_ 2564464881 N_PDU 0;
BA_ "GenSigTimeoutTime_CADM2" SG_ 2564464881 N_PDU 0;
BA_ "GenSigTimeoutTime_CVADAS" SG_ 2564464881 N_PDU 0;
BA_ "GenSigTimeoutTime_EPS" SG_ 2564464881 N_PDU 0;
BA_ "GenSigTimeoutTime_ORC" SG_ 2564464881 N_PDU 0;
BA_ "GenSigTimeoutTime_PAM" SG_ 2564464881 N_PDU 0;
BA_ "GenSigTimeoutTime_SGW" SG_ 2564464881 N_PDU 0;
BA_ "GenSigTimeoutTime_TRSKM" SG_ 2564464881 N_PDU 0;
BA_ "GenSigTimeoutTime_BCM" SG_ 2564484337 N_PDU 0;
BA_ "GenSigTimeoutTime_BSM2" SG_ 2564484337 N_PDU 0;
BA_ "GenSigTimeoutTime_CADM2" SG_ 2564484337 N_PDU 0;
BA_ "GenSigTimeoutTime_CVADAS" SG_ 2564484337 N_PDU 0;
BA_ "GenSigTimeoutTime_EPS" SG_ 2564484337 N_PDU 0;
BA_ "GenSigTimeoutTime_ORC" SG_ 2564484337 N_PDU 0;
BA_ "GenSigTimeoutTime_PAM" SG_ 2564484337 N_PDU 0;
BA_ "GenSigTimeoutTime_SGW" SG_ 2564484337 N_PDU 0;
BA_ "GenSigTimeoutTime_TRSKM" SG_ 2564484337 N_PDU 0;
BA_ "GenSigTimeoutTime_BCM" SG_ 2564485411 N_PDU 0;
BA_ "GenSigTimeoutTime_BSM2" SG_ 2564485411 N_PDU 0;
BA_ "GenSigTimeoutTime_CADM2" SG_ 2564485411 N_PDU 0;
BA_ "GenSigTimeoutTime_CVADAS" SG_ 2564485411 N_PDU 0;
BA_ "GenSigTimeoutTime_EPS" SG_ 2564485411 N_PDU 0;
BA_ "GenSigTimeoutTime_ORC" SG_ 2564485411 N_PDU 0;
BA_ "GenSigTimeoutTime_PAM" SG_ 2564485411 N_PDU 0;
BA_ "GenSigTimeoutTime_SGW" SG_ 2564485411 N_PDU 0;
BA_ "GenSigTimeoutTime_TRSKM" SG_ 2564485411 N_PDU 0;
BA_ "GenSigTimeoutTime_BCM" SG_ 2564485423 N_PDU 0;
BA_ "GenSigTimeoutTime_BSM2" SG_ 2564485423 N_PDU 0;
BA_ "GenSigTimeoutTime_CADM2" SG_ 2564485423 N_PDU 0;
BA_ "GenSigTimeoutTime_CVADAS" SG_ 2564485423 N_PDU 0;
BA_ "GenSigTimeoutTime_EPS" SG_ 2564485423 N_PDU 0;
BA_ "GenSigTimeoutTime_ORC" SG_ 2564485423 N_PDU 0;
BA_ "GenSigTimeoutTime_PAM" SG_ 2564485423 N_PDU 0;
BA_ "GenSigTimeoutTime_SGW" SG_ 2564485423 N_PDU 0;
BA_ "GenSigTimeoutTime_TRSKM" SG_ 2564485423 N_PDU 0;
BA_ "GenSigTimeoutTime_BCM" SG_ 2564485424 N_PDU 0;
BA_ "GenSigTimeoutTime_BSM2" SG_ 2564485424 N_PDU 0;
BA_ "GenSigTimeoutTime_CADM2" SG_ 2564485424 N_PDU 0;
BA_ "GenSigTimeoutTime_CVADAS" SG_ 2564485424 N_PDU 0;
BA_ "GenSigTimeoutTime_EPS" SG_ 2564485424 N_PDU 0;
BA_ "GenSigTimeoutTime_ORC" SG_ 2564485424 N_PDU 0;
BA_ "GenSigTimeoutTime_PAM" SG_ 2564485424 N_PDU 0;
BA_ "GenSigTimeoutTime_SGW" SG_ 2564485424 N_PDU 0;
BA_ "GenSigTimeoutTime_TRSKM" SG_ 2564485424 N_PDU 0;
BA_ "GenSigTimeoutTime_BCM" SG_ 2564485667 N_PDU 0;
BA_ "GenSigTimeoutTime_BSM2" SG_ 2564485667 N_PDU 0;
BA_ "GenSigTimeoutTime_CADM2" SG_ 2564485667 N_PDU 0;
BA_ "GenSigTimeoutTime_CVADAS" SG_ 2564485667 N_PDU 0;
BA_ "GenSigTimeoutTime_EPS" SG_ 2564485667 N_PDU 0;
BA_ "GenSigTimeoutTime_ORC" SG_ 2564485667 N_PDU 0;
BA_ "GenSigTimeoutTime_PAM" SG_ 2564485667 N_PDU 0;
BA_ "GenSigTimeoutTime_SGW" SG_ 2564485667 N_PDU 0;
BA_ "GenSigTimeoutTime_TRSKM" SG_ 2564485667 N_PDU 0;
BA_ "GenSigTimeoutTime_BCM" SG_ 2564485679 N_PDU 0;
BA_ "GenSigTimeoutTime_BSM2" SG_ 2564485679 N_PDU 0;
BA_ "GenSigTimeoutTime_CADM2" SG_ 2564485679 N_PDU 0;
BA_ "GenSigTimeoutTime_CVADAS" SG_ 2564485679 N_PDU 0;
BA_ "GenSigTimeoutTime_EPS" SG_ 2564485679 N_PDU 0;
BA_ "GenSigTimeoutTime_ORC" SG_ 2564485679 N_PDU 0;
BA_ "GenSigTimeoutTime_PAM" SG_ 2564485679 N_PDU 0;
BA_ "GenSigTimeoutTime_SGW" SG_ 2564485679 N_PDU 0;
BA_ "GenSigTimeoutTime_TRSKM" SG_ 2564485679 N_PDU 0;
BA_ "GenSigTimeoutTime_BCM" SG_ 2564485680 N_PDU 0;
BA_ "GenSigTimeoutTime_BSM2" SG_ 2564485680 N_PDU 0;
BA_ "GenSigTimeoutTime_CADM2" SG_ 2564485680 N_PDU 0;
BA_ "GenSigTimeoutTime_CVADAS" SG_ 2564485680 N_PDU 0;
BA_ "GenSigTimeoutTime_EPS" SG_ 2564485680 N_PDU 0;
BA_ "GenSigTimeoutTime_ORC" SG_ 2564485680 N_PDU 0;
BA_ "GenSigTimeoutTime_PAM" SG_ 2564485680 N_PDU 0;
BA_ "GenSigTimeoutTime_SGW" SG_ 2564485680 N_PDU 0;
BA_ "GenSigTimeoutTime_TRSKM" SG_ 2564485680 N_PDU 0;
BA_ "GenSigTimeoutTime_BCM" SG_ 2564485824 N_PDU 0;
BA_ "GenSigTimeoutTime_BSM2" SG_ 2564485824 N_PDU 0;
BA_ "GenSigTimeoutTime_CADM2" SG_ 2564485824 N_PDU 0;
BA_ "GenSigTimeoutTime_CVADAS" SG_ 2564485824 N_PDU 0;
BA_ "GenSigTimeoutTime_EPS" SG_ 2564485824 N_PDU 0;
BA_ "GenSigTimeoutTime_ORC" SG_ 2564485824 N_PDU 0;
BA_ "GenSigTimeoutTime_PAM" SG_ 2564485824 N_PDU 0;
BA_ "GenSigTimeoutTime_SGW" SG_ 2564485824 N_PDU 0;
BA_ "GenSigTimeoutTime_TRSKM" SG_ 2564485824 N_PDU 0;
BA_ "GenSigTimeoutTime_BCM" SG_ 2564485792 N_PDU 0;
BA_ "GenSigTimeoutTime_BSM2" SG_ 2564485792 N_PDU 0;
BA_ "GenSigTimeoutTime_CADM2" SG_ 2564485792 N_PDU 0;
BA_ "GenSigTimeoutTime_CVADAS" SG_ 2564485792 N_PDU 0;
BA_ "GenSigTimeoutTime_EPS" SG_ 2564485792 N_PDU 0;
BA_ "GenSigTimeoutTime_ORC" SG_ 2564485792 N_PDU 0;
BA_ "GenSigTimeoutTime_PAM" SG_ 2564485792 N_PDU 0;
BA_ "GenSigTimeoutTime_SGW" SG_ 2564485792 N_PDU 0;
BA_ "GenSigTimeoutTime_TRSKM" SG_ 2564485792 N_PDU 0;
BA_ "GenSigTimeoutTime_BCM" SG_ 2564485868 N_PDU 0;
BA_ "GenSigTimeoutTime_BSM2" SG_ 2564485868 N_PDU 0;
BA_ "GenSigTimeoutTime_CADM2" SG_ 2564485868 N_PDU 0;
BA_ "GenSigTimeoutTime_CVADAS" SG_ 2564485868 N_PDU 0;
BA_ "GenSigTimeoutTime_EPS" SG_ 2564485868 N_PDU 0;
BA_ "GenSigTimeoutTime_ORC" SG_ 2564485868 N_PDU 0;
BA_ "GenSigTimeoutTime_PAM" SG_ 2564485868 N_PDU 0;
BA_ "GenSigTimeoutTime_SGW" SG_ 2564485868 N_PDU 0;
BA_ "GenSigTimeoutTime_TRSKM" SG_ 2564485868 N_PDU 0;
BA_ "GenSigTimeoutTime_BCM" SG_ 2564486447 N_PDU 0;
BA_ "GenSigTimeoutTime_BSM2" SG_ 2564486447 N_PDU 0;
BA_ "GenSigTimeoutTime_CADM2" SG_ 2564486447 N_PDU 0;
BA_ "GenSigTimeoutTime_CVADAS" SG_ 2564486447 N_PDU 0;
BA_ "GenSigTimeoutTime_EPS" SG_ 2564486447 N_PDU 0;
BA_ "GenSigTimeoutTime_ORC" SG_ 2564486447 N_PDU 0;
BA_ "GenSigTimeoutTime_PAM" SG_ 2564486447 N_PDU 0;
BA_ "GenSigTimeoutTime_SGW" SG_ 2564486447 N_PDU 0;
BA_ "GenSigTimeoutTime_TRSKM" SG_ 2564486447 N_PDU 0;
BA_ "GenSigTimeoutTime_BCM" SG_ 2564486448 N_PDU 0;
BA_ "GenSigTimeoutTime_BSM2" SG_ 2564486448 N_PDU 0;
BA_ "GenSigTimeoutTime_CADM2" SG_ 2564486448 N_PDU 0;
BA_ "GenSigTimeoutTime_CVADAS" SG_ 2564486448 N_PDU 0;
BA_ "GenSigTimeoutTime_EPS" SG_ 2564486448 N_PDU 0;
BA_ "GenSigTimeoutTime_ORC" SG_ 2564486448 N_PDU 0;
BA_ "GenSigTimeoutTime_PAM" SG_ 2564486448 N_PDU 0;
BA_ "GenSigTimeoutTime_SGW" SG_ 2564486448 N_PDU 0;
BA_ "GenSigTimeoutTime_TRSKM" SG_ 2564486448 N_PDU 0;
BA_ "GenSigTimeoutTime_BCM" SG_ 2564486592 N_PDU 0;
BA_ "GenSigTimeoutTime_BSM2" SG_ 2564486592 N_PDU 0;
BA_ "GenSigTimeoutTime_CADM2" SG_ 2564486592 N_PDU 0;
BA_ "GenSigTimeoutTime_CVADAS" SG_ 2564486592 N_PDU 0;
BA_ "GenSigTimeoutTime_EPS" SG_ 2564486592 N_PDU 0;
BA_ "GenSigTimeoutTime_ORC" SG_ 2564486592 N_PDU 0;
BA_ "GenSigTimeoutTime_PAM" SG_ 2564486592 N_PDU 0;
BA_ "GenSigTimeoutTime_SGW" SG_ 2564486592 N_PDU 0;
BA_ "GenSigTimeoutTime_TRSKM" SG_ 2564486592 N_PDU 0;
BA_ "GenSigTimeoutTime_BCM" SG_ 2564485568 N_PDU 0;
BA_ "GenSigTimeoutTime_BSM2" SG_ 2564485568 N_PDU 0;
BA_ "GenSigTimeoutTime_CADM2" SG_ 2564485568 N_PDU 0;
BA_ "GenSigTimeoutTime_CVADAS" SG_ 2564485568 N_PDU 0;
BA_ "GenSigTimeoutTime_EPS" SG_ 2564485568 N_PDU 0;
BA_ "GenSigTimeoutTime_ORC" SG_ 2564485568 N_PDU 0;
BA_ "GenSigTimeoutTime_PAM" SG_ 2564485568 N_PDU 0;
BA_ "GenSigTimeoutTime_SGW" SG_ 2564485568 N_PDU 0;
BA_ "GenSigTimeoutTime_TRSKM" SG_ 2564485568 N_PDU 0;
BA_ "GenSigTimeoutTime_BCM" SG_ 2564485536 N_PDU 0;
BA_ "GenSigTimeoutTime_BSM2" SG_ 2564485536 N_PDU 0;
BA_ "GenSigTimeoutTime_CADM2" SG_ 2564485536 N_PDU 0;
BA_ "GenSigTimeoutTime_CVADAS" SG_ 2564485536 N_PDU 0;
BA_ "GenSigTimeoutTime_EPS" SG_ 2564485536 N_PDU 0;
BA_ "GenSigTimeoutTime_ORC" SG_ 2564485536 N_PDU 0;
BA_ "GenSigTimeoutTime_PAM" SG_ 2564485536 N_PDU 0;
BA_ "GenSigTimeoutTime_SGW" SG_ 2564485536 N_PDU 0;
BA_ "GenSigTimeoutTime_TRSKM" SG_ 2564485536 N_PDU 0;
BA_ "GenSigTimeoutTime_BCM" SG_ 2564485612 N_PDU 0;
BA_ "GenSigTimeoutTime_BSM2" SG_ 2564485612 N_PDU 0;
BA_ "GenSigTimeoutTime_CADM2" SG_ 2564485612 N_PDU 0;
BA_ "GenSigTimeoutTime_CVADAS" SG_ 2564485612 N_PDU 0;
BA_ "GenSigTimeoutTime_EPS" SG_ 2564485612 N_PDU 0;
BA_ "GenSigTimeoutTime_ORC" SG_ 2564485612 N_PDU 0;
BA_ "GenSigTimeoutTime_PAM" SG_ 2564485612 N_PDU 0;
BA_ "GenSigTimeoutTime_SGW" SG_ 2564485612 N_PDU 0;
BA_ "GenSigTimeoutTime_TRSKM" SG_ 2564485612 N_PDU 0;
VAL_ 1051 FUEL_VOLT 255 "SNA" ;
VAL_ 1375 ChkFuelLevelSts 0 "Fault_Not_Present" 1 "Chk_Code_1" 2 "Chk_Code_2" 3 "Chk_Code_3" 4 "Chk_Code_4" 5 "Not_Used" 6 "Not_Used" 7 "Not_Used" ;
VAL_ 1375 FrontWiperReq 0 "OFF" 1 "INT" 2 "LOW" 3 "HIGH" 4 "AUTO" 5 "MIST" ;
VAL_ 1066 BonnetSts 0 "Closed" 1 "Open" ;
VAL_ 1066 BrakeFluidLevelSts 0 "OK" 1 "Low_level" ;
VAL_ 1066 DoorLockLastElSts 0 "Locked" 1 "Driver_Door_Unlocked" 2 "All_Door_Unlocked" 3 "SNA" ;
VAL_ 1066 DriverDoorSts 0 "Closed" 1 "Open" ;
VAL_ 1066 ExternalTemperature 511 "SNA" ;
VAL_ 1066 FrontWiperMoveSts 0 "Stop" 1 "Moving" ;
VAL_ 1066 FuelLevel 255 "SNA" ;
VAL_ 1066 HDCFnRqstSts 0 "Open" 1 "Closed" 3 "SNA" ;
VAL_ 1066 HighBeamSts 0 "OFF" 1 "ON" ;
VAL_ 1066 LHRDoorSts 0 "Closed" 1 "Open" ;
VAL_ 1066 LowBeamSts 0 "OFF" 1 "ON" ;
VAL_ 1066 LowFuelWarningSts 0 "OFF" 1 "ON" ;
VAL_ 1066 ParkBrakeSts 0 "OFF" 1 "ON" ;
VAL_ 1066 PowerModeSts 0 "Standard_Power" 1 "Logistic_Mode_ON" 2 "Logistic_Mode_PR" 3 "LogisticModeON_and_EngineON" ;
VAL_ 1066 PsngrDoorSts 0 "Closed" 1 "Open" ;
VAL_ 1066 RHatchSts 0 "Closed" 1 "Open" ;
VAL_ 1066 RHRDoorSts 0 "Closed" 1 "Open" ;
VAL_ 1066 StopLightFault 0 "False" 1 "True" ;
VAL_ 1066 StopLightSts 0 "OFF" 1 "ON" ;
VAL_ 513 BrkTrq 32767 "SNA" ;
VAL_ 513 BrkTrq_Driver 32767 "SNA" ;
VAL_ 513 REF_VEH_SPEED 1023 "SNA" ;
VAL_ 513 SelSpdLmp 0 "OFF" 1 "CONT" 2 "BLINK" 3 "SNA" ;
VAL_ 513 VehicleStandStillSts 0 "True" 1 "False" 3 "SNA" ;
VAL_ 258 ABSActive 0 "Not_active" 1 "Active" ;
VAL_ 258 BrakeBoostPressure 2047 "SNA" ;
VAL_ 258 BrakeInterventionSts 0 "No_active_brake_intervention" 1 "Active_brake_intervention" ;
VAL_ 258 BrakePedalPressure 2047 "SNA" ;
VAL_ 258 Brk_Stat 0 "IDLE" 1 "BRAKING" 2 "NDEF2" 3 "SNA" ;
VAL_ 258 BSM_ESASystemSts 0 "Not_Enabled" 1 "Pending" 2 "Pre_Active" 3 "Active" 4 "Locked" 5 "Temporarily_Not_Avail" 6 "Permanently_Not_Avail" 7 "SNA" ;
VAL_ 258 ESCActive 0 "Not_active" 1 "Active" ;
VAL_ 258 HBAActive 0 "Not_Active" 1 "Active" ;
VAL_ 258 HillHolderActive 0 "Not_Active" 1 "Active" ;
VAL_ 258 InternalError_BSM 0 "No_int_processing_error_detected" 1 "Int_processing_error_detected" ;
VAL_ 258 LatAcceleration_BSM 4095 "SNA" ;
VAL_ 258 LatAccelerationFailSts_BSM 0 "Fail_Not_Present" 1 "Fail_Present" ;
VAL_ 258 LongAcceleration_BSM 4095 "SNA" ;
VAL_ 258 LongAccelerationFailSts_BSM 0 "Fail_Not_Present" 1 "Fail_Present" ;
VAL_ 258 VehicleSpeedVSOSig 8191 "SNA" ;
VAL_ 258 WheelRPM_FL 65535 "SNA" ;
VAL_ 258 WheelRPM_FR 65535 "SNA" ;
VAL_ 258 YawRate_BSM 4095 "SNA" ;
VAL_ 258 YawRateFailSts_BSM 0 "Fail_Not_Present" 1 "Fail_Present" ;
VAL_ 259 LatAccelerationOffset_BSM 255 "SNA" ;
VAL_ 259 LHF_FastPulseCounter 255 "SNA" ;
VAL_ 259 LHF_Spin 0 "Stand_Still" 1 "Forward" 2 "Backward" 3 "SNA" ;
VAL_ 259 LHF_WheelSensorFailSts 0 "Fail_Not_Present" 1 "Fail_Present" ;
VAL_ 259 LHFWheelSpeed 8191 "SNA" ;
VAL_ 259 LHR_FastPulseCounter 255 "SNA" ;
VAL_ 259 LHR_Spin 0 "Stand_Still" 1 "Forward" 2 "Backward" 3 "SNA" ;
VAL_ 259 LHR_WheelSensorFailSts 0 "Fail_Not_Present" 1 "Fail_Present" ;
VAL_ 259 LHRWheelSpeed 8191 "SNA" ;
VAL_ 259 LongAccelerationOffset_BSM 255 "SNA" ;
VAL_ 259 RHF_FastPulseCounter 255 "SNA" ;
VAL_ 259 RHF_Spin 0 "Stand_Still" 1 "Forward" 2 "Backward" 3 "SNA" ;
VAL_ 259 RHF_WheelSensorFailSts 0 "Fail_Not_Present" 1 "Fail_Present" ;
VAL_ 259 RHFWheelSpeed 8191 "SNA" ;
VAL_ 259 RHR_FastPulseCounter 255 "SNA" ;
VAL_ 259 RHR_Spin 0 "Stand_Still" 1 "Forward" 2 "Backward" 3 "SNA" ;
VAL_ 259 RHR_WheelSensorFailSts 0 "Fail_Not_Present" 1 "Fail_Present" ;
VAL_ 259 RHRWheelSpeed 8191 "SNA" ;
VAL_ 609 ClampForce 0 "Initialization" 511 "SNA" ;
VAL_ 609 EPBSts 0 "Released" 1 "Applied" 2 "DynamicBrkESC" 3 "DynamicBrkEPB" 4 "Emergency_Braking" 5 "Applying" 6 "Maintenance_Mode" 7 "Assembly_Check" 8 "Inspection_Mode" 9 "Re_Clamping" 10 "Adjuste_Mode" 11 "Releasing" 12 "Fault_EPB_Released" 13 "Fault_EPB_Applied" 14 "Fault_Present" 15 "SNA" ;
VAL_ 609 EPBSwitchPosition 0 "No request" 1 "Release request" 2 "Apply request" 3 "Error" ;
VAL_ 609 EPBWarningLampReq 0 "OFF" 1 "CONT" 2 "BLINK" 3 "SNA" ;
VAL_ 609 ESC_OFF_Hrd_Sft_Button_sts 0 "STREET" 1 "SPORT" 2 "TRACK" 3 "OFF" 4 "SNOW" 5 "OFFROAD" 7 "SNA" ;
VAL_ 609 MSRActive 0 "Not_Active" 1 "Active" ;
VAL_ 1155 ABSFailSts 0 "Fail_Not_Present" 1 "Fail_Present" ;
VAL_ 1155 BSM_THA_Brk_Resp 0 "Off" 1 "Active" 2 "Brakes Overheated" 3 "SNA" ;
VAL_ 1155 EBDFailSts 0 "Fail_Not_Present" 1 "Fail_Present" ;
VAL_ 1155 ERMActive 0 "Not_Active" 1 "Active" ;
VAL_ 1155 ESCFailSts 0 "Fail_Not_Present" 1 "Fail_Present" ;
VAL_ 1155 ESCIntervention 0 "No_intervention" 1 "Intervention_blinking_lamp" ;
VAL_ 1155 Function2Sts 0 "Not_Active" 1 "Active" ;
VAL_ 1155 TSCActive 0 "Not_Active" 1 "Active" ;
VAL_ 514 BrakePdlPosn 255 "SNA" ;
VAL_ 514 BrkPdl_Flt 0 "NOT FAULTED" 1 "FAULTED" ;
VAL_ 514 BrkPdl_Stat 0 "UPSTOP" 1 "PSD" 2 "NDEF2" 3 "SNA" ;
VAL_ 514 BSM_OpStat 0 "Inactive" 1 "FullService" 2 "FailOperational" 3 "FailDegraded" 4 "Emergency" 5 "No_Function" ;
VAL_ 514 BSM_ReadyForESS 0 "Not_Ready" 1 "Ready" 2 "Active" 3 "SNA" ;
VAL_ 514 PAM_Brk_Rq_RspSts 0 "Not_Active" 1 "Active" 2 "Faulted_Condition" 3 "SNA" ;
VAL_ 514 Rear_Diff_BSM_RQ 0 "FREE" 1 "HOLD" 2 "OPEN" 3 "SNA" ;
VAL_ 257 ABSActive_B2 0 "Not_active" 1 "Active" ;
VAL_ 257 Brk_Stat_B2 0 "IDLE" 1 "BRAKING" 2 "NDEF2" 3 "SNA" ;
VAL_ 257 Ft_RrAxleCoupling_TrqRq_B2 255 "SNA" ;
VAL_ 257 Ft_RrTrqCoupling_ModeRq_B2 0 "FREE" 1 "HOLD" 2 "OPEN" 3 "SNA" ;
VAL_ 257 Inlet_Pressure_Pos 0 "False" 1 "True" 3 "SNA" ;
VAL_ 257 LHF_FastPulseCounter_B2 255 "SNA" ;
VAL_ 257 LHF_Spin_B2 0 "Stand_Still" 1 "Forward" 2 "Backward" 3 "SNA" ;
VAL_ 257 LHF_WheelSensorFailSts_B2 0 "Fail_Not_Present" 1 "Fail_Present" ;
VAL_ 257 LHFWheelSpeed_B2 8191 "SNA" ;
VAL_ 257 R_DIFF_TRQ_RQ_B2 511 "SNA" ;
VAL_ 257 Rear_Diff_BSM_RQ_B2 0 "FREE" 1 "HOLD" 2 "OPEN" 3 "SNA" ;
VAL_ 257 RHF_FastPulseCounter_B2 255 "SNA" ;
VAL_ 257 RHF_Spin_B2 0 "Stand_Still" 1 "Forward" 2 "Backward" 3 "SNA" ;
VAL_ 257 RHF_WheelSensorFailSts_B2 0 "Fail_Not_Present" 1 "Fail_Present" ;
VAL_ 257 RHFWheelSpeed_B2 8191 "SNA" ;
VAL_ 257 VehicleSpeedVSOSig_B2 8191 "SNA" ;
VAL_ 524 AEB_Type_Brk_B2 0 "NONE" 1 "ACC" 2 "CMS" 3 "CMS_XTD" 4 "ABA" 5 "LSCM" 6 "PEB" 7 "ICA_L" 8 "ICA_R" 9 "HAS_MRM" 15 "SNA" ;
VAL_ 524 Brake_OpStat_Sec 0 "Inactive" 1 "FullService" 2 "FailOperational" 3 "FailDegraded" 4 "Emergency" 5 "No_Function" ;
VAL_ 524 BrkTrq_B2 32767 "SNA" ;
VAL_ 524 BSM2_Long_DTO 0 "FALSE" 1 "TRUE" ;
VAL_ 524 BSM2_OpStat 0 "Inactive" 1 "FullService" 2 "FailOperational" 3 "FailDegraded" 4 "Emergency" 5 "No_Function" ;
VAL_ 524 VehicleStandStillSts_B2 0 "True" 1 "False" 3 "SNA" ;
VAL_ 1156 ABSFailSts_B2 0 "Fail_Not_Present" 1 "Fail_Present" ;
VAL_ 1156 RollsModeAct_B2 0 "No Fault" 1 "Fault" ;
VAL_ 275 PPPA_TurnIndicatorRqst 0 "Idle" 1 "Right" 2 "Left" 3 "SNA" ;
VAL_ 275 RR_PAM_Brk_RqSts 0 "Off" 1 "On" ;
VAL_ 275 RR_PAM_Dist 1023 "SNA" ;
VAL_ 275 RR_PAM_StopControlSts 0 "Off" 1 "On" ;
VAL_ 950 Alert_CHF 0 "No_object_detected" 1 "1_Arc" 2 "2_Arc" 3 "3_Arc" 4 "4_Arc" 5 "5_Arc" 6 "6_Arc" 7 "SNA" ;
VAL_ 950 Alert_CHR 0 "No_object_detected" 1 "1_Arc" 2 "2_Arc" 3 "3_Arc" 4 "4_Arc" 5 "5_Arc" 6 "6_Arc" 7 "SNA" ;
VAL_ 950 Alert_LHF 0 "No_object_detected" 1 "1_Arc" 2 "2_Arc" 7 "SNA" ;
VAL_ 950 Alert_LHR 0 "No_object_detected" 1 "1_Arc" 2 "2_Arc" 7 "SNA" ;
VAL_ 950 Alert_RHF 0 "No_object_detected" 1 "1_Arc" 2 "2_Arc" 7 "SNA" ;
VAL_ 950 Alert_RHR 0 "No_object_detected" 1 "1_Arc" 2 "2_Arc" 7 "SNA" ;
VAL_ 950 AUXCamsRQSts 0 "Not_Pressed" 1 "Pressed" ;
VAL_ 950 ChimeActivation_LHF 0 "NotActive" 1 "Active" ;
VAL_ 950 ChimeActivation_LHR 0 "NotActive" 1 "Active" ;
VAL_ 950 ChimeActivation_RHF 0 "NotActive" 1 "Active" ;
VAL_ 950 ChimeActivation_RHR 0 "NotActive" 1 "Active" ;
VAL_ 950 DisplayView2 0 "OFF" 1 "VIEW_1" 2 "VIEW_2" 3 "VIEW_3" 4 "VIEW_4" 5 "VIEW_5" 6 "VIEW_6" 7 "VIEW_7" 8 "VIEW_8" 9 "VIEW_9" 10 "VIEW_10" 11 "VIEW_11" 12 "VIEW_12" 13 "VIEW_13" 14 "VIEW_14" 15 "VIEW_15" ;
VAL_ 950 FrontSensorSts 0 "Active" 1 "Not_Active_blocked" 2 "Not_Active_failure" 3 "SNA" ;
VAL_ 950 FT_PAM_LedControlSts 0 "Off" 1 "Continuous Light" 2 "2Blinking Light" 3 "SNA" ;
VAL_ 950 Graphic_CHF 0 "Slow_flash" 1 "Solid" 2 "None" 3 "SNA" ;
VAL_ 950 Graphic_CHR 0 "Slow_flash" 1 "Solid" 2 "None" 3 "SNA" ;
VAL_ 950 Graphic_LHF 0 "Slow_flash" 1 "Solid" 2 "None" 3 "SNA" ;
VAL_ 950 Graphic_LHR 0 "Slow_flash" 1 "Solid" 2 "None" 3 "SNA" ;
VAL_ 950 Graphic_RHF 0 "Slow_flash" 1 "Solid" 2 "None" 3 "SNA" ;
VAL_ 950 Graphic_RHR 0 "Slow_flash" 1 "Solid" 2 "None" 3 "SNA" ;
VAL_ 950 ImageDefeatRQSts 0 "NOT PRESSED" 1 "PRESSED" ;
VAL_ 950 MoreCamsRQSts 0 "Not_Pressed" 1 "Pressed" ;
VAL_ 950 PAM_CHIME_REP_RATESts 0 "Continuous_0_Hz" 2 "Slow_2_Hz" 3 "Slow_3_Hz" 4 "Fast_4_Hz" 5 "Fast_5_Hz" ;
VAL_ 950 PAM_CHIME_TYPE 0 "None" 1 "Type_1" 2 "Type_2" 3 "Type_3" 4 "Type_4" 5 "Type_5" 6 "Type_6" 7 "Type_7" 8 "Type_8" 9 "Type_9" 10 "Type_10" 11 "Type_11" 12 "Type_12" 13 "Type_13" 14 "Type_14" 15 "Type_15" ;
VAL_ 950 PAM_LedControlSts 0 "Off" 1 "Continuous light" 2 "Blinking light" 3 "SNA" ;
VAL_ 950 PAM_Off_Status 0 "SYSTEM_ON" 1 "SYSTEM_OFF" ;
VAL_ 950 PAM_Off_Status_2BT 0 "FT_OFF_RR_OFF" 1 "FT_OFF_RR_ON" 2 "FT_ON_RR_OFF" 3 "FT_ON_RR_ON" ;
VAL_ 950 PAM_PopUpRqst 0 "TM0" 1 "TM1" 2 "TM2" 3 "TM3" 4 "TM4" 5 "TM5" 6 "TM6" 7 "TM7" 8 "TM8" 9 "TM9" 10 "TM10" 11 "TM11" 12 "TM12" 13 "TM13" 14 "TM14" 15 "TM15" 16 "TM16" 17 "TM17" 18 "TM18" 19 "TM19" 20 "TM20" 21 "TM21" 22 "TM22" 23 "TM23" 24 "TM24" 25 "TM25" 26 "TM26" 27 "TM27" 28 "TM28" 29 "TM29" 30 "TM30" 31 "TM31" 32 "TM32" 33 "TM33" 34 "TM34" 35 "TM35" 36 "TM36" 37 "TM37" 38 "TM38" 39 "TM39" 40 "TM40" 41 "TM41" 42 "TM42" 43 "TM43" 44 "TM44" 45 "TM45" 46 "TM46" 47 "TM47" 48 "TM48" 49 "TM49" 50 "TM50" 51 "TM51" 52 "TM52" 53 "TM53" 54 "TM54" 55 "TM55" 56 "TM56" 57 "TM57" 58 "TM58" 59 "TM59" 60 "TM60" 61 "TM61" 62 "TM62" 63 "TM63" 64 "TM64" 65 "TM65" 66 "TM66" 67 "TM67" 68 "TM68" 69 "TM69" 70 "TM70" 71 "TM71" 72 "TM72" 73 "TM73" 74 "TM74" 75 "TM75" 76 "TM76" 77 "TM77" 78 "TM78" 79 "TM79" 80 "TM80" 81 "TM81" 82 "TM82" 83 "TM83" 84 "TM84" 85 "TM85" 86 "TM86" 87 "TM87" 88 "TM88" 89 "TM89" 90 "TM90" 91 "TM91" 92 "TM92" 93 "TM93" 94 "TM94" 95 "TM95" 96 "TM96" 97 "TM97" 98 "TM98" 99 "TM99" 100 "TM100" 255 "SNA" ;
VAL_ 950 PAM_Volume 0 "None" 1 "Low" 2 "Medium" 3 "High" ;
VAL_ 950 PAMSystemFault 0 "False" 1 "Temporary_Failure" 2 "External_Failure" 3 "System_Failure" ;
VAL_ 950 ParkingManeuverActive 0 "Idle" 1 "Enabled_Seeking" 2 "Engaged_Semi" 3 "Engaged_Full" 4 "Not_Used" 5 "Not_Used" 6 "Not_Used" 7 "SNA" ;
VAL_ 950 RearSensorSts 0 "Active" 1 "Not_Active_blocked" 2 "Not_Active_failure" 3 "SNA" ;
VAL_ 950 SPM_LedControlSts 0 "Off" 1 "Continuous light" 2 "Blinking light" 3 "SNA" ;
VAL_ 950 SPM_Screen_Rqst 0 "Not_Active" 1 "Active" ;
VAL_ 950 SPMControlSts 0 "Not_Active" 1 "Active_ParallelParking" 2 "Active_PerpendicularParking" 3 "Active_OutParking" ;
VAL_ 950 SPMFailSts 0 "False" 1 "True" ;
VAL_ 950 SPMSystemFault 0 "False" 1 "True" ;
VAL_ 950 TRSC_LED_Stat 0 "OFF" 1 "Solid" 2 "Blinking" 3 "SNA" ;
VAL_ 161 BATTERY_voltage 255 "SNA" ;
VAL_ 161 BATTERY2_voltage 255 "SNA" ;
VAL_ 161 DBSM2_internal_error 0 "No_Error" 1 "Internal_Error" ;
VAL_ 161 ESS_input_active 0 "ESS_NotActivated" 1 "ESS_Activated" ;
VAL_ 161 L2plus_ack 0 "Inactive" 1 "L2plus_mode_active" ;
VAL_ 161 overcurrent_detected 0 "No_Fault" 1 "Over_Current" ;
VAL_ 161 overtemp_detected 0 "No_Fault" 1 "Over_Temp" ;
VAL_ 161 RsErr_DBSM2 0 "No_Error" 1 "Error" ;
VAL_ 161 switch_status_OpenClose 0 "Open" 1 "Close" ;
VAL_ 161 undervoltage_detected 0 "No_Fault" 1 "Under_Voltage" ;
